VERSION ""

NS_ :

BS_:

BU_: ETH

BO_ 1332 VCFRONT_alertLog: 8 Vector__XXX
 SG_ VCFRONT_alertID M : 0|10@1+ (1,0) [0|0] "" Vector__XXX
 SG_ VCFRONT_a583_switch1State m583 : 24|3@1+ (1,0) [0|0] "" Vector__XXX
 SG_ VCFRONT_a584_switch1Voltage m584 : 24|9@1+ (10,0) [0|0] "" Vector__XXX
 SG_ VCFRONT_a587_batterySMState m587 : 24|4@1+ (1,0) [0|0] "" Vector__XXX
 SG_ VCFRONT_a588_vcleftATerm m588 : 24|16@1+ (50,0) [0|0] "" Vector__XXX
 SG_ VCFRONT_a590_vcrightATerm m590 : 24|16@1+ (50,0) [0|0] "" Vector__XXX
 SG_ VCFRONT_a592_vcleftCutoffATerm m592 : 24|16@1+ (50,0) [0|0] "" Vector__XXX
 SG_ VCFRONT_a594_minOffsetFusionSession m594 : 24|8@1- (0.001,0) [0|0] "" Vector__XXX
 SG_ VCFRONT_a595_batterySMState m595 : 24|4@1+ (1,0) [0|0] "" Vector__XXX
 SG_ VCFRONT_a596_vcrightCutoffATerm m596 : 24|16@1+ (50,0) [0|0] "" Vector__XXX
 SG_ VCFRONT_a599_initialLVBatteryType m599 : 24|3@1+ (1,0) [0|0] "" Vector__XXX
 SG_ VCFRONT_a600_batterySMState m600 : 24|4@1+ (1,0) [0|0] "" Vector__XXX
 SG_ VCFRONT_a611_tempCoolantRadOutletEst m611 : 24|6@1+ (1,20) [0|0] "" Vector__XXX
 SG_ VCFRONT_a614_ptPumpFault m614 : 24|1@1+ (1,0) [0|0] "" Vector__XXX
 SG_ VCFRONT_a618_evapInTemp m618 : 24|6@1+ (1,0) [0|0] "" Vector__XXX
 SG_ VCFRONT_a626_elevatedDcrThreshold m626 : 24|4@1+ (0.5,12) [0|0] "" Vector__XXX
 SG_ VCFRONT_a628_lastNominalTemp m628 : 24|8@1+ (0.5,-20) [0|0] "" Vector__XXX
 SG_ VCFRONT_a635_readyToSleepFailed m635 : 24|1@1+ (1,0) [0|0] "" Vector__XXX
 SG_ VCFRONT_a644_washpumpCycleSuccessEstimate m644 : 24|1@1+ (1,0) [0|0] "" Vector__XXX
 SG_ VCFRONT_a645_averageUnprimedFluidCurrent m645 : 24|8@1- (0.0984251968503937,5.807086614173229) [0|0] "" Vector__XXX
 SG_ VCFRONT_a646_timeDeltaBetweenComputations_min m646 : 24|14@1+ (1,0) [0|0] "" Vector__XXX
 SG_ VCFRONT_a663_hcmlGroupsHighWaterMarkPercent_IC400 m663 : 24|5@1+ (3.225806451612903,0) [0|0] "" Vector__XXX
 SG_ VCFRONT_a664_hcmrGroupsHighWaterMarkPercent_IC400 m664 : 24|5@1+ (3.225806451612903,0) [0|0] "" Vector__XXX
 SG_ VCFRONT_a665_isClearingFaults m665 : 24|1@1+ (1,0) [0|0] "" Vector__XXX
 SG_ VCFRONT_a666_isClearingFaults m666 : 24|1@1+ (1,0) [0|0] "" Vector__XXX
 SG_ VCFRONT_a667_country m667 : 24|16@1+ (1,0) [0|0] "" Vector__XXX
 SG_ VCFRONT_a668_country m668 : 24|16@1+ (1,0) [0|0] "" Vector__XXX
 SG_ VCFRONT_a009_abortedFaultTimeout m9 : 25|1@1+ (1,0) [0|0] "" Vector__XXX
 SG_ VCFRONT_a021_Task1000msLate m21 : 25|1@1+ (1,0) [0|0] "" Vector__XXX
 SG_ VCFRONT_a038_busMaster m38 : 25|4@1+ (1,0) [0|0] "" Vector__XXX
 SG_ VCFRONT_a047_Xres m47 : 25|1@1+ (1,0) [0|0] "" Vector__XXX
 SG_ VCFRONT_a089_VEH_party3 m89 : 25|1@1+ (1,0) [0|0] "" Vector__XXX
 SG_ VCFRONT_a098_PARTY_torque m98 : 25|1@1+ (1,0) [0|0] "" Vector__XXX
 SG_ VCFRONT_a104_PARTY_gpsAccuracies m104 : 25|1@1+ (1,0) [0|0] "" Vector__XXX
 SG_ VCFRONT_a107_PT_socStatus m107 : 25|1@1+ (1,0) [0|0] "" Vector__XXX
 SG_ VCFRONT_a108_PT_temperature m108 : 25|1@1+ (1,0) [0|0] "" Vector__XXX
 SG_ VCFRONT_a109_BDY_inertial2 m109 : 25|1@1+ (1,0) [0|0] "" Vector__XXX
 SG_ VCFRONT_a110_VEH_gearControl m110 : 25|1@1+ (1,0) [0|0] "" Vector__XXX
 SG_ VCFRONT_a111_VEH_seatStatus m111 : 25|1@1+ (1,0) [0|0] "" Vector__XXX
 SG_ VCFRONT_a112_PARTY_status m112 : 25|1@1+ (1,0) [0|0] "" Vector__XXX
 SG_ VCFRONT_a113_VEH_chassisControl m113 : 25|1@1+ (1,0) [0|0] "" Vector__XXX
 SG_ VCFRONT_a114_VEH_wheelRotation m114 : 25|1@1+ (1,0) [0|0] "" Vector__XXX
 SG_ VCFRONT_a116_VEH_seatHeatStatus m116 : 25|1@1+ (1,0) [0|0] "" Vector__XXX
 SG_ VCFRONT_a117_VEH_seatStatus m117 : 25|1@1+ (1,0) [0|0] "" Vector__XXX
 SG_ VCFRONT_a118_VEH_systemStatus m118 : 25|1@1+ (1,0) [0|0] "" Vector__XXX
 SG_ VCFRONT_a120_PARTY_status m120 : 25|1@1+ (1,0) [0|0] "" Vector__XXX
 SG_ VCFRONT_a142_isCoilOpenY m142 : 25|1@1+ (1,0) [0|0] "" Vector__XXX
 SG_ VCFRONT_a153_trunkOpen m153 : 25|1@1+ (1,0) [0|0] "" Vector__XXX
 SG_ VCFRONT_a160_faultValveEXV m160 : 25|1@1+ (1,0) [0|0] "" Vector__XXX
 SG_ VCFRONT_a161_tempSnsFaultIPM1 m161 : 25|1@1+ (1,0) [0|0] "" Vector__XXX
 SG_ VCFRONT_a171_PCSCPU2 m171 : 25|1@1+ (1,0) [0|0] "" Vector__XXX
 SG_ VCFRONT_a178_notRunInverterHot m178 : 25|1@1+ (1,0) [0|0] "" Vector__XXX
 SG_ VCFRONT_a182_factoryMode m182 : 25|1@1+ (1,0) [0|0] "" Vector__XXX
 SG_ VCFRONT_a183_factoryMode m183 : 25|1@1+ (1,0) [0|0] "" Vector__XXX
 SG_ VCFRONT_a187_partyBusRetryCount m187 : 25|9@1+ (1,0) [0|0] "" Vector__XXX
 SG_ VCFRONT_a191_IBSVoltage m191 : 25|8@1+ (0.08741903380905883,0) [0|0] "" Vector__XXX
 SG_ VCFRONT_a192_hvcEFuseStable m192 : 25|1@1+ (1,0) [0|0] "" Vector__XXX
 SG_ VCFRONT_a216_vcrightFastBlowDebounceImminent m216 : 25|1@1+ (1,0) [0|0] "" Vector__XXX
 SG_ VCFRONT_a284_isCoilOpenY m284 : 25|1@1+ (1,0) [0|0] "" Vector__XXX
 SG_ VCFRONT_a285_isCoilOpenY m285 : 25|1@1+ (1,0) [0|0] "" Vector__XXX
 SG_ VCFRONT_a286_isCoilOpenY m286 : 25|1@1+ (1,0) [0|0] "" Vector__XXX
 SG_ VCFRONT_a287_isCoilOpenY m287 : 25|1@1+ (1,0) [0|0] "" Vector__XXX
 SG_ VCFRONT_a288_isCoilOpenY m288 : 25|1@1+ (1,0) [0|0] "" Vector__XXX
 SG_ VCFRONT_a289_isCoilOpenY m289 : 25|1@1+ (1,0) [0|0] "" Vector__XXX
 SG_ VCFRONT_a365_heatPumpFlowRequest m365 : 25|1@1+ (1,0) [0|0] "" Vector__XXX
 SG_ VCFRONT_a366_sentryModeActive m366 : 25|1@1+ (1,0) [0|0] "" Vector__XXX
 SG_ VCFRONT_a427_endingSoc m427 : 25|9@1+ (0.2,0) [0|0] "" Vector__XXX
 SG_ VCFRONT_a446_compStandbySelfNotReady m446 : 25|1@1+ (1,0) [0|0] "" Vector__XXX
 SG_ VCFRONT_a447_lccSolenoidCompromised m447 : 25|1@1+ (1,0) [0|0] "" Vector__XXX
 SG_ VCFRONT_a462_HardwareOCLevel2 m462 : 25|1@1+ (1,0) [0|0] "" Vector__XXX
 SG_ VCFRONT_a476_FRM10_timedOut m476 : 25|1@1+ (1,0) [0|0] "" Vector__XXX
 SG_ VCFRONT_a477_cell2Voltage m477 : 25|9@1+ (0.01,0) [0|0] "" Vector__XXX
 SG_ VCFRONT_a480_unexpectedLock m480 : 25|1@1+ (1,0) [0|0] "" Vector__XXX
 SG_ VCFRONT_a481_outputOn m481 : 25|1@1+ (1,0) [0|0] "" Vector__XXX
 SG_ VCFRONT_a495_frunkOpen m495 : 25|1@1+ (1,0) [0|0] "" Vector__XXX
 SG_ VCFRONT_a499_DIFlowReq m499 : 25|1@1+ (1,0) [0|0] "" Vector__XXX
 SG_ VCFRONT_a529_disconnectedBatteryRunExpended m529 : 25|1@1+ (1,0) [0|0] "" Vector__XXX
 SG_ VCFRONT_a541_ChargeCurrentLimit m541 : 25|10@1+ (0.05,0) [0|0] "" Vector__XXX
 SG_ VCFRONT_a565_trunkOpen m565 : 25|1@1+ (1,0) [0|0] "" Vector__XXX
 SG_ VCFRONT_a614_ranFanRpm m614 : 25|1@1+ (1,0) [0|0] "" Vector__XXX
 SG_ VCFRONT_a627_cell2Voltage m627 : 25|9@1+ (0.01,0) [0|0] "" Vector__XXX
 SG_ VCFRONT_a635_requestSleepFailed m635 : 25|1@1+ (1,0) [0|0] "" Vector__XXX
 SG_ VCFRONT_a644_fluidLowEstimate m644 : 25|1@1+ (1,0) [0|0] "" Vector__XXX
 SG_ VCFRONT_a009_abortedRetryLimited m9 : 26|1@1+ (1,0) [0|0] "" Vector__XXX
 SG_ VCFRONT_a021_Task1000msStarved m21 : 26|1@1+ (1,0) [0|0] "" Vector__XXX
 SG_ VCFRONT_a047_Bodvddd m47 : 26|1@1+ (1,0) [0|0] "" Vector__XXX
 SG_ VCFRONT_a098_PT_thermalControl m98 : 26|1@1+ (1,0) [0|0] "" Vector__XXX
 SG_ VCFRONT_a104_CH_status m104 : 26|1@1+ (1,0) [0|0] "" Vector__XXX
 SG_ VCFRONT_a107_VEH_socStatus m107 : 26|1@1+ (1,0) [0|0] "" Vector__XXX
 SG_ VCFRONT_a108_PT_thermalControl m108 : 26|1@1+ (1,0) [0|0] "" Vector__XXX
 SG_ VCFRONT_a109_BDY_status m109 : 26|1@1+ (1,0) [0|0] "" Vector__XXX
 SG_ VCFRONT_a110_VEH_canLogAvailability m110 : 26|1@1+ (1,0) [0|0] "" Vector__XXX
 SG_ VCFRONT_a111_PARTY_status m111 : 26|1@1+ (1,0) [0|0] "" Vector__XXX
 SG_ VCFRONT_a112_CH_status m112 : 26|1@1+ (1,0) [0|0] "" Vector__XXX
 SG_ VCFRONT_a113_VEH_trackModeSettings m113 : 26|1@1+ (1,0) [0|0] "" Vector__XXX
 SG_ VCFRONT_a114_PARTY_brakeTorque m114 : 26|1@1+ (1,0) [0|0] "" Vector__XXX
 SG_ VCFRONT_a116_VEH_restraintStatus m116 : 26|1@1+ (1,0) [0|0] "" Vector__XXX
 SG_ VCFRONT_a117_BDY_falconSwitchStatus m117 : 26|1@1+ (1,0) [0|0] "" Vector__XXX
 SG_ VCFRONT_a118_PARTY_LVPowerState m118 : 26|1@1+ (1,0) [0|0] "" Vector__XXX
 SG_ VCFRONT_a120_PT_speed m120 : 26|1@1+ (1,0) [0|0] "" Vector__XXX
 SG_ VCFRONT_a142_isCoilShortXPGnd m142 : 26|1@1+ (1,0) [0|0] "" Vector__XXX
 SG_ VCFRONT_a146_RPMTarget m146 : 26|10@1+ (10,0) [0|0] "" Vector__XXX
 SG_ VCFRONT_a147_RPMTarget m147 : 26|10@1+ (10,0) [0|0] "" Vector__XXX
 SG_ VCFRONT_a148_RPMTarget m148 : 26|10@1+ (10,0) [0|0] "" Vector__XXX
 SG_ VCFRONT_a150_RPMTarget m150 : 26|10@1+ (10,0) [0|0] "" Vector__XXX
 SG_ VCFRONT_a151_RPMTarget m151 : 26|10@1+ (10,0) [0|0] "" Vector__XXX
 SG_ VCFRONT_a152_RPMTarget m152 : 26|10@1+ (10,0) [0|0] "" Vector__XXX
 SG_ VCFRONT_a153_inTransportMode m153 : 26|1@1+ (1,0) [0|0] "" Vector__XXX
 SG_ VCFRONT_a160_faultValveEvapSol m160 : 26|1@1+ (1,0) [0|0] "" Vector__XXX
 SG_ VCFRONT_a161_tempSnsFaultIPM2 m161 : 26|1@1+ (1,0) [0|0] "" Vector__XXX
 SG_ VCFRONT_a171_DI m171 : 26|1@1+ (1,0) [0|0] "" Vector__XXX
 SG_ VCFRONT_a178_notRunAmbientOutOfBounds m178 : 26|1@1+ (1,0) [0|0] "" Vector__XXX
 SG_ VCFRONT_a182_serviceMode m182 : 26|1@1+ (1,0) [0|0] "" Vector__XXX
 SG_ VCFRONT_a183_serviceMode m183 : 26|1@1+ (1,0) [0|0] "" Vector__XXX
 SG_ VCFRONT_a192_replaceLVBattery m192 : 26|1@1+ (1,0) [0|0] "" Vector__XXX
 SG_ VCFRONT_a216_vcrightStaticImminent m216 : 26|1@1+ (1,0) [0|0] "" Vector__XXX
 SG_ VCFRONT_a228_RPMTarget m228 : 26|10@1+ (10,0) [0|0] "" Vector__XXX
 SG_ VCFRONT_a229_RPMTarget m229 : 26|10@1+ (10,0) [0|0] "" Vector__XXX
 SG_ VCFRONT_a230_RPMTarget m230 : 26|10@1+ (10,0) [0|0] "" Vector__XXX
 SG_ VCFRONT_a249_tempCoolantPTInlet m249 : 26|11@1+ (0.125,-40) [0|0] "" Vector__XXX
 SG_ VCFRONT_a254_RPMTarget m254 : 26|10@1+ (10,0) [0|0] "" Vector__XXX
 SG_ VCFRONT_a255_RPMTarget m255 : 26|10@1+ (10,0) [0|0] "" Vector__XXX
 SG_ VCFRONT_a284_isCoilShortXPGnd m284 : 26|1@1+ (1,0) [0|0] "" Vector__XXX
 SG_ VCFRONT_a285_isCoilShortXPGnd m285 : 26|1@1+ (1,0) [0|0] "" Vector__XXX
 SG_ VCFRONT_a286_isCoilShortXPGnd m286 : 26|1@1+ (1,0) [0|0] "" Vector__XXX
 SG_ VCFRONT_a287_isCoilShortXPGnd m287 : 26|1@1+ (1,0) [0|0] "" Vector__XXX
 SG_ VCFRONT_a288_isCoilShortXPGnd m288 : 26|1@1+ (1,0) [0|0] "" Vector__XXX
 SG_ VCFRONT_a289_isCoilShortXPGnd m289 : 26|1@1+ (1,0) [0|0] "" Vector__XXX
 SG_ VCFRONT_a352_maxCurrent m352 : 26|8@1+ (0.1,0) [0|0] "" Vector__XXX
 SG_ VCFRONT_a365_sentryModeActive m365 : 26|1@1+ (1,0) [0|0] "" Vector__XXX
 SG_ VCFRONT_a366_hvacConditioning m366 : 26|1@1+ (1,0) [0|0] "" Vector__XXX
 SG_ VCFRONT_a373_tempSuperheatTarget m373 : 26|10@1+ (0.1,0) [0|0] "" Vector__XXX
 SG_ VCFRONT_a416_brickVoltageMax m416 : 26|10@1+ (0.005,0) [0|0] "" Vector__XXX
 SG_ VCFRONT_a417_brickVoltageMax m417 : 26|10@1+ (0.005,0) [0|0] "" Vector__XXX
 SG_ VCFRONT_a418_brickVoltageMax m418 : 26|10@1+ (0.005,0) [0|0] "" Vector__XXX
 SG_ VCFRONT_a419_brickVoltageMax m419 : 26|10@1+ (0.005,0) [0|0] "" Vector__XXX
 SG_ VCFRONT_a420_partyStopReason m420 : 26|3@1+ (1,0) [0|0] "" Vector__XXX
 SG_ VCFRONT_a423_brickVoltageMax m423 : 26|10@1+ (0.005,0) [0|0] "" Vector__XXX
 SG_ VCFRONT_a424_brickVoltageMax m424 : 26|10@1+ (0.005,0) [0|0] "" Vector__XXX
 SG_ VCFRONT_a446_compStandbyRefrigNotOk m446 : 26|1@1+ (1,0) [0|0] "" Vector__XXX
 SG_ VCFRONT_a447_refrigerantSystemCompromised m447 : 26|1@1+ (1,0) [0|0] "" Vector__XXX
 SG_ VCFRONT_a462_ChrgOCLevel1 m462 : 26|1@1+ (1,0) [0|0] "" Vector__XXX
 SG_ VCFRONT_a472_worstCaseRequiredRange m472 : 26|10@1+ (1,0) [0|0] "" Vector__XXX
 SG_ VCFRONT_a473_worstCaseRequiredRange m473 : 26|10@1+ (1,0) [0|0] "" Vector__XXX
 SG_ VCFRONT_a474_ssl100Bank6Status m474 : 26|2@1+ (1,0) [0|0] "" Vector__XXX
 SG_ VCFRONT_a475_ssl100Bank6Status m475 : 26|2@1+ (1,0) [0|0] "" Vector__XXX
 SG_ VCFRONT_a476_FRM11_timedOut m476 : 26|1@1+ (1,0) [0|0] "" Vector__XXX
 SG_ VCFRONT_a480_disableOutputFault m480 : 26|1@1+ (1,0) [0|0] "" Vector__XXX
 SG_ VCFRONT_a481_VDSDiff m481 : 26|8@1+ (1,0) [0|0] "" Vector__XXX
 SG_ VCFRONT_a487_previouslyReportedPosition m487 : 26|10@1+ (1,0) [0|0] "" Vector__XXX
 SG_ VCFRONT_a491_previouslyReportedPosition m491 : 26|10@1+ (1,0) [0|0] "" Vector__XXX
 SG_ VCFRONT_a495_externalPowerSupply m495 : 26|1@1+ (1,0) [0|0] "" Vector__XXX
 SG_ VCFRONT_a503_brickVoltageMax m503 : 26|10@1+ (0.005,0) [0|0] "" Vector__XXX
 SG_ VCFRONT_a527_cell2Voltage m527 : 26|10@1+ (0.01,0) [0|0] "" Vector__XXX
 SG_ VCFRONT_a555_cell2Voltage m555 : 26|10@1+ (0.01,0) [0|0] "" Vector__XXX
 SG_ VCFRONT_a558_aimedHorizontalPosition m558 : 26|10@1+ (1,0) [0|0] "" Vector__XXX
 SG_ VCFRONT_a561_ambientTemperature m561 : 26|6@1+ (4,0) [0|0] "" Vector__XXX
 SG_ VCFRONT_a562_ambientTemperature m562 : 26|6@1+ (4,0) [0|0] "" Vector__XXX
 SG_ VCFRONT_a564_aimedHorizontalPosition m564 : 26|10@1+ (1,0) [0|0] "" Vector__XXX
 SG_ VCFRONT_a565_inTransportMode m565 : 26|1@1+ (1,0) [0|0] "" Vector__XXX
 SG_ VCFRONT_a605_sleepBypassVoltage m605 : 26|10@1+ (0.1,0) [0|0] "" Vector__XXX
 SG_ VCFRONT_a614_radFanFault m614 : 26|1@1+ (1,0) [0|0] "" Vector__XXX
 SG_ VCFRONT_a634_ajar2OpeningDeltaV m634 : 26|10@1- (0.01,0) [0|0] "" Vector__XXX
 SG_ VCFRONT_a644_pumpPrimeDuration m644 : 26|10@1+ (9.775171065493646,0) [0|0] "" Vector__XXX
 SG_ VCFRONT_a661_headlampUndercurrentFault m661 : 26|1@1+ (1,0) [0|0] "" Vector__XXX
 SG_ VCFRONT_a662_headlampUndercurrentFault m662 : 26|1@1+ (1,0) [0|0] "" Vector__XXX
 SG_ VCFRONT_a669_hpMode m669 : 26|5@1+ (1,0) [0|0] "" Vector__XXX
 SG_ VCFRONT_a009_PdMax m9 : 27|5@1+ (1,0) [0|0] "" Vector__XXX
 SG_ VCFRONT_a021_Task1000msMissed m21 : 27|1@1+ (1,0) [0|0] "" Vector__XXX
 SG_ VCFRONT_a047_Bodvdda m47 : 27|1@1+ (1,0) [0|0] "" Vector__XXX
 SG_ VCFRONT_a098_PT_temperature m98 : 27|1@1+ (1,0) [0|0] "" Vector__XXX
 SG_ VCFRONT_a104_PARTY_status m104 : 27|1@1+ (1,0) [0|0] "" Vector__XXX
 SG_ VCFRONT_a107_VEH_packConfig m107 : 27|1@1+ (1,0) [0|0] "" Vector__XXX
 SG_ VCFRONT_a108_PARTY_motorStatus m108 : 27|1@1+ (1,0) [0|0] "" Vector__XXX
 SG_ VCFRONT_a109_VEH_inertial1 m109 : 27|1@1+ (1,0) [0|0] "" Vector__XXX
 SG_ VCFRONT_a110_CH_airbagCutoffStatus m110 : 27|1@1+ (1,0) [0|0] "" Vector__XXX
 SG_ VCFRONT_a111_CH_status m111 : 27|1@1+ (1,0) [0|0] "" Vector__XXX
 SG_ VCFRONT_a113_VEH_powertrainControl m113 : 27|1@1+ (1,0) [0|0] "" Vector__XXX
 SG_ VCFRONT_a114_PARTY_offsets m114 : 27|1@1+ (1,0) [0|0] "" Vector__XXX
 SG_ VCFRONT_a116_VEH_switchStatus m116 : 27|1@1+ (1,0) [0|0] "" Vector__XXX
 SG_ VCFRONT_a117_VEH_doorStatus m117 : 27|1@1+ (1,0) [0|0] "" Vector__XXX
 SG_ VCFRONT_a118_PARTY_outputPowerStatus m118 : 27|1@1+ (1,0) [0|0] "" Vector__XXX
 SG_ VCFRONT_a120_PT_systemStatus m120 : 27|1@1+ (1,0) [0|0] "" Vector__XXX
 SG_ VCFRONT_a142_isCoilShortXPVbb m142 : 27|1@1+ (1,0) [0|0] "" Vector__XXX
 SG_ VCFRONT_a153_anyClosureIsOpen m153 : 27|1@1+ (1,0) [0|0] "" Vector__XXX
 SG_ VCFRONT_a154_lastSilentWakeIBSCurrent m154 : 27|10@1+ (0.001953125,-1.59375) [0|0] "" Vector__XXX
 SG_ VCFRONT_a159_angleTarget m159 : 27|10@1+ (0.25,-10) [0|0] "" Vector__XXX
 SG_ VCFRONT_a160_highDischargePressureCutouts m160 : 27|1@1+ (1,0) [0|0] "" Vector__XXX
 SG_ VCFRONT_a161_tempSnsFaultCPU m161 : 27|1@1+ (1,0) [0|0] "" Vector__XXX
 SG_ VCFRONT_a171_DIS m171 : 27|1@1+ (1,0) [0|0] "" Vector__XXX
 SG_ VCFRONT_a178_isSummerPumpOut m178 : 27|1@1+ (1,0) [0|0] "" Vector__XXX
 SG_ VCFRONT_a182_transportMode m182 : 27|1@1+ (1,0) [0|0] "" Vector__XXX
 SG_ VCFRONT_a183_transportMode m183 : 27|1@1+ (1,0) [0|0] "" Vector__XXX
 SG_ VCFRONT_a192_BMS_MIA m192 : 27|1@1+ (1,0) [0|0] "" Vector__XXX
 SG_ VCFRONT_a216_vcrightDynamicImminent m216 : 27|1@1+ (1,0) [0|0] "" Vector__XXX
 SG_ VCFRONT_a284_isCoilShortXPVbb m284 : 27|1@1+ (1,0) [0|0] "" Vector__XXX
 SG_ VCFRONT_a285_isCoilShortXPVbb m285 : 27|1@1+ (1,0) [0|0] "" Vector__XXX
 SG_ VCFRONT_a286_isCoilShortXPVbb m286 : 27|1@1+ (1,0) [0|0] "" Vector__XXX
 SG_ VCFRONT_a287_isCoilShortXPVbb m287 : 27|1@1+ (1,0) [0|0] "" Vector__XXX
 SG_ VCFRONT_a288_isCoilShortXPVbb m288 : 27|1@1+ (1,0) [0|0] "" Vector__XXX
 SG_ VCFRONT_a289_isCoilShortXPVbb m289 : 27|1@1+ (1,0) [0|0] "" Vector__XXX
 SG_ VCFRONT_a310_maxTemp m310 : 27|11@1+ (0.125,-40) [0|0] "" Vector__XXX
 SG_ VCFRONT_a311_maxTemp m311 : 27|11@1+ (0.125,-40) [0|0] "" Vector__XXX
 SG_ VCFRONT_a312_maxTemp m312 : 27|11@1+ (0.125,-40) [0|0] "" Vector__XXX
 SG_ VCFRONT_a313_maxTemp m313 : 27|11@1+ (0.125,-40) [0|0] "" Vector__XXX
 SG_ VCFRONT_a314_maxTemp m314 : 27|11@1+ (0.125,-40) [0|0] "" Vector__XXX
 SG_ VCFRONT_a315_maxTemp m315 : 27|11@1+ (0.125,-40) [0|0] "" Vector__XXX
 SG_ VCFRONT_a316_maxTemp m316 : 27|11@1+ (0.125,-40) [0|0] "" Vector__XXX
 SG_ VCFRONT_a317_maxTemp m317 : 27|11@1+ (0.125,-40) [0|0] "" Vector__XXX
 SG_ VCFRONT_a318_maxTemp m318 : 27|11@1+ (0.125,-40) [0|0] "" Vector__XXX
 SG_ VCFRONT_a319_maxTemp m319 : 27|11@1+ (0.125,-40) [0|0] "" Vector__XXX
 SG_ VCFRONT_a320_maxTemp m320 : 27|11@1+ (0.125,-40) [0|0] "" Vector__XXX
 SG_ VCFRONT_a321_maxTemp m321 : 27|11@1+ (0.125,-40) [0|0] "" Vector__XXX
 SG_ VCFRONT_a322_maxTemp m322 : 27|11@1+ (0.125,-40) [0|0] "" Vector__XXX
 SG_ VCFRONT_a323_maxTemp m323 : 27|11@1+ (0.125,-40) [0|0] "" Vector__XXX
 SG_ VCFRONT_a324_maxTemp m324 : 27|11@1+ (0.125,-40) [0|0] "" Vector__XXX
 SG_ VCFRONT_a325_maxTemp m325 : 27|11@1+ (0.125,-40) [0|0] "" Vector__XXX
 SG_ VCFRONT_a365_hvacConditioning m365 : 27|1@1+ (1,0) [0|0] "" Vector__XXX
 SG_ VCFRONT_a366_coolantConditioning m366 : 27|1@1+ (1,0) [0|0] "" Vector__XXX
 SG_ VCFRONT_a390_blendType m390 : 27|2@1+ (1,0) [0|0] "" Vector__XXX
 SG_ VCFRONT_a446_compStandbyCoastDownMode m446 : 27|1@1+ (1,0) [0|0] "" Vector__XXX
 SG_ VCFRONT_a447_powertrainThermalFansCompromised m447 : 27|1@1+ (1,0) [0|0] "" Vector__XXX
 SG_ VCFRONT_a461_socByAhSaturated m461 : 27|10@1+ (0.1,0) [0|0] "" Vector__XXX
 SG_ VCFRONT_a462_ChrgOCLevel2 m462 : 27|1@1+ (1,0) [0|0] "" Vector__XXX
 SG_ VCFRONT_a476_FRM12_timedOut m476 : 27|1@1+ (1,0) [0|0] "" Vector__XXX
 SG_ VCFRONT_a480_vsUndervoltage m480 : 27|1@1+ (1,0) [0|0] "" Vector__XXX
 SG_ VCFRONT_a507_headlampFailedToFinishCalibration m507 : 27|1@1+ (1,0) [0|0] "" Vector__XXX
 SG_ VCFRONT_a524_headlampFailedToFinishCalibration m524 : 27|1@1+ (1,0) [0|0] "" Vector__XXX
 SG_ VCFRONT_a525_serviceMode m525 : 27|1@1+ (1,0) [0|0] "" Vector__XXX
 SG_ VCFRONT_a565_anyClosureIsOpen m565 : 27|1@1+ (1,0) [0|0] "" Vector__XXX
 SG_ VCFRONT_a583_switch2State m583 : 27|3@1+ (1,0) [0|0] "" Vector__XXX
 SG_ VCFRONT_a599_serviceMode m599 : 27|1@1+ (1,0) [0|0] "" Vector__XXX
 SG_ VCFRONT_a614_battPumpDryRun m614 : 27|1@1+ (1,0) [0|0] "" Vector__XXX
 SG_ VCFRONT_a661_headlampOvercurrentFault m661 : 27|1@1+ (1,0) [0|0] "" Vector__XXX
 SG_ VCFRONT_a662_headlampOvercurrentFault m662 : 27|1@1+ (1,0) [0|0] "" Vector__XXX
 SG_ VCFRONT_a047_Bodvccd m47 : 28|1@1+ (1,0) [0|0] "" Vector__XXX
 SG_ VCFRONT_a058_current m58 : 28|11@1+ (0.1,0) [0|0] "" Vector__XXX
 SG_ VCFRONT_a059_resistanceEstimate m59 : 28|12@1+ (0.00244,0) [0|0] "" Vector__XXX
 SG_ VCFRONT_a098_PARTY_motorStatus m98 : 28|1@1+ (1,0) [0|0] "" Vector__XXX
 SG_ VCFRONT_a104_PARTY_steeringControl m104 : 28|1@1+ (1,0) [0|0] "" Vector__XXX
 SG_ VCFRONT_a107_VEH_energyStatus m107 : 28|1@1+ (1,0) [0|0] "" Vector__XXX
 SG_ VCFRONT_a108_VEH_motorStatus m108 : 28|1@1+ (1,0) [0|0] "" Vector__XXX
 SG_ VCFRONT_a109_VEH_inertial2 m109 : 28|1@1+ (1,0) [0|0] "" Vector__XXX
 SG_ VCFRONT_a110_CH_carConfig m110 : 28|1@1+ (1,0) [0|0] "" Vector__XXX
 SG_ VCFRONT_a113_VEH_vehicleModes m113 : 28|1@1+ (1,0) [0|0] "" Vector__XXX
 SG_ VCFRONT_a114_BDY_offsets m114 : 28|1@1+ (1,0) [0|0] "" Vector__XXX
 SG_ VCFRONT_a116_VEH_logging1Hz m116 : 28|1@1+ (1,0) [0|0] "" Vector__XXX
 SG_ VCFRONT_a117_VEH_doorStatus2 m117 : 28|1@1+ (1,0) [0|0] "" Vector__XXX
 SG_ VCFRONT_a118_PARTY_vehicleTime m118 : 28|1@1+ (1,0) [0|0] "" Vector__XXX
 SG_ VCFRONT_a120_PARTY_vehicleEstimates m120 : 28|1@1+ (1,0) [0|0] "" Vector__XXX
 SG_ VCFRONT_a142_isCoilShortXNGnd m142 : 28|1@1+ (1,0) [0|0] "" Vector__XXX
 SG_ VCFRONT_a153_driverPresent m153 : 28|1@1+ (1,0) [0|0] "" Vector__XXX
 SG_ VCFRONT_a160_highDischargeTempCutouts m160 : 28|1@1+ (1,0) [0|0] "" Vector__XXX
 SG_ VCFRONT_a161_currentSnsError m161 : 28|1@1+ (1,0) [0|0] "" Vector__XXX
 SG_ VCFRONT_a171_PM m171 : 28|1@1+ (1,0) [0|0] "" Vector__XXX
 SG_ VCFRONT_a178_isWinterPumpOut m178 : 28|1@1+ (1,0) [0|0] "" Vector__XXX
 SG_ VCFRONT_a180_notEnoughPowerForSupport m180 : 28|1@1+ (1,0) [0|0] "" Vector__XXX
 SG_ VCFRONT_a182_frunkOpen m182 : 28|1@1+ (1,0) [0|0] "" Vector__XXX
 SG_ VCFRONT_a183_frunkOpen m183 : 28|1@1+ (1,0) [0|0] "" Vector__XXX
 SG_ VCFRONT_a190_timeouts m190 : 28|16@1+ (1,0) [0|0] "" Vector__XXX
 SG_ VCFRONT_a192_PCS_MIA m192 : 28|1@1+ (1,0) [0|0] "" Vector__XXX
 SG_ VCFRONT_a195_serviceMode m195 : 28|1@1+ (1,0) [0|0] "" Vector__XXX
 SG_ VCFRONT_a196_disconnectedBatteryTestCurrent m196 : 28|12@1+ (0.004884004884004884,-10) [0|0] "" Vector__XXX
 SG_ VCFRONT_a248_IBSVoltage m248 : 28|12@1+ (0.005443676098,0) [0|0] "" Vector__XXX
 SG_ VCFRONT_a258_IBSTemp m258 : 28|16@1- (0.01,0) [0|0] "" Vector__XXX
 SG_ VCFRONT_a260_IBSAh m260 : 28|12@1- (0.1,0) [0|0] "" Vector__XXX
 SG_ VCFRONT_a284_isCoilShortXNGnd m284 : 28|1@1+ (1,0) [0|0] "" Vector__XXX
 SG_ VCFRONT_a285_isCoilShortXNGnd m285 : 28|1@1+ (1,0) [0|0] "" Vector__XXX
 SG_ VCFRONT_a286_isCoilShortXNGnd m286 : 28|1@1+ (1,0) [0|0] "" Vector__XXX
 SG_ VCFRONT_a287_isCoilShortXNGnd m287 : 28|1@1+ (1,0) [0|0] "" Vector__XXX
 SG_ VCFRONT_a288_isCoilShortXNGnd m288 : 28|1@1+ (1,0) [0|0] "" Vector__XXX
 SG_ VCFRONT_a289_isCoilShortXNGnd m289 : 28|1@1+ (1,0) [0|0] "" Vector__XXX
 SG_ VCFRONT_a334_avgCurrent m334 : 28|12@1+ (0.1,0) [0|0] "" Vector__XXX
 SG_ VCFRONT_a335_avgCurrent m335 : 28|12@1+ (0.1,0) [0|0] "" Vector__XXX
 SG_ VCFRONT_a336_avgCurrent m336 : 28|12@1+ (0.1,0) [0|0] "" Vector__XXX
 SG_ VCFRONT_a337_avgCurrent m337 : 28|12@1+ (0.1,0) [0|0] "" Vector__XXX
 SG_ VCFRONT_a338_avgCurrent m338 : 28|12@1+ (0.1,0) [0|0] "" Vector__XXX
 SG_ VCFRONT_a339_avgCurrent m339 : 28|12@1+ (0.1,0) [0|0] "" Vector__XXX
 SG_ VCFRONT_a340_avgCurrent m340 : 28|12@1+ (0.1,0) [0|0] "" Vector__XXX
 SG_ VCFRONT_a341_avgCurrent m341 : 28|12@1+ (0.1,0) [0|0] "" Vector__XXX
 SG_ VCFRONT_a342_avgCurrent m342 : 28|12@1+ (0.1,0) [0|0] "" Vector__XXX
 SG_ VCFRONT_a343_avgCurrent m343 : 28|12@1+ (0.1,0) [0|0] "" Vector__XXX
 SG_ VCFRONT_a344_avgCurrent m344 : 28|12@1+ (0.1,0) [0|0] "" Vector__XXX
 SG_ VCFRONT_a345_avgCurrent m345 : 28|12@1+ (0.1,0) [0|0] "" Vector__XXX
 SG_ VCFRONT_a346_avgCurrent m346 : 28|12@1+ (0.1,0) [0|0] "" Vector__XXX
 SG_ VCFRONT_a347_avgCurrent m347 : 28|12@1+ (0.1,0) [0|0] "" Vector__XXX
 SG_ VCFRONT_a348_avgCurrent m348 : 28|12@1+ (0.1,0) [0|0] "" Vector__XXX
 SG_ VCFRONT_a349_avgCurrent m349 : 28|12@1+ (0.1,0) [0|0] "" Vector__XXX
 SG_ VCFRONT_a359_IBSAh m359 : 28|12@1- (0.1,0) [0|0] "" Vector__XXX
 SG_ VCFRONT_a365_coolantConditioning m365 : 28|1@1+ (1,0) [0|0] "" Vector__XXX
 SG_ VCFRONT_a366_chargeCableUnplugged m366 : 28|1@1+ (1,0) [0|0] "" Vector__XXX
 SG_ VCFRONT_a370_IBSAh m370 : 28|12@1- (0.1,0) [0|0] "" Vector__XXX
 SG_ VCFRONT_a379_IBSTemp m379 : 28|10@1+ (0.1,-10) [0|0] "" Vector__XXX
 SG_ VCFRONT_a402_failureToPrechargeRisk m402 : 28|1@1+ (1,0) [0|0] "" Vector__XXX
 SG_ VCFRONT_a407_avgIntervalCurrent m407 : 28|5@1+ (1,-31) [0|0] "" Vector__XXX
 SG_ VCFRONT_a446_compStandbyMultiplePdCutouts m446 : 28|1@1+ (1,0) [0|0] "" Vector__XXX
 SG_ VCFRONT_a447_refrigDischargePressCompromised m447 : 28|1@1+ (1,0) [0|0] "" Vector__XXX
 SG_ VCFRONT_a462_MOSFETOTLevel1 m462 : 28|1@1+ (1,0) [0|0] "" Vector__XXX
 SG_ VCFRONT_a474_ssl100Bank7Status m474 : 28|2@1+ (1,0) [0|0] "" Vector__XXX
 SG_ VCFRONT_a475_ssl100Bank7Status m475 : 28|2@1+ (1,0) [0|0] "" Vector__XXX
 SG_ VCFRONT_a476_factoryMode m476 : 28|1@1+ (1,0) [0|0] "" Vector__XXX
 SG_ VCFRONT_a478_bmsState m478 : 28|4@1+ (1,0) [0|0] "" Vector__XXX
 SG_ VCFRONT_a479_vehiclePowerState m479 : 28|2@1+ (1,0) [0|0] "" Vector__XXX
 SG_ VCFRONT_a480_hardShort m480 : 28|1@1+ (1,0) [0|0] "" Vector__XXX
 SG_ VCFRONT_a482_calibrationCycles m482 : 28|2@1+ (1,0) [0|0] "" Vector__XXX
 SG_ VCFRONT_a485_calibrationCycles m485 : 28|2@1+ (1,0) [0|0] "" Vector__XXX
 SG_ VCFRONT_a525_factoryGated m525 : 28|1@1+ (1,0) [0|0] "" Vector__XXX
 SG_ VCFRONT_a565_driverPresent m565 : 28|1@1+ (1,0) [0|0] "" Vector__XXX
 SG_ VCFRONT_a587_LVBMS_packCurrent m587 : 28|12@1+ (0.2,-600) [0|0] "" Vector__XXX
 SG_ VCFRONT_a595_LVBMS_packVoltage m595 : 28|10@1+ (0.1,-1) [0|0] "" Vector__XXX
 SG_ VCFRONT_a599_factoryGated m599 : 28|1@1+ (1,0) [0|0] "" Vector__XXX
 SG_ VCFRONT_a600_LVBMS_packCurrent m600 : 28|12@1+ (0.2,-600) [0|0] "" Vector__XXX
 SG_ VCFRONT_a614_ptPumpDryRun m614 : 28|1@1+ (1,0) [0|0] "" Vector__XXX
 SG_ VCFRONT_a626_avgIntervalCurrent m626 : 28|5@1+ (1,-31) [0|0] "" Vector__XXX
 SG_ VCFRONT_a697_calibratedHorizontalPositionHCML m697 : 28|10@1+ (1,0) [0|0] "" Vector__XXX
 SG_ VCFRONT_a698_calibratedHorizontalPositionHCMR m698 : 28|10@1+ (1,0) [0|0] "" Vector__XXX
 SG_ VCFRONT_a047_Ovdvddd m47 : 29|1@1+ (1,0) [0|0] "" Vector__XXX
 SG_ VCFRONT_a098_VEH_motorStatus m98 : 29|1@1+ (1,0) [0|0] "" Vector__XXX
 SG_ VCFRONT_a104_CH_steeringControl m104 : 29|1@1+ (1,0) [0|0] "" Vector__XXX
 SG_ VCFRONT_a107_VEH_chargeInfo m107 : 29|1@1+ (1,0) [0|0] "" Vector__XXX
 SG_ VCFRONT_a108_CH_torque m108 : 29|1@1+ (1,0) [0|0] "" Vector__XXX
 SG_ VCFRONT_a109_CH_inertial1 m109 : 29|1@1+ (1,0) [0|0] "" Vector__XXX
 SG_ VCFRONT_a110_CH_carState m110 : 29|1@1+ (1,0) [0|0] "" Vector__XXX
 SG_ VCFRONT_a113_VEH_driverProfileRecall m113 : 29|1@1+ (1,0) [0|0] "" Vector__XXX
 SG_ VCFRONT_a114_BDY_party3 m114 : 29|1@1+ (1,0) [0|0] "" Vector__XXX
 SG_ VCFRONT_a116_VEH_seatStatus2 m116 : 29|1@1+ (1,0) [0|0] "" Vector__XXX
 SG_ VCFRONT_a117_VEH_windowStatus m117 : 29|1@1+ (1,0) [0|0] "" Vector__XXX
 SG_ VCFRONT_a118_VEH_thermalCommand m118 : 29|1@1+ (1,0) [0|0] "" Vector__XXX
 SG_ VCFRONT_a120_VEH_aggregatedAxleSpeed m120 : 29|1@1+ (1,0) [0|0] "" Vector__XXX
 SG_ VCFRONT_a142_isCoilShortXNVbb m142 : 29|1@1+ (1,0) [0|0] "" Vector__XXX
 SG_ VCFRONT_a153_brakePressed m153 : 29|1@1+ (1,0) [0|0] "" Vector__XXX
 SG_ VCFRONT_a161_selfTestFailCPU m161 : 29|1@1+ (1,0) [0|0] "" Vector__XXX
 SG_ VCFRONT_a162_lccExvFlow m162 : 29|7@1+ (1,0) [0|0] "" Vector__XXX
 SG_ VCFRONT_a171_PMS m171 : 29|1@1+ (1,0) [0|0] "" Vector__XXX
 SG_ VCFRONT_a178_notRunPsPdRange m178 : 29|1@1+ (1,0) [0|0] "" Vector__XXX
 SG_ VCFRONT_a180_pcsEFuseStable m180 : 29|1@1+ (1,0) [0|0] "" Vector__XXX
 SG_ VCFRONT_a182_packOverDischarged m182 : 29|1@1+ (1,0) [0|0] "" Vector__XXX
 SG_ VCFRONT_a183_packOverDischarged m183 : 29|1@1+ (1,0) [0|0] "" Vector__XXX
 SG_ VCFRONT_a192_HVBlockingMismatch m192 : 29|1@1+ (1,0) [0|0] "" Vector__XXX
 SG_ VCFRONT_a195_frunkOpen m195 : 29|1@1+ (1,0) [0|0] "" Vector__XXX
 SG_ VCFRONT_a275_bmbCommStatusTypeB m275 : 29|2@1+ (1,0) [0|0] "" Vector__XXX
 SG_ VCFRONT_a276_bmbCommStatusTypeB m276 : 29|2@1+ (1,0) [0|0] "" Vector__XXX
 SG_ VCFRONT_a284_isCoilShortXNVbb m284 : 29|1@1+ (1,0) [0|0] "" Vector__XXX
 SG_ VCFRONT_a285_isCoilShortXNVbb m285 : 29|1@1+ (1,0) [0|0] "" Vector__XXX
 SG_ VCFRONT_a286_isCoilShortXNVbb m286 : 29|1@1+ (1,0) [0|0] "" Vector__XXX
 SG_ VCFRONT_a287_isCoilShortXNVbb m287 : 29|1@1+ (1,0) [0|0] "" Vector__XXX
 SG_ VCFRONT_a288_isCoilShortXNVbb m288 : 29|1@1+ (1,0) [0|0] "" Vector__XXX
 SG_ VCFRONT_a289_isCoilShortXNVbb m289 : 29|1@1+ (1,0) [0|0] "" Vector__XXX
 SG_ VCFRONT_a365_chargeCableUnplugged m365 : 29|1@1+ (1,0) [0|0] "" Vector__XXX
 SG_ VCFRONT_a366_DIReportsCompleted m366 : 29|1@1+ (1,0) [0|0] "" Vector__XXX
 SG_ VCFRONT_a390_coolantMode m390 : 29|2@1+ (1,0) [0|0] "" Vector__XXX
 SG_ VCFRONT_a394_runTimeOffSetDetected m394 : 29|1@1+ (1,0) [0|0] "" Vector__XXX
 SG_ VCFRONT_a397_runTimeOffSetDetected m397 : 29|1@1+ (1,0) [0|0] "" Vector__XXX
 SG_ VCFRONT_a402_electricalDisconnectLVBattery m402 : 29|1@1+ (1,0) [0|0] "" Vector__XXX
 SG_ VCFRONT_a415_IBSCurrent m415 : 29|9@1- (0.5,0) [0|0] "" Vector__XXX
 SG_ VCFRONT_a420_partyStaticSongSelection m420 : 29|3@1+ (1,0) [0|0] "" Vector__XXX
 SG_ VCFRONT_a446_compStandbyShowroomMode m446 : 29|1@1+ (1,0) [0|0] "" Vector__XXX
 SG_ VCFRONT_a447_refrigeDischargeTempCompromised m447 : 29|1@1+ (1,0) [0|0] "" Vector__XXX
 SG_ VCFRONT_a462_CPA_State m462 : 29|1@1+ (1,0) [0|0] "" Vector__XXX
 SG_ VCFRONT_a476_serviceMode m476 : 29|1@1+ (1,0) [0|0] "" Vector__XXX
 SG_ VCFRONT_a480_vdsMax m480 : 29|1@1+ (1,0) [0|0] "" Vector__XXX
 SG_ VCFRONT_a525_frunkOpen m525 : 29|1@1+ (1,0) [0|0] "" Vector__XXX
 SG_ VCFRONT_a548_hvState m548 : 29|3@1+ (1,0) [0|0] "" Vector__XXX
 SG_ VCFRONT_a565_brakePressed m565 : 29|1@1+ (1,0) [0|0] "" Vector__XXX
 SG_ VCFRONT_a599_frunkOpen m599 : 29|1@1+ (1,0) [0|0] "" Vector__XXX
 SG_ VCFRONT_a614_battInletCoolantTooHot m614 : 29|1@1+ (1,0) [0|0] "" Vector__XXX
 SG_ VCFRONT_a663_hcmlValidatedGroupsHighWaterMarkPercent_IC400 m663 : 29|5@1+ (3.225806451612903,0) [0|0] "" Vector__XXX
 SG_ VCFRONT_a664_hcmrValidatedGroupsHighWaterMarkPercent_IC400 m664 : 29|5@1+ (3.225806451612903,0) [0|0] "" Vector__XXX
 SG_ VCFRONT_a047_Ovdvdda m47 : 30|1@1+ (1,0) [0|0] "" Vector__XXX
 SG_ VCFRONT_a104_VEH_steeringControl m104 : 30|1@1+ (1,0) [0|0] "" Vector__XXX
 SG_ VCFRONT_a109_CH_inertial2 m109 : 30|1@1+ (1,0) [0|0] "" Vector__XXX
 SG_ VCFRONT_a110_CH_vin m110 : 30|1@1+ (1,0) [0|0] "" Vector__XXX
 SG_ VCFRONT_a113_VEH_driverProfileRecall2 m113 : 30|1@1+ (1,0) [0|0] "" Vector__XXX
 SG_ VCFRONT_a114_BDY_status m114 : 30|1@1+ (1,0) [0|0] "" Vector__XXX
 SG_ VCFRONT_a116_VEH_status m116 : 30|1@1+ (1,0) [0|0] "" Vector__XXX
 SG_ VCFRONT_a117_VEH_switchStatus m117 : 30|1@1+ (1,0) [0|0] "" Vector__XXX
 SG_ VCFRONT_a118_CH_LVPowerState m118 : 30|1@1+ (1,0) [0|0] "" Vector__XXX
 SG_ VCFRONT_a120_PARTY_aggregatedAxleSpeed m120 : 30|1@1+ (1,0) [0|0] "" Vector__XXX
 SG_ VCFRONT_a142_isCoilShortYPGnd m142 : 30|1@1+ (1,0) [0|0] "" Vector__XXX
 SG_ VCFRONT_a153_chargePortDoorOpen m153 : 30|1@1+ (1,0) [0|0] "" Vector__XXX
 SG_ VCFRONT_a161_internalPowerSupplyFault m161 : 30|1@1+ (1,0) [0|0] "" Vector__XXX
 SG_ VCFRONT_a171_EPBR m171 : 30|1@1+ (1,0) [0|0] "" Vector__XXX
 SG_ VCFRONT_a178_pressureDischarge m178 : 30|5@1+ (1,0) [0|0] "" Vector__XXX
 SG_ VCFRONT_a180_vcrightEFuseStable m180 : 30|1@1+ (1,0) [0|0] "" Vector__XXX
 SG_ VCFRONT_a182_cellImbalance m182 : 30|1@1+ (1,0) [0|0] "" Vector__XXX
 SG_ VCFRONT_a183_cellImbalance m183 : 30|1@1+ (1,0) [0|0] "" Vector__XXX
 SG_ VCFRONT_a192_disconnected12V m192 : 30|1@1+ (1,0) [0|0] "" Vector__XXX
 SG_ VCFRONT_a197_pctValidIBSSamples m197 : 30|8@1+ (0.5,0) [0|0] "" Vector__XXX
 SG_ VCFRONT_a250_calibratedVerticalPositionHCMR m250 : 30|10@1+ (1,0) [0|0] "" Vector__XXX
 SG_ VCFRONT_a284_isCoilShortYPGnd m284 : 30|1@1+ (1,0) [0|0] "" Vector__XXX
 SG_ VCFRONT_a285_isCoilShortYPGnd m285 : 30|1@1+ (1,0) [0|0] "" Vector__XXX
 SG_ VCFRONT_a286_isCoilShortYPGnd m286 : 30|1@1+ (1,0) [0|0] "" Vector__XXX
 SG_ VCFRONT_a287_isCoilShortYPGnd m287 : 30|1@1+ (1,0) [0|0] "" Vector__XXX
 SG_ VCFRONT_a288_isCoilShortYPGnd m288 : 30|1@1+ (1,0) [0|0] "" Vector__XXX
 SG_ VCFRONT_a289_isCoilShortYPGnd m289 : 30|1@1+ (1,0) [0|0] "" Vector__XXX
 SG_ VCFRONT_a365_DIReportsCompleted m365 : 30|1@1+ (1,0) [0|0] "" Vector__XXX
 SG_ VCFRONT_a366_DIReportsUnavailable m366 : 30|1@1+ (1,0) [0|0] "" Vector__XXX
 SG_ VCFRONT_a394_droopDetected m394 : 30|1@1+ (1,0) [0|0] "" Vector__XXX
 SG_ VCFRONT_a402_communicationDisconnectLVBattery m402 : 30|1@1+ (1,0) [0|0] "" Vector__XXX
 SG_ VCFRONT_a429_usableCapacity m429 : 30|10@1+ (0.025,-0.025) [0|0] "" Vector__XXX
 SG_ VCFRONT_a446_compStandbyMultipleTdCutouts m446 : 30|1@1+ (1,0) [0|0] "" Vector__XXX
 SG_ VCFRONT_a447_refrigSuctionPressCompromised m447 : 30|1@1+ (1,0) [0|0] "" Vector__XXX
 SG_ VCFRONT_a462_NTCTempDiffWarnLevel1 m462 : 30|1@1+ (1,0) [0|0] "" Vector__XXX
 SG_ VCFRONT_a474_ssl100Bank8Status m474 : 30|2@1+ (1,0) [0|0] "" Vector__XXX
 SG_ VCFRONT_a475_ssl100Bank8Status m475 : 30|2@1+ (1,0) [0|0] "" Vector__XXX
 SG_ VCFRONT_a476_transportMode m476 : 30|1@1+ (1,0) [0|0] "" Vector__XXX
 SG_ VCFRONT_a480_bypassSaturation m480 : 30|1@1+ (1,0) [0|0] "" Vector__XXX
 SG_ VCFRONT_a482_previousAimedPosition m482 : 30|10@1+ (1,0) [0|0] "" Vector__XXX
 SG_ VCFRONT_a485_previousAimedPosition m485 : 30|10@1+ (1,0) [0|0] "" Vector__XXX
 SG_ VCFRONT_a508_brickImpedanceNormalized m508 : 30|10@1+ (0.002,0.5) [0|0] "" Vector__XXX
 SG_ VCFRONT_a514_cell3Voltage m514 : 30|7@1+ (0.08,0) [0|0] "" Vector__XXX
 SG_ VCFRONT_a515_cell3Voltage m515 : 30|7@1+ (0.08,0) [0|0] "" Vector__XXX
 SG_ VCFRONT_a565_chargePortDoorOpen m565 : 30|1@1+ (1,0) [0|0] "" Vector__XXX
 SG_ VCFRONT_a583_switch1StuckReason m583 : 30|2@1+ (1,0) [0|0] "" Vector__XXX
 SG_ VCFRONT_a606_chillerLoadAtExit m606 : 30|7@1+ (50.38582677165354,0) [0|0] "" Vector__XXX
 SG_ VCFRONT_a611_tempAmbientRaw m611 : 30|6@1+ (1,20) [0|0] "" Vector__XXX
 SG_ VCFRONT_a614_battInletSensor m614 : 30|1@1+ (1,0) [0|0] "" Vector__XXX
 SG_ VCFRONT_a047_Ovdvccd m47 : 31|1@1+ (1,0) [0|0] "" Vector__XXX
 SG_ VCFRONT_a104_PARTY_integratedSafetyFront m104 : 31|1@1+ (1,0) [0|0] "" Vector__XXX
 SG_ VCFRONT_a109_CH_status m109 : 31|1@1+ (1,0) [0|0] "" Vector__XXX
 SG_ VCFRONT_a110_CH_chNm m110 : 31|1@1+ (1,0) [0|0] "" Vector__XXX
 SG_ VCFRONT_a113_VEH_ventCntlReg m113 : 31|1@1+ (1,0) [0|0] "" Vector__XXX
 SG_ VCFRONT_a114_BDY_wheelRotation m114 : 31|1@1+ (1,0) [0|0] "" Vector__XXX
 SG_ VCFRONT_a116_VEH_thermalCommand m116 : 31|1@1+ (1,0) [0|0] "" Vector__XXX
 SG_ VCFRONT_a117_VEH_intrusionSensorStatus m117 : 31|1@1+ (1,0) [0|0] "" Vector__XXX
 SG_ VCFRONT_a118_PARTY_sensors m118 : 31|1@1+ (1,0) [0|0] "" Vector__XXX
 SG_ VCFRONT_a120_VEH_systemPower m120 : 31|1@1+ (1,0) [0|0] "" Vector__XXX
 SG_ VCFRONT_a142_isCoilShortYPVbb m142 : 31|1@1+ (1,0) [0|0] "" Vector__XXX
 SG_ VCFRONT_a153_UIChargePortDoorRequest m153 : 31|1@1+ (1,0) [0|0] "" Vector__XXX
 SG_ VCFRONT_a161_inverterOpenCircuit m161 : 31|1@1+ (1,0) [0|0] "" Vector__XXX
 SG_ VCFRONT_a171_EPBL m171 : 31|1@1+ (1,0) [0|0] "" Vector__XXX
 SG_ VCFRONT_a180_contactorEFuseStable m180 : 31|1@1+ (1,0) [0|0] "" Vector__XXX
 SG_ VCFRONT_a182_instantPrechargeDCRTooHigh m182 : 31|1@1+ (1,0) [0|0] "" Vector__XXX
 SG_ VCFRONT_a183_instantPrechargeDCRTooHigh m183 : 31|1@1+ (1,0) [0|0] "" Vector__XXX
 SG_ VCFRONT_a192_LVBatteryCannotSupportVehicle m192 : 31|1@1+ (1,0) [0|0] "" Vector__XXX
 SG_ VCFRONT_a284_isCoilShortYPVbb m284 : 31|1@1+ (1,0) [0|0] "" Vector__XXX
 SG_ VCFRONT_a285_isCoilShortYPVbb m285 : 31|1@1+ (1,0) [0|0] "" Vector__XXX
 SG_ VCFRONT_a286_isCoilShortYPVbb m286 : 31|1@1+ (1,0) [0|0] "" Vector__XXX
 SG_ VCFRONT_a287_isCoilShortYPVbb m287 : 31|1@1+ (1,0) [0|0] "" Vector__XXX
 SG_ VCFRONT_a288_isCoilShortYPVbb m288 : 31|1@1+ (1,0) [0|0] "" Vector__XXX
 SG_ VCFRONT_a289_isCoilShortYPVbb m289 : 31|1@1+ (1,0) [0|0] "" Vector__XXX
 SG_ VCFRONT_a365_DIReportsUnavailable m365 : 31|1@1+ (1,0) [0|0] "" Vector__XXX
 SG_ VCFRONT_a366_BMSSOCInvalid m366 : 31|1@1+ (1,0) [0|0] "" Vector__XXX
 SG_ VCFRONT_a387_opportunisticTest m387 : 31|1@1+ (1,0) [0|0] "" Vector__XXX
 SG_ VCFRONT_a388_opportunisticTest m388 : 31|1@1+ (1,0) [0|0] "" Vector__XXX
 SG_ VCFRONT_a390_quietModeEnabled m390 : 31|1@1+ (1,0) [0|0] "" Vector__XXX
 SG_ VCFRONT_a394_droopDetectedStandstill m394 : 31|1@1+ (1,0) [0|0] "" Vector__XXX
 SG_ VCFRONT_a402_reverseBatteryFault m402 : 31|1@1+ (1,0) [0|0] "" Vector__XXX
 SG_ VCFRONT_a403_IBSAmpHours m403 : 31|14@1- (0.01,0) [0|0] "" Vector__XXX
 SG_ VCFRONT_a414_IBSCurrent m414 : 31|12@1- (0.1,0) [0|0] "" Vector__XXX
 SG_ VCFRONT_a446_hpCabinLoadType m446 : 31|2@1+ (1,0) [0|0] "" Vector__XXX
 SG_ VCFRONT_a447_refrigSuctionTempCompromised m447 : 31|1@1+ (1,0) [0|0] "" Vector__XXX
 SG_ VCFRONT_a462_KBValueLostFault m462 : 31|1@1+ (1,0) [0|0] "" Vector__XXX
 SG_ VCFRONT_a476_frunkOpen m476 : 31|1@1+ (1,0) [0|0] "" Vector__XXX
 SG_ VCFRONT_a480_fuseLatch m480 : 31|1@1+ (1,0) [0|0] "" Vector__XXX
 SG_ VCFRONT_a498_measuredCurrent m498 : 31|10@1- (0.25,0) [0|0] "" Vector__XXX
 SG_ VCFRONT_a565_UIChargePortDoorRequest m565 : 31|1@1+ (1,0) [0|0] "" Vector__XXX
 SG_ VCFRONT_a614_ptInletSensor m614 : 31|1@1+ (1,0) [0|0] "" Vector__XXX
 SG_ VCFRONT_a669_totalHvPowerBudget m669 : 31|6@1+ (0.5,0) [0|0] "" Vector__XXX
 SG_ VCFRONT_a000_alertDataW1 m0 : 32|16@1+ (1,0) [0|0] "" Vector__XXX
 SG_ VCFRONT_a003_LineNumber m3 : 32|16@1+ (1,0) [0|0] "" Vector__XXX
 SG_ VCFRONT_a005_busID1 m5 : 32|4@1+ (1,0) [0|0] "" Vector__XXX
 SG_ VCFRONT_a006_messageID m6 : 32|29@1+ (1,0) [0|0] "" Vector__XXX
 SG_ VCFRONT_a009_PsMin m9 : 32|6@1+ (0.1,0) [0|0] "" Vector__XXX
 SG_ VCFRONT_a016_NVMMRecordNotFound m16 : 32|1@1+ (1,0) [0|0] "" Vector__XXX
 SG_ VCFRONT_a022_TaskInitError1 m22 : 32|8@1+ (1,0) [0|0] "" Vector__XXX
 SG_ VCFRONT_a031_uds_bytes_2 m31 : 32|8@1+ (1,0) [0|0] "" Vector__XXX
 SG_ VCFRONT_a033_address m33 : 32|32@1+ (1,0) [0|0] "" Vector__XXX
 SG_ VCFRONT_a038_protectionContext m38 : 32|4@1+ (1,0) [0|0] "" Vector__XXX
 SG_ VCFRONT_a041_CPULoad10msTask m41 : 32|8@1+ (1,0) [0|0] "" Vector__XXX
 SG_ VCFRONT_a042_Usage100msTask m42 : 32|8@1+ (1,0) [0|0] "" Vector__XXX
 SG_ VCFRONT_a047_OcdActLinreg m47 : 32|1@1+ (1,0) [0|0] "" Vector__XXX
 SG_ VCFRONT_a063_ADCVoltage m63 : 32|8@1+ (0.025,0) [0|0] "" Vector__XXX
 SG_ VCFRONT_a104_PARTY_matrixBendAngleRequest m104 : 32|1@1+ (1,0) [0|0] "" Vector__XXX
 SG_ VCFRONT_a110_CH_epochTimeGtw m110 : 32|1@1+ (1,0) [0|0] "" Vector__XXX
 SG_ VCFRONT_a113_VEH_debugECU m113 : 32|1@1+ (1,0) [0|0] "" Vector__XXX
 SG_ VCFRONT_a114_BDY_wheelSpeeds m114 : 32|1@1+ (1,0) [0|0] "" Vector__XXX
 SG_ VCFRONT_a116_VEH_windowStatus m116 : 32|1@1+ (1,0) [0|0] "" Vector__XXX
 SG_ VCFRONT_a117_VEH_liftgateStatus m117 : 32|1@1+ (1,0) [0|0] "" Vector__XXX
 SG_ VCFRONT_a118_CH_sensors m118 : 32|1@1+ (1,0) [0|0] "" Vector__XXX
 SG_ VCFRONT_a120_PT_systemPower m120 : 32|1@1+ (1,0) [0|0] "" Vector__XXX
 SG_ VCFRONT_a127_vcleftEFuseVoltage m127 : 32|16@1+ (0.1,0) [0|0] "" Vector__XXX
 SG_ VCFRONT_a128_vcrightEFuseVoltage m128 : 32|16@1+ (0.1,0) [0|0] "" Vector__XXX
 SG_ VCFRONT_a129_pcsEFuseVoltage m129 : 32|16@1+ (0.1,0) [0|0] "" Vector__XXX
 SG_ VCFRONT_a130_epas3pEFuseVoltage m130 : 32|16@1+ (0.1,0) [0|0] "" Vector__XXX
 SG_ VCFRONT_a131_epas3sEFuseVoltage m131 : 32|16@1+ (0.1,0) [0|0] "" Vector__XXX
 SG_ VCFRONT_a132_iBoosterVoltage m132 : 32|16@1+ (0.1,0) [0|0] "" Vector__XXX
 SG_ VCFRONT_a133_espEFuseVoltage m133 : 32|16@1+ (0.1,0) [0|0] "" Vector__XXX
 SG_ VCFRONT_a134_fusedHighVoltage m134 : 32|16@1+ (0.1,0) [0|0] "" Vector__XXX
 SG_ VCFRONT_a142_isCoilShortYNGnd m142 : 32|1@1+ (1,0) [0|0] "" Vector__XXX
 SG_ VCFRONT_a153_UIUserActivity m153 : 32|1@1+ (1,0) [0|0] "" Vector__XXX
 SG_ VCFRONT_a160_compressorRpm m160 : 32|7@1+ (90,0) [0|0] "" Vector__XXX
 SG_ VCFRONT_a161_warnOverTemperature m161 : 32|1@1+ (1,0) [0|0] "" Vector__XXX
 SG_ VCFRONT_a163_powerIndexFiltered m163 : 32|7@1+ (1,0) [0|0] "" Vector__XXX
 SG_ VCFRONT_a171_IBST m171 : 32|1@1+ (1,0) [0|0] "" Vector__XXX
 SG_ VCFRONT_a180_hvcEFuseStable m180 : 32|1@1+ (1,0) [0|0] "" Vector__XXX
 SG_ VCFRONT_a182_ambientTemp m182 : 32|7@1+ (1,-40) [0|0] "" Vector__XXX
 SG_ VCFRONT_a183_ambientTemp m183 : 32|7@1+ (1,-40) [0|0] "" Vector__XXX
 SG_ VCFRONT_a184_evapInTemp m184 : 32|5@1+ (2,0) [0|0] "" Vector__XXX
 SG_ VCFRONT_a192_DI_gear m192 : 32|3@1+ (1,0) [0|0] "" Vector__XXX
 SG_ VCFRONT_a213_IBSAh m213 : 32|14@1- (0.01,0) [0|0] "" Vector__XXX
 SG_ VCFRONT_a219_IBSAh m219 : 32|14@1- (0.01,0) [0|0] "" Vector__XXX
 SG_ VCFRONT_a220_PCSCurrent m220 : 32|8@1+ (0.5,-127) [0|0] "" Vector__XXX
 SG_ VCFRONT_a243_IBSCurrent m243 : 32|16@1- (0.005,0) [0|0] "" Vector__XXX
 SG_ VCFRONT_a244_voltage m244 : 32|16@1+ (0.1,0) [0|0] "" Vector__XXX
 SG_ VCFRONT_a245_voltage m245 : 32|16@1+ (0.1,0) [0|0] "" Vector__XXX
 SG_ VCFRONT_a246_voltage m246 : 32|16@1+ (0.1,0) [0|0] "" Vector__XXX
 SG_ VCFRONT_a252_IBSAmpHours m252 : 32|14@1- (0.01,0) [0|0] "" Vector__XXX
 SG_ VCFRONT_a257_vcrightLockoutStatus m257 : 32|2@1+ (1,0) [0|0] "" Vector__XXX
 SG_ VCFRONT_a259_IBSTemp m259 : 32|16@1- (0.01,0) [0|0] "" Vector__XXX
 SG_ VCFRONT_a261_vbatProtVoltage m261 : 32|16@1+ (0.1,0) [0|0] "" Vector__XXX
 SG_ VCFRONT_a262_vbatProtVoltage m262 : 32|16@1+ (0.1,0) [0|0] "" Vector__XXX
 SG_ VCFRONT_a263_vbatProtVoltage m263 : 32|16@1+ (0.1,0) [0|0] "" Vector__XXX
 SG_ VCFRONT_a264_vbatProtVoltage m264 : 32|16@1+ (0.1,0) [0|0] "" Vector__XXX
 SG_ VCFRONT_a265_vbatProtVoltage m265 : 32|16@1+ (0.1,0) [0|0] "" Vector__XXX
 SG_ VCFRONT_a266_vbatProtVoltage m266 : 32|16@1+ (0.1,0) [0|0] "" Vector__XXX
 SG_ VCFRONT_a267_vbatProtVoltage m267 : 32|16@1+ (0.1,0) [0|0] "" Vector__XXX
 SG_ VCFRONT_a268_vbatProtVoltage m268 : 32|16@1+ (0.1,0) [0|0] "" Vector__XXX
 SG_ VCFRONT_a275_bmbChainBreakType m275 : 32|3@1+ (1,0) [0|0] "" Vector__XXX
 SG_ VCFRONT_a277_regErrorType m277 : 32|8@1+ (1,0) [0|0] "" Vector__XXX
 SG_ VCFRONT_a283_thmlFanDemandLimit m283 : 32|7@1+ (1,0) [0|0] "" Vector__XXX
 SG_ VCFRONT_a284_isCoilShortYNGnd m284 : 32|1@1+ (1,0) [0|0] "" Vector__XXX
 SG_ VCFRONT_a285_isCoilShortYNGnd m285 : 32|1@1+ (1,0) [0|0] "" Vector__XXX
 SG_ VCFRONT_a286_isCoilShortYNGnd m286 : 32|1@1+ (1,0) [0|0] "" Vector__XXX
 SG_ VCFRONT_a287_isCoilShortYNGnd m287 : 32|1@1+ (1,0) [0|0] "" Vector__XXX
 SG_ VCFRONT_a288_isCoilShortYNGnd m288 : 32|1@1+ (1,0) [0|0] "" Vector__XXX
 SG_ VCFRONT_a289_isCoilShortYNGnd m289 : 32|1@1+ (1,0) [0|0] "" Vector__XXX
 SG_ VCFRONT_a303_postVoltage m303 : 32|16@1+ (0.1,0) [0|0] "" Vector__XXX
 SG_ VCFRONT_a305_actuatorCurrent m305 : 32|8@1+ (0.1,0) [0|0] "" Vector__XXX
 SG_ VCFRONT_a306_actuatorCurrent m306 : 32|8@1+ (0.1,0) [0|0] "" Vector__XXX
 SG_ VCFRONT_a307_actuatorCurrent m307 : 32|8@1+ (0.1,0) [0|0] "" Vector__XXX
 SG_ VCFRONT_a308_actuatorCurrent m308 : 32|8@1+ (0.1,0) [0|0] "" Vector__XXX
 SG_ VCFRONT_a309_switchVoltage m309 : 32|16@1+ (0.1,0) [0|0] "" Vector__XXX
 SG_ VCFRONT_a326_maxCurrent m326 : 32|16@1+ (0.1,0) [0|0] "" Vector__XXX
 SG_ VCFRONT_a327_maxCurrent m327 : 32|16@1+ (0.1,0) [0|0] "" Vector__XXX
 SG_ VCFRONT_a328_maxCurrent m328 : 32|16@1+ (0.1,0) [0|0] "" Vector__XXX
 SG_ VCFRONT_a329_maxCurrent m329 : 32|16@1+ (0.1,0) [0|0] "" Vector__XXX
 SG_ VCFRONT_a330_maxCurrent m330 : 32|16@1+ (0.1,0) [0|0] "" Vector__XXX
 SG_ VCFRONT_a331_maxCurrent m331 : 32|16@1+ (0.1,0) [0|0] "" Vector__XXX
 SG_ VCFRONT_a332_maxCurrent m332 : 32|16@1+ (0.1,0) [0|0] "" Vector__XXX
 SG_ VCFRONT_a333_maxCurrent m333 : 32|16@1+ (0.1,0) [0|0] "" Vector__XXX
 SG_ VCFRONT_a353_ambientTemperature m353 : 32|8@1+ (0.5,-40) [0|0] "" Vector__XXX
 SG_ VCFRONT_a354_ambientTemperature m354 : 32|8@1+ (0.5,-40) [0|0] "" Vector__XXX
 SG_ VCFRONT_a363_avgBleedCharge m363 : 32|15@1+ (0.001,0) [0|0] "" Vector__XXX
 SG_ VCFRONT_a365_BMSSOCInvalid m365 : 32|1@1+ (1,0) [0|0] "" Vector__XXX
 SG_ VCFRONT_a366_BMSSOCTooLow m366 : 32|1@1+ (1,0) [0|0] "" Vector__XXX
 SG_ VCFRONT_a368_systemFaulted m368 : 32|1@1+ (1,0) [0|0] "" Vector__XXX
 SG_ VCFRONT_a369_wasteHeatPower m369 : 32|7@1+ (100,0) [0|0] "" Vector__XXX
 SG_ VCFRONT_a375_sampledADCValue m375 : 32|13@1+ (0.0002,0) [0|0] "" Vector__XXX
 SG_ VCFRONT_a376_IBSCurrentSampleAboveThresholdCount m376 : 32|16@1+ (1,0) [0|0] "" Vector__XXX
 SG_ VCFRONT_a387_IBSTemp m387 : 32|16@1- (0.01,0) [0|0] "" Vector__XXX
 SG_ VCFRONT_a388_IBSTemp m388 : 32|16@1- (0.01,0) [0|0] "" Vector__XXX
 SG_ VCFRONT_a389_temperature m389 : 32|8@1+ (0.5,-40) [0|0] "" Vector__XXX
 SG_ VCFRONT_a390_evaluateToFindDominantLoad m390 : 32|1@1+ (1,0) [0|0] "" Vector__XXX
 SG_ VCFRONT_a391_switch2Voltage m391 : 32|10@1+ (5,0) [0|0] "" Vector__XXX
 SG_ VCFRONT_a400_bmbDeviceId m400 : 32|4@1+ (1,1) [0|0] "" Vector__XXX
 SG_ VCFRONT_a402_MOSOpen m402 : 32|1@1+ (1,0) [0|0] "" Vector__XXX
 SG_ VCFRONT_a404_IBSTemp m404 : 32|16@1- (0.01,0) [0|0] "" Vector__XXX
 SG_ VCFRONT_a405_intervalVoltage2 m405 : 32|8@1+ (0.02,9) [0|0] "" Vector__XXX
 SG_ VCFRONT_a406_pulseCompareV m406 : 32|8@1+ (0.02,9) [0|0] "" Vector__XXX
 SG_ VCFRONT_a408_IBSAmpHours m408 : 32|14@1- (0.01,0) [0|0] "" Vector__XXX
 SG_ VCFRONT_a412_pulseVoltage2Shifted m412 : 32|8@1+ (0.02,9) [0|0] "" Vector__XXX
 SG_ VCFRONT_a413_bmbDeviceId m413 : 32|4@1+ (1,1) [0|0] "" Vector__XXX
 SG_ VCFRONT_a421_uartConditionBitfield m421 : 32|16@1+ (1,0) [0|0] "" Vector__XXX
 SG_ VCFRONT_a425_maxBusVoltageLimit m425 : 32|16@1+ (0.002,0) [0|0] "" Vector__XXX
 SG_ VCFRONT_a426_minBusVoltageLimit m426 : 32|16@1+ (0.002,0) [0|0] "" Vector__XXX
 SG_ VCFRONT_a430_maxChargeCurrentLimit m430 : 32|16@1- (0.1,0) [0|0] "" Vector__XXX
 SG_ VCFRONT_a431_maxChargeCurrentLimit m431 : 32|16@1- (0.1,0) [0|0] "" Vector__XXX
 SG_ VCFRONT_a432_packCurrent m432 : 32|16@1- (0.1,0) [0|0] "" Vector__XXX
 SG_ VCFRONT_a433_packTypeData m433 : 32|8@1+ (1,0) [0|0] "" Vector__XXX
 SG_ VCFRONT_a434_packTypeData m434 : 32|8@1+ (1,0) [0|0] "" Vector__XXX
 SG_ VCFRONT_a435_maxDischargeCurrentLimit m435 : 32|16@1- (0.1,0) [0|0] "" Vector__XXX
 SG_ VCFRONT_a436_maxDischargeCurrentLimit m436 : 32|16@1- (0.1,0) [0|0] "" Vector__XXX
 SG_ VCFRONT_a438_sensorId m438 : 32|6@1+ (1,1) [0|0] "" Vector__XXX
 SG_ VCFRONT_a439_sensorId m439 : 32|6@1+ (1,1) [0|0] "" Vector__XXX
 SG_ VCFRONT_a441_bmbModuleIdPrev m441 : 32|16@1+ (1,0) [0|0] "" Vector__XXX
 SG_ VCFRONT_a442_maxSocChangeBrickId m442 : 32|7@1+ (1,1) [0|0] "" Vector__XXX
 SG_ VCFRONT_a444_watchdog m444 : 32|1@1+ (1,0) [0|0] "" Vector__XXX
 SG_ VCFRONT_a445_expectedLSB m445 : 32|8@1+ (1,0) [0|0] "" Vector__XXX
 SG_ VCFRONT_a447_refrigLiquidPressCompromised m447 : 32|1@1+ (1,0) [0|0] "" Vector__XXX
 SG_ VCFRONT_a462_BalanceCircuitFault m462 : 32|1@1+ (1,0) [0|0] "" Vector__XXX
 SG_ VCFRONT_a463_switch2Voltage m463 : 32|10@1+ (5,0) [0|0] "" Vector__XXX
 SG_ VCFRONT_a464_subcool m464 : 32|7@1+ (0.4,-10) [0|0] "" Vector__XXX
 SG_ VCFRONT_a465_subcool m465 : 32|7@1+ (0.4,-10) [0|0] "" Vector__XXX
 SG_ VCFRONT_a466_subcool m466 : 32|7@1+ (0.4,-10) [0|0] "" Vector__XXX
 SG_ VCFRONT_a474_ssl100Bank9Status m474 : 32|2@1+ (1,0) [0|0] "" Vector__XXX
 SG_ VCFRONT_a475_ssl100Bank9Status m475 : 32|2@1+ (1,0) [0|0] "" Vector__XXX
 SG_ VCFRONT_a476_vehiclePowerState m476 : 32|2@1+ (1,0) [0|0] "" Vector__XXX
 SG_ VCFRONT_a478_dcdcLVSupportStatus m478 : 32|2@1+ (1,0) [0|0] "" Vector__XXX
 SG_ VCFRONT_a479_batterySMState m479 : 32|4@1+ (1,0) [0|0] "" Vector__XXX
 SG_ VCFRONT_a480_deviceOvertemperature m480 : 32|1@1+ (1,0) [0|0] "" Vector__XXX
 SG_ VCFRONT_a484_vehiclePitchWhenLastAimed m484 : 32|10@1- (0.0001,0) [0|0] "" Vector__XXX
 SG_ VCFRONT_a492_maxBrickSocId m492 : 32|7@1+ (1,1) [0|0] "" Vector__XXX
 SG_ VCFRONT_a493_maxBrickSocId m493 : 32|7@1+ (1,1) [0|0] "" Vector__XXX
 SG_ VCFRONT_a497_PackCurrent m497 : 32|12@1+ (0.2,-600) [0|0] "" Vector__XXX
 SG_ VCFRONT_a509_vcrightEFuseTemp m509 : 32|8@1+ (0.75,0) [0|0] "" Vector__XXX
 SG_ VCFRONT_a510_targetPCSVoltage m510 : 32|8@1+ (0.1,0) [0|0] "" Vector__XXX
 SG_ VCFRONT_a511_DCDCMaxOutputCurrentAllowed m511 : 32|16@1- (0.1,0) [0|0] "" Vector__XXX
 SG_ VCFRONT_a512_packTemperature m512 : 32|8@1+ (1,-40) [0|0] "" Vector__XXX
 SG_ VCFRONT_a513_packTemperature m513 : 32|8@1+ (1,-40) [0|0] "" Vector__XXX
 SG_ VCFRONT_a521_vcleftEFuseTemp m521 : 32|8@1+ (0.75,0) [0|0] "" Vector__XXX
 SG_ VCFRONT_a523_control2Byte2 m523 : 32|8@1+ (1,0) [0|0] "" Vector__XXX
 SG_ VCFRONT_a529_LVBatteryTemp m529 : 32|16@1- (0.01,0) [0|0] "" Vector__XXX
 SG_ VCFRONT_a530_IBSCurrent m530 : 32|16@1- (0.1,0) [0|0] "" Vector__XXX
 SG_ VCFRONT_a534_measuredOpenRange m534 : 32|8@1+ (7,0) [0|0] "" Vector__XXX
 SG_ VCFRONT_a535_measuredOpenRange m535 : 32|8@1+ (7,0) [0|0] "" Vector__XXX
 SG_ VCFRONT_a536_measuredOpenRange m536 : 32|8@1+ (7,0) [0|0] "" Vector__XXX
 SG_ VCFRONT_a537_measuredOpenRange m537 : 32|8@1+ (7,0) [0|0] "" Vector__XXX
 SG_ VCFRONT_a538_measuredOpenRange m538 : 32|8@1+ (7,0) [0|0] "" Vector__XXX
 SG_ VCFRONT_a539_measuredOpenRange m539 : 32|8@1+ (7,0) [0|0] "" Vector__XXX
 SG_ VCFRONT_a542_suctionPressure m542 : 32|6@1+ (0.5,0) [0|0] "" Vector__XXX
 SG_ VCFRONT_a548_BMS_MIA m548 : 32|1@1+ (1,0) [0|0] "" Vector__XXX
 SG_ VCFRONT_a561_cell1Voltage m561 : 32|7@1+ (0.04,0) [0|0] "" Vector__XXX
 SG_ VCFRONT_a562_cell1Voltage m562 : 32|7@1+ (0.04,0) [0|0] "" Vector__XXX
 SG_ VCFRONT_a565_UIUserActivity m565 : 32|1@1+ (1,0) [0|0] "" Vector__XXX
 SG_ VCFRONT_a572_hvacCompressorVoltage m572 : 32|16@1+ (0.1,0) [0|0] "" Vector__XXX
 SG_ VCFRONT_a573_radarVoltage m573 : 32|16@1+ (0.1,0) [0|0] "" Vector__XXX
 SG_ VCFRONT_a574_frontDriveInverterVoltage m574 : 32|16@1+ (0.1,0) [0|0] "" Vector__XXX
 SG_ VCFRONT_a575_frontOilPumpVoltage m575 : 32|16@1+ (0.1,0) [0|0] "" Vector__XXX
 SG_ VCFRONT_a576_mcuLogicVoltage m576 : 32|16@1+ (0.1,0) [0|0] "" Vector__XXX
 SG_ VCFRONT_a577_tasVoltage m577 : 32|16@1+ (0.1,0) [0|0] "" Vector__XXX
 SG_ VCFRONT_a578_vbatFusedLowCurrentFeedVoltage m578 : 32|16@1+ (0.1,0) [0|0] "" Vector__XXX
 SG_ VCFRONT_a579_leftHeadlightVoltage m579 : 32|16@1+ (0.1,0) [0|0] "" Vector__XXX
 SG_ VCFRONT_a580_rightHeadlightVoltage m580 : 32|16@1+ (0.1,0) [0|0] "" Vector__XXX
 SG_ VCFRONT_a581_windshieldWiperVoltage m581 : 32|16@1+ (0.1,0) [0|0] "" Vector__XXX
 SG_ VCFRONT_a582_LVBusVoltage m582 : 32|8@1+ (0.1,0) [0|0] "" Vector__XXX
 SG_ VCFRONT_a583_switch2StuckReason m583 : 32|2@1+ (1,0) [0|0] "" Vector__XXX
 SG_ VCFRONT_a589_vcleftTimingThresholdMs m589 : 32|16@1+ (1,0) [0|0] "" Vector__XXX
 SG_ VCFRONT_a591_vcrightTimingThresholdMs m591 : 32|16@1+ (1,0) [0|0] "" Vector__XXX
 SG_ VCFRONT_a593_vcleftCutoffTimingThresholdMs m593 : 32|16@1+ (1,0) [0|0] "" Vector__XXX
 SG_ VCFRONT_a594_virtualPitchLearnedCalibration m594 : 32|9@1- (0.0005,0) [0|0] "" Vector__XXX
 SG_ VCFRONT_a597_vcrightCutoffTimingThresholdMs m597 : 32|16@1+ (1,0) [0|0] "" Vector__XXX
 SG_ VCFRONT_a608_bleedFetFailureBrickId m608 : 32|5@1+ (1,1) [0|0] "" Vector__XXX
 SG_ VCFRONT_a610_temperature m610 : 32|8@1+ (0.5,-40) [0|0] "" Vector__XXX
 SG_ VCFRONT_a612_lvHealthStatus m612 : 32|3@1+ (1,0) [0|0] "" Vector__XXX
 SG_ VCFRONT_a614_coolantLevelSensorFault m614 : 32|1@1+ (1,0) [0|0] "" Vector__XXX
 SG_ VCFRONT_a618_evapOutTemp m618 : 32|6@1+ (1,0) [0|0] "" Vector__XXX
 SG_ VCFRONT_a619_temperature m619 : 32|8@1+ (0.5,-40) [0|0] "" Vector__XXX
 SG_ VCFRONT_a623_lvHealthStatus m623 : 32|3@1+ (1,0) [0|0] "" Vector__XXX
 SG_ VCFRONT_a628_lastMeasuredTemp m628 : 32|8@1+ (0.5,-20) [0|0] "" Vector__XXX
 SG_ VCFRONT_a635_requestSleepFailedBitmask m635 : 32|16@1+ (1,0) [0|0] "" Vector__XXX
 SG_ VCFRONT_a643_uartConditionBitfield m643 : 32|16@1+ (1,0) [0|0] "" Vector__XXX
 SG_ VCFRONT_a645_averagePrimedFluidCurrent m645 : 32|8@1- (0.0984251968503937,5.807086614173229) [0|0] "" Vector__XXX
 SG_ VCFRONT_a016_NVMMCRCMismatch m16 : 33|1@1+ (1,0) [0|0] "" Vector__XXX
 SG_ VCFRONT_a047_OcdDpslpLinreg m47 : 33|1@1+ (1,0) [0|0] "" Vector__XXX
 SG_ VCFRONT_a104_VEH_matrixHighBeamRequest m104 : 33|1@1+ (1,0) [0|0] "" Vector__XXX
 SG_ VCFRONT_a113_VEH_status m113 : 33|1@1+ (1,0) [0|0] "" Vector__XXX
 SG_ VCFRONT_a114_CH_party1 m114 : 33|1@1+ (1,0) [0|0] "" Vector__XXX
 SG_ VCFRONT_a116_PARTY_restraintStatus m116 : 33|1@1+ (1,0) [0|0] "" Vector__XXX
 SG_ VCFRONT_a117_VEH_seatStatus2 m117 : 33|1@1+ (1,0) [0|0] "" Vector__XXX
 SG_ VCFRONT_a118_VEH_interNodeResistance m118 : 33|1@1+ (1,0) [0|0] "" Vector__XXX
 SG_ VCFRONT_a120_PARTY_stalklessInterfaces m120 : 33|1@1+ (1,0) [0|0] "" Vector__XXX
 SG_ VCFRONT_a142_isCoilShortYNVbb m142 : 33|1@1+ (1,0) [0|0] "" Vector__XXX
 SG_ VCFRONT_a153_passengerPresent m153 : 33|1@1+ (1,0) [0|0] "" Vector__XXX
 SG_ VCFRONT_a161_failedStartRepeated m161 : 33|1@1+ (1,0) [0|0] "" Vector__XXX
 SG_ VCFRONT_a171_IBSTCAL m171 : 33|1@1+ (1,0) [0|0] "" Vector__XXX
 SG_ VCFRONT_a180_replaceLVBattery m180 : 33|1@1+ (1,0) [0|0] "" Vector__XXX
 SG_ VCFRONT_a191_a180_DCDCNotSupportingLVBus m191 : 33|1@1+ (1,0) [0|0] "" Vector__XXX
 SG_ VCFRONT_a284_isCoilShortYNVbb m284 : 33|1@1+ (1,0) [0|0] "" Vector__XXX
 SG_ VCFRONT_a285_isCoilShortYNVbb m285 : 33|1@1+ (1,0) [0|0] "" Vector__XXX
 SG_ VCFRONT_a286_isCoilShortYNVbb m286 : 33|1@1+ (1,0) [0|0] "" Vector__XXX
 SG_ VCFRONT_a287_isCoilShortYNVbb m287 : 33|1@1+ (1,0) [0|0] "" Vector__XXX
 SG_ VCFRONT_a288_isCoilShortYNVbb m288 : 33|1@1+ (1,0) [0|0] "" Vector__XXX
 SG_ VCFRONT_a289_isCoilShortYNVbb m289 : 33|1@1+ (1,0) [0|0] "" Vector__XXX
 SG_ VCFRONT_a365_BMSSOCTooLow m365 : 33|1@1+ (1,0) [0|0] "" Vector__XXX
 SG_ VCFRONT_a366_DIMIA m366 : 33|1@1+ (1,0) [0|0] "" Vector__XXX
 SG_ VCFRONT_a368_coolantTempSensorsFaulted m368 : 33|1@1+ (1,0) [0|0] "" Vector__XXX
 SG_ VCFRONT_a402_serviceMode m402 : 33|1@1+ (1,0) [0|0] "" Vector__XXX
 SG_ VCFRONT_a407_intervalCurrentVariance m407 : 33|6@1+ (0.1,0) [0|0] "" Vector__XXX
 SG_ VCFRONT_a444_gateDriver m444 : 33|1@1+ (1,0) [0|0] "" Vector__XXX
 SG_ VCFRONT_a446_hpBatteryLoadType m446 : 33|2@1+ (1,0) [0|0] "" Vector__XXX
 SG_ VCFRONT_a447_refrigLiquidTempCompromised m447 : 33|1@1+ (1,0) [0|0] "" Vector__XXX
 SG_ VCFRONT_a462_MOSOpenFault m462 : 33|1@1+ (1,0) [0|0] "" Vector__XXX
 SG_ VCFRONT_a480_ntcOvertemperature m480 : 33|1@1+ (1,0) [0|0] "" Vector__XXX
 SG_ VCFRONT_a518_targetPCSVoltage m518 : 33|8@1+ (0.1,0) [0|0] "" Vector__XXX
 SG_ VCFRONT_a548_PCS_MIA m548 : 33|1@1+ (1,0) [0|0] "" Vector__XXX
 SG_ VCFRONT_a565_passengerPresent m565 : 33|1@1+ (1,0) [0|0] "" Vector__XXX
 SG_ VCFRONT_a584_switch2Voltage m584 : 33|9@1+ (10,0) [0|0] "" Vector__XXX
 SG_ VCFRONT_a614_coolantLevelSensorLow m614 : 33|1@1+ (1,0) [0|0] "" Vector__XXX
 SG_ VCFRONT_a626_intervalCurrentVariance m626 : 33|6@1+ (0.1,0) [0|0] "" Vector__XXX
 SG_ VCFRONT_a016_NVMMVersionMismatch m16 : 34|1@1+ (1,0) [0|0] "" Vector__XXX
 SG_ VCFRONT_a047_OcdReghc m47 : 34|1@1+ (1,0) [0|0] "" Vector__XXX
 SG_ VCFRONT_a104_VEH_summonCommand m104 : 34|1@1+ (1,0) [0|0] "" Vector__XXX
 SG_ VCFRONT_a113_VEH_elevationStatus m113 : 34|1@1+ (1,0) [0|0] "" Vector__XXX
 SG_ VCFRONT_a114_CH_party3 m114 : 34|1@1+ (1,0) [0|0] "" Vector__XXX
 SG_ VCFRONT_a116_PARTY_doorStatus m116 : 34|1@1+ (1,0) [0|0] "" Vector__XXX
 SG_ VCFRONT_a117_PARTY_restraintStatus m117 : 34|1@1+ (1,0) [0|0] "" Vector__XXX
 SG_ VCFRONT_a118_CH_lighting m118 : 34|1@1+ (1,0) [0|0] "" Vector__XXX
 SG_ VCFRONT_a120_CH_speed m120 : 34|1@1+ (1,0) [0|0] "" Vector__XXX
 SG_ VCFRONT_a142_driverHasCommError m142 : 34|1@1+ (1,0) [0|0] "" Vector__XXX
 SG_ VCFRONT_a153_chargeStateTransitioned m153 : 34|1@1+ (1,0) [0|0] "" Vector__XXX
 SG_ VCFRONT_a161_overload m161 : 34|1@1+ (1,0) [0|0] "" Vector__XXX
 SG_ VCFRONT_a171_ESP m171 : 34|1@1+ (1,0) [0|0] "" Vector__XXX
 SG_ VCFRONT_a180_BMS_MIA m180 : 34|1@1+ (1,0) [0|0] "" Vector__XXX
 SG_ VCFRONT_a187_hvsBusRetryCount m187 : 34|9@1+ (1,0) [0|0] "" Vector__XXX
 SG_ VCFRONT_a191_MOSState m191 : 34|2@1+ (1,0) [0|0] "" Vector__XXX
 SG_ VCFRONT_a253_IBSAmpHours m253 : 34|14@1- (0.01,0) [0|0] "" Vector__XXX
 SG_ VCFRONT_a257_vcleftFault m257 : 34|1@1+ (1,0) [0|0] "" Vector__XXX
 SG_ VCFRONT_a284_driverHasCommError m284 : 34|1@1+ (1,0) [0|0] "" Vector__XXX
 SG_ VCFRONT_a285_driverHasCommError m285 : 34|1@1+ (1,0) [0|0] "" Vector__XXX
 SG_ VCFRONT_a286_driverHasCommError m286 : 34|1@1+ (1,0) [0|0] "" Vector__XXX
 SG_ VCFRONT_a287_driverHasCommError m287 : 34|1@1+ (1,0) [0|0] "" Vector__XXX
 SG_ VCFRONT_a288_driverHasCommError m288 : 34|1@1+ (1,0) [0|0] "" Vector__XXX
 SG_ VCFRONT_a289_driverHasCommError m289 : 34|1@1+ (1,0) [0|0] "" Vector__XXX
 SG_ VCFRONT_a352_prevFilteredCurrent m352 : 34|8@1+ (0.1,0) [0|0] "" Vector__XXX
 SG_ VCFRONT_a365_DIMIA m365 : 34|1@1+ (1,0) [0|0] "" Vector__XXX
 SG_ VCFRONT_a366_PCSMIA m366 : 34|1@1+ (1,0) [0|0] "" Vector__XXX
 SG_ VCFRONT_a368_coolantValveFaulted m368 : 34|1@1+ (1,0) [0|0] "" Vector__XXX
 SG_ VCFRONT_a402_frunkOpen m402 : 34|1@1+ (1,0) [0|0] "" Vector__XXX
 SG_ VCFRONT_a427_deltaAh m427 : 34|9@1+ (0.5,0) [0|0] "" Vector__XXX
 SG_ VCFRONT_a444_overcurrent m444 : 34|1@1+ (1,0) [0|0] "" Vector__XXX
 SG_ VCFRONT_a462_DeepDischarge m462 : 34|1@1+ (1,0) [0|0] "" Vector__XXX
 SG_ VCFRONT_a474_lowBeamPrefieldStatus m474 : 34|3@1+ (1,0) [0|0] "" Vector__XXX
 SG_ VCFRONT_a475_lowBeamPrefieldStatus m475 : 34|3@1+ (1,0) [0|0] "" Vector__XXX
 SG_ VCFRONT_a476_batterySMState m476 : 34|4@1+ (1,0) [0|0] "" Vector__XXX
 SG_ VCFRONT_a477_cell3Voltage m477 : 34|9@1+ (0.01,0) [0|0] "" Vector__XXX
 SG_ VCFRONT_a478_factoryMode m478 : 34|1@1+ (1,0) [0|0] "" Vector__XXX
 SG_ VCFRONT_a480_vgsLow m480 : 34|1@1+ (1,0) [0|0] "" Vector__XXX
 SG_ VCFRONT_a481_VDSFinished m481 : 34|1@1+ (1,0) [0|0] "" Vector__XXX
 SG_ VCFRONT_a516_contactorsPermanentlyClosed m516 : 34|1@1+ (1,0) [0|0] "" Vector__XXX
 SG_ VCFRONT_a522_contactorsPermanentlyClosed m522 : 34|1@1+ (1,0) [0|0] "" Vector__XXX
 SG_ VCFRONT_a548_ampHourBucketCount m548 : 34|6@1+ (0.01,0) [0|0] "" Vector__XXX
 SG_ VCFRONT_a565_chargeStateTransitioned m565 : 34|1@1+ (1,0) [0|0] "" Vector__XXX
 SG_ VCFRONT_a583_disagreementDurationMS m583 : 34|19@1+ (100,0) [0|0] "" Vector__XXX
 SG_ VCFRONT_a614_louverFault m614 : 34|1@1+ (1,0) [0|0] "" Vector__XXX
 SG_ VCFRONT_a627_cell3Voltage m627 : 34|9@1+ (0.01,0) [0|0] "" Vector__XXX
 SG_ VCFRONT_a663_hcmlGroupsHighWaterMarkPercent_IC500 m663 : 34|5@1+ (3.225806451612903,0) [0|0] "" Vector__XXX
 SG_ VCFRONT_a664_hcmrGroupsHighWaterMarkPercent_IC500 m664 : 34|5@1+ (3.225806451612903,0) [0|0] "" Vector__XXX
 SG_ VCFRONT_a016_NVMMRecordUpgraded m16 : 35|1@1+ (1,0) [0|0] "" Vector__XXX
 SG_ VCFRONT_a047_Pmic m47 : 35|1@1+ (1,0) [0|0] "" Vector__XXX
 SG_ VCFRONT_a104_VEH_status m104 : 35|1@1+ (1,0) [0|0] "" Vector__XXX
 SG_ VCFRONT_a113_VEH_LVControl m113 : 35|1@1+ (1,0) [0|0] "" Vector__XXX
 SG_ VCFRONT_a114_CH_status m114 : 35|1@1+ (1,0) [0|0] "" Vector__XXX
 SG_ VCFRONT_a116_BDY_epbmStatus m116 : 35|1@1+ (1,0) [0|0] "" Vector__XXX
 SG_ VCFRONT_a117_VEH_thermalStatus m117 : 35|1@1+ (1,0) [0|0] "" Vector__XXX
 SG_ VCFRONT_a118_VEH_lightStatus m118 : 35|1@1+ (1,0) [0|0] "" Vector__XXX
 SG_ VCFRONT_a120_VEH_estimatedBrakeTemp m120 : 35|1@1+ (1,0) [0|0] "" Vector__XXX
 SG_ VCFRONT_a153_mismatchDuration m153 : 35|26@1+ (1,0) [0|0] "" Vector__XXX
 SG_ VCFRONT_a155_minHVComingUpIBSCurrent m155 : 35|10@1+ (0.1,-102.3) [0|0] "" Vector__XXX
 SG_ VCFRONT_a171_ESPCAL m171 : 35|1@1+ (1,0) [0|0] "" Vector__XXX
 SG_ VCFRONT_a178_pressureSuction m178 : 35|4@1+ (1,0) [0|0] "" Vector__XXX
 SG_ VCFRONT_a180_PCS_MIA m180 : 35|1@1+ (1,0) [0|0] "" Vector__XXX
 SG_ VCFRONT_a192_GTW_factoryGated m192 : 35|1@1+ (1,0) [0|0] "" Vector__XXX
 SG_ VCFRONT_a257_vcrightFault m257 : 35|1@1+ (1,0) [0|0] "" Vector__XXX
 SG_ VCFRONT_a365_PCSMIA m365 : 35|1@1+ (1,0) [0|0] "" Vector__XXX
 SG_ VCFRONT_a366_pcsFlowRequest m366 : 35|1@1+ (1,0) [0|0] "" Vector__XXX
 SG_ VCFRONT_a368_louverFaulted m368 : 35|1@1+ (1,0) [0|0] "" Vector__XXX
 SG_ VCFRONT_a444_supplyUndervoltage m444 : 35|1@1+ (1,0) [0|0] "" Vector__XXX
 SG_ VCFRONT_a446_usingModeledPs m446 : 35|1@1+ (1,0) [0|0] "" Vector__XXX
 SG_ VCFRONT_a462_SamplingError m462 : 35|1@1+ (1,0) [0|0] "" Vector__XXX
 SG_ VCFRONT_a478_serviceMode m478 : 35|1@1+ (1,0) [0|0] "" Vector__XXX
 SG_ VCFRONT_a480_chargePumpLow m480 : 35|1@1+ (1,0) [0|0] "" Vector__XXX
 SG_ VCFRONT_a481_VDSFailure m481 : 35|1@1+ (1,0) [0|0] "" Vector__XXX
 SG_ VCFRONT_a516_LVBatteryDisconnected m516 : 35|1@1+ (1,0) [0|0] "" Vector__XXX
 SG_ VCFRONT_a522_LVBatteryDisconnected m522 : 35|1@1+ (1,0) [0|0] "" Vector__XXX
 SG_ VCFRONT_a541_PeakCurrent m541 : 35|10@1+ (0.05,0) [0|0] "" Vector__XXX
 SG_ VCFRONT_a565_lastUserPresenceUpdateEpochTime m565 : 35|26@1+ (64,0) [0|0] "" Vector__XXX
 SG_ VCFRONT_a623_unhealthyReason m623 : 35|5@1+ (1,0) [0|0] "" Vector__XXX
 SG_ VCFRONT_a005_faults1 m5 : 36|12@1+ (1,0) [0|0] "" Vector__XXX
 SG_ VCFRONT_a016_NVMMMemOverflow m16 : 36|1@1+ (1,0) [0|0] "" Vector__XXX
 SG_ VCFRONT_a038_violationType m38 : 36|3@1+ (1,0) [0|0] "" Vector__XXX
 SG_ VCFRONT_a047_Porvddd m47 : 36|1@1+ (1,0) [0|0] "" Vector__XXX
 SG_ VCFRONT_a104_CH_pscControl m104 : 36|1@1+ (1,0) [0|0] "" Vector__XXX
 SG_ VCFRONT_a113_CH_chassisControl m113 : 36|1@1+ (1,0) [0|0] "" Vector__XXX
 SG_ VCFRONT_a116_BDY_restraintStatus m116 : 36|1@1+ (1,0) [0|0] "" Vector__XXX
 SG_ VCFRONT_a117_PARTY_doorStatus m117 : 36|1@1+ (1,0) [0|0] "" Vector__XXX
 SG_ VCFRONT_a118_PARTY_vehNm m118 : 36|1@1+ (1,0) [0|0] "" Vector__XXX
 SG_ VCFRONT_a120_PARTY_prndControl m120 : 36|1@1+ (1,0) [0|0] "" Vector__XXX
 SG_ VCFRONT_a162_ccLeftExvFlow m162 : 36|7@1+ (1,0) [0|0] "" Vector__XXX
 SG_ VCFRONT_a171_OPC m171 : 36|1@1+ (1,0) [0|0] "" Vector__XXX
 SG_ VCFRONT_a180_HVBlockingMismatch m180 : 36|1@1+ (1,0) [0|0] "" Vector__XXX
 SG_ VCFRONT_a188_vehicleState m188 : 36|5@1+ (1,0) [0|0] "" Vector__XXX
 SG_ VCFRONT_a191_LVBMSVoltage m191 : 36|8@1+ (0.08741903380905883,0) [0|0] "" Vector__XXX
 SG_ VCFRONT_a192_GTW_updateStarted m192 : 36|1@1+ (1,0) [0|0] "" Vector__XXX
 SG_ VCFRONT_a242_IBSVoltage m242 : 36|11@1+ (0.01088735219,0) [0|0] "" Vector__XXX
 SG_ VCFRONT_a257_pcsFault m257 : 36|1@1+ (1,0) [0|0] "" Vector__XXX
 SG_ VCFRONT_a269_IBSVoltage m269 : 36|11@1+ (0.01088735219,0) [0|0] "" Vector__XXX
 SG_ VCFRONT_a365_pcsFlowRequest m365 : 36|1@1+ (1,0) [0|0] "" Vector__XXX
 SG_ VCFRONT_a366_showroomMode m366 : 36|1@1+ (1,0) [0|0] "" Vector__XXX
 SG_ VCFRONT_a368_fansFaulted m368 : 36|1@1+ (1,0) [0|0] "" Vector__XXX
 SG_ VCFRONT_a400_VrefStatus m400 : 36|2@1+ (1,0) [0|0] "" Vector__XXX
 SG_ VCFRONT_a401_IBSVoltage m401 : 36|11@1+ (0.01088735219,0) [0|0] "" Vector__XXX
 SG_ VCFRONT_a410_IBSVoltage m410 : 36|11@1+ (0.01088735219,0) [0|0] "" Vector__XXX
 SG_ VCFRONT_a411_IBSVoltage m411 : 36|11@1+ (0.01088735219,0) [0|0] "" Vector__XXX
 SG_ VCFRONT_a413_VrefStatus m413 : 36|2@1+ (1,0) [0|0] "" Vector__XXX
 SG_ VCFRONT_a416_packCurrent m416 : 36|10@1- (5,0) [0|0] "" Vector__XXX
 SG_ VCFRONT_a417_packCurrent m417 : 36|10@1- (5,0) [0|0] "" Vector__XXX
 SG_ VCFRONT_a418_packCurrent m418 : 36|10@1- (5,0) [0|0] "" Vector__XXX
 SG_ VCFRONT_a419_packCurrent m419 : 36|10@1- (5,0) [0|0] "" Vector__XXX
 SG_ VCFRONT_a423_packCurrent m423 : 36|10@1- (5,0) [0|0] "" Vector__XXX
 SG_ VCFRONT_a424_packCurrent m424 : 36|10@1- (5,0) [0|0] "" Vector__XXX
 SG_ VCFRONT_a444_cpUndervoltage m444 : 36|1@1+ (1,0) [0|0] "" Vector__XXX
 SG_ VCFRONT_a446_usingModeledPd m446 : 36|1@1+ (1,0) [0|0] "" Vector__XXX
 SG_ VCFRONT_a462_MOSFETStuckClose m462 : 36|1@1+ (1,0) [0|0] "" Vector__XXX
 SG_ VCFRONT_a472_rangeIndex m472 : 36|2@1+ (1,0) [0|0] "" Vector__XXX
 SG_ VCFRONT_a473_rangeIndex m473 : 36|2@1+ (1,0) [0|0] "" Vector__XXX
 SG_ VCFRONT_a478_transportMode m478 : 36|1@1+ (1,0) [0|0] "" Vector__XXX
 SG_ VCFRONT_a480_watchdog m480 : 36|1@1+ (1,0) [0|0] "" Vector__XXX
 SG_ VCFRONT_a481_stuckOnVDS m481 : 36|10@1+ (1,0) [0|0] "" Vector__XXX
 SG_ VCFRONT_a503_packCurrent m503 : 36|10@1- (5,0) [0|0] "" Vector__XXX
 SG_ VCFRONT_a516_reverseBatteryFault m516 : 36|1@1+ (1,0) [0|0] "" Vector__XXX
 SG_ VCFRONT_a522_reverseBatteryFault m522 : 36|1@1+ (1,0) [0|0] "" Vector__XXX
 SG_ VCFRONT_a527_cell3Voltage m527 : 36|10@1+ (0.01,0) [0|0] "" Vector__XXX
 SG_ VCFRONT_a555_cell3Voltage m555 : 36|10@1+ (0.01,0) [0|0] "" Vector__XXX
 SG_ VCFRONT_a558_worseCaseRequiredRange m558 : 36|10@1+ (1,0) [0|0] "" Vector__XXX
 SG_ VCFRONT_a559_vehiclePowerState m559 : 36|2@1+ (1,0) [0|0] "" Vector__XXX
 SG_ VCFRONT_a564_worseCaseRequiredRange m564 : 36|10@1+ (1,0) [0|0] "" Vector__XXX
 SG_ VCFRONT_a585_rightHeadlampInternalErrorMask m585 : 36|20@1+ (1,0) [0|0] "" Vector__XXX
 SG_ VCFRONT_a605_sleepBypassCurrent m605 : 36|10@1+ (0.1,0) [0|0] "" Vector__XXX
 SG_ VCFRONT_a611_radFanSpeed m611 : 36|5@1+ (150,0) [0|0] "" Vector__XXX
 SG_ VCFRONT_a634_ajar1ClosingDeltaV m634 : 36|10@1- (0.01,0) [0|0] "" Vector__XXX
 SG_ VCFRONT_a644_pumpPrimedEstimate m644 : 36|1@1+ (1,0) [0|0] "" Vector__XXX
 SG_ VCFRONT_a016_NVMMWriteFailed m16 : 37|1@1+ (1,0) [0|0] "" Vector__XXX
 SG_ VCFRONT_a104_BDY_gpsAccuracies m104 : 37|1@1+ (1,0) [0|0] "" Vector__XXX
 SG_ VCFRONT_a113_CH_powertrainControl m113 : 37|1@1+ (1,0) [0|0] "" Vector__XXX
 SG_ VCFRONT_a117_VEH_status m117 : 37|1@1+ (1,0) [0|0] "" Vector__XXX
 SG_ VCFRONT_a118_CH_12VBatteryStatus m118 : 37|1@1+ (1,0) [0|0] "" Vector__XXX
 SG_ VCFRONT_a120_PARTY_locStatus2 m120 : 37|1@1+ (1,0) [0|0] "" Vector__XXX
 SG_ VCFRONT_a171_OPCS m171 : 37|1@1+ (1,0) [0|0] "" Vector__XXX
 SG_ VCFRONT_a180_serviceMode m180 : 37|1@1+ (1,0) [0|0] "" Vector__XXX
 SG_ VCFRONT_a192_serviceMode m192 : 37|1@1+ (1,0) [0|0] "" Vector__XXX
 SG_ VCFRONT_a257_vbatFusedFault m257 : 37|1@1+ (1,0) [0|0] "" Vector__XXX
 SG_ VCFRONT_a365_showroomMode m365 : 37|1@1+ (1,0) [0|0] "" Vector__XXX
 SG_ VCFRONT_a366_TransportMode m366 : 37|1@1+ (1,0) [0|0] "" Vector__XXX
 SG_ VCFRONT_a368_coolantNotFilled m368 : 37|1@1+ (1,0) [0|0] "" Vector__XXX
 SG_ VCFRONT_a444_overTempShutdown m444 : 37|1@1+ (1,0) [0|0] "" Vector__XXX
 SG_ VCFRONT_a446_usingModeledPl m446 : 37|1@1+ (1,0) [0|0] "" Vector__XXX
 SG_ VCFRONT_a462_MOSFETStuckOpen m462 : 37|1@1+ (1,0) [0|0] "" Vector__XXX
 SG_ VCFRONT_a474_drl1Status m474 : 37|3@1+ (1,0) [0|0] "" Vector__XXX
 SG_ VCFRONT_a475_drl1Status m475 : 37|3@1+ (1,0) [0|0] "" Vector__XXX
 SG_ VCFRONT_a478_notEnoughPowerForSupport m478 : 37|1@1+ (1,0) [0|0] "" Vector__XXX
 SG_ VCFRONT_a480_spiNotDone m480 : 37|1@1+ (1,0) [0|0] "" Vector__XXX
 SG_ VCFRONT_a514_cell4Voltage m514 : 37|7@1+ (0.08,0) [0|0] "" Vector__XXX
 SG_ VCFRONT_a515_cell4Voltage m515 : 37|7@1+ (0.08,0) [0|0] "" Vector__XXX
 SG_ VCFRONT_a516_LVBatteryCannotSupportVehicle m516 : 37|1@1+ (1,0) [0|0] "" Vector__XXX
 SG_ VCFRONT_a522_LVBatteryCannotSupportVehicle m522 : 37|1@1+ (1,0) [0|0] "" Vector__XXX
 SG_ VCFRONT_a606_ccQdotTotalBeforeEntry m606 : 37|6@1+ (111.11111111111111,0) [0|0] "" Vector__XXX
 SG_ VCFRONT_a669_vehicleSpeed m669 : 37|7@1+ (2,0) [0|0] "" Vector__XXX
 SG_ VCFRONT_a104_BDY_control m104 : 38|1@1+ (1,0) [0|0] "" Vector__XXX
 SG_ VCFRONT_a113_VEH_tripPlanning m113 : 38|1@1+ (1,0) [0|0] "" Vector__XXX
 SG_ VCFRONT_a117_PARTY_prndStatus m117 : 38|1@1+ (1,0) [0|0] "" Vector__XXX
 SG_ VCFRONT_a118_CH_LVBMS_statusHigh m118 : 38|1@1+ (1,0) [0|0] "" Vector__XXX
 SG_ VCFRONT_a120_VEH_chassisCntl m120 : 38|1@1+ (1,0) [0|0] "" Vector__XXX
 SG_ VCFRONT_a171_SCCM m171 : 38|1@1+ (1,0) [0|0] "" Vector__XXX
 SG_ VCFRONT_a180_transportMode m180 : 38|1@1+ (1,0) [0|0] "" Vector__XXX
 SG_ VCFRONT_a192_frunkOpen m192 : 38|1@1+ (1,0) [0|0] "" Vector__XXX
 SG_ VCFRONT_a197_prechargeSuccessful m197 : 38|1@1+ (1,0) [0|0] "" Vector__XXX
 SG_ VCFRONT_a257_iBoosterFault m257 : 38|1@1+ (1,0) [0|0] "" Vector__XXX
 SG_ VCFRONT_a365_TransportMode m365 : 38|1@1+ (1,0) [0|0] "" Vector__XXX
 SG_ VCFRONT_a366_ScheduledDeparture m366 : 38|1@1+ (1,0) [0|0] "" Vector__XXX
 SG_ VCFRONT_a368_coolantPumpsFaulted m368 : 38|1@1+ (1,0) [0|0] "" Vector__XXX
 SG_ VCFRONT_a379_minUnfilteredVoltageReached m379 : 38|12@1+ (0.005443676098,0) [0|0] "" Vector__XXX
 SG_ VCFRONT_a400_VrefType m400 : 38|2@1+ (1,0) [0|0] "" Vector__XXX
 SG_ VCFRONT_a413_VrefType m413 : 38|2@1+ (1,0) [0|0] "" Vector__XXX
 SG_ VCFRONT_a415_IBSVoltage m415 : 38|9@1+ (0.04,0) [0|0] "" Vector__XXX
 SG_ VCFRONT_a444_overTempWarning m444 : 38|1@1+ (1,0) [0|0] "" Vector__XXX
 SG_ VCFRONT_a446_usingModeledTs m446 : 38|1@1+ (1,0) [0|0] "" Vector__XXX
 SG_ VCFRONT_a462_Imbalance m462 : 38|1@1+ (1,0) [0|0] "" Vector__XXX
 SG_ VCFRONT_a476_ECPAState m476 : 38|2@1+ (1,0) [0|0] "" Vector__XXX
 SG_ VCFRONT_a478_crashDetected m478 : 38|1@1+ (1,0) [0|0] "" Vector__XXX
 SG_ VCFRONT_a480_configIncorrect m480 : 38|1@1+ (1,0) [0|0] "" Vector__XXX
 SG_ VCFRONT_a595_IBSVoltage m595 : 38|10@1+ (0.1,-1) [0|0] "" Vector__XXX
 SG_ VCFRONT_a058_prevREstimate m58 : 39|12@1+ (0.00061,0) [0|0] "" Vector__XXX
 SG_ VCFRONT_a104_BDY_status m104 : 39|1@1+ (1,0) [0|0] "" Vector__XXX
 SG_ VCFRONT_a113_VEH_vehicleControl3 m113 : 39|1@1+ (1,0) [0|0] "" Vector__XXX
 SG_ VCFRONT_a117_PARTY_lightingSecondary m117 : 39|1@1+ (1,0) [0|0] "" Vector__XXX
 SG_ VCFRONT_a118_CH_alertMatrix m118 : 39|1@1+ (1,0) [0|0] "" Vector__XXX
 SG_ VCFRONT_a120_VEH_locStatus m120 : 39|1@1+ (1,0) [0|0] "" Vector__XXX
 SG_ VCFRONT_a171_LVBMS m171 : 39|1@1+ (1,0) [0|0] "" Vector__XXX
 SG_ VCFRONT_a178_inverterTemp m178 : 39|6@1+ (3,-40) [0|0] "" Vector__XXX
 SG_ VCFRONT_a180_frunkOpen m180 : 39|1@1+ (1,0) [0|0] "" Vector__XXX
 SG_ VCFRONT_a182_dischargedAmpHours m182 : 39|8@1+ (60,0) [0|0] "" Vector__XXX
 SG_ VCFRONT_a183_dischargedAmpHours m183 : 39|8@1+ (60,0) [0|0] "" Vector__XXX
 SG_ VCFRONT_a197_dcrMilliOhms m197 : 39|8@1+ (1,0) [0|0] "" Vector__XXX
 SG_ VCFRONT_a257_espFault m257 : 39|1@1+ (1,0) [0|0] "" Vector__XXX
 SG_ VCFRONT_a365_ScheduledDeparture m365 : 39|1@1+ (1,0) [0|0] "" Vector__XXX
 SG_ VCFRONT_a366_LowCoolant m366 : 39|1@1+ (1,0) [0|0] "" Vector__XXX
 SG_ VCFRONT_a368_preconditionsNotMet m368 : 39|1@1+ (1,0) [0|0] "" Vector__XXX
 SG_ VCFRONT_a407_avgPulseCurrent m407 : 39|7@1+ (1,-127) [0|0] "" Vector__XXX
 SG_ VCFRONT_a444_highSide2GateDriver m444 : 39|1@1+ (1,0) [0|0] "" Vector__XXX
 SG_ VCFRONT_a446_usingModeledTd m446 : 39|1@1+ (1,0) [0|0] "" Vector__XXX
 SG_ VCFRONT_a462_serviceMode m462 : 39|1@1+ (1,0) [0|0] "" Vector__XXX
 SG_ VCFRONT_a478_BMS_MIA m478 : 39|1@1+ (1,0) [0|0] "" Vector__XXX
 SG_ VCFRONT_a480_bufferFull m480 : 39|1@1+ (1,0) [0|0] "" Vector__XXX
 SG_ VCFRONT_a561_cell2Voltage m561 : 39|7@1+ (0.04,0) [0|0] "" Vector__XXX
 SG_ VCFRONT_a562_cell2Voltage m562 : 39|7@1+ (0.04,0) [0|0] "" Vector__XXX
 SG_ VCFRONT_a626_avgPulseCurrent m626 : 39|7@1+ (1,-127) [0|0] "" Vector__XXX
 SG_ VCFRONT_a663_hcmlValidatedGroupsHighWaterMarkPercent_IC500 m663 : 39|5@1+ (3.225806451612903,0) [0|0] "" Vector__XXX
 SG_ VCFRONT_a664_hcmrValidatedGroupsHighWaterMarkPercent_IC500 m664 : 39|5@1+ (3.225806451612903,0) [0|0] "" Vector__XXX
 SG_ VCFRONT_a009_PlAtExit m9 : 40|5@1+ (1,0) [0|0] "" Vector__XXX
 SG_ VCFRONT_a022_TaskInitError2 m22 : 40|8@1+ (1,0) [0|0] "" Vector__XXX
 SG_ VCFRONT_a031_uds_bytes_3 m31 : 40|8@1+ (1,0) [0|0] "" Vector__XXX
 SG_ VCFRONT_a038_faultSource m38 : 40|7@1+ (1,0) [0|0] "" Vector__XXX
 SG_ VCFRONT_a041_CPULoad100msTask m41 : 40|8@1+ (1,0) [0|0] "" Vector__XXX
 SG_ VCFRONT_a042_Usage1000msTask m42 : 40|8@1+ (1,0) [0|0] "" Vector__XXX
 SG_ VCFRONT_a043_CallTrace1 m43 : 40|24@1+ (1,0) [0|0] "" Vector__XXX
 SG_ VCFRONT_a044_CallTrace1 m44 : 40|24@1+ (1,0) [0|0] "" Vector__XXX
 SG_ VCFRONT_a045_CallTrace1 m45 : 40|24@1+ (1,0) [0|0] "" Vector__XXX
 SG_ VCFRONT_a046_CallTrace1 m46 : 40|24@1+ (1,0) [0|0] "" Vector__XXX
 SG_ VCFRONT_a047_CsvHf m47 : 40|16@1+ (1,0) [0|0] "" Vector__XXX
 SG_ VCFRONT_a059_current m59 : 40|12@1+ (0.05,0) [0|0] "" Vector__XXX
 SG_ VCFRONT_a063_disconnected m63 : 40|1@1+ (1,0) [0|0] "" Vector__XXX
 SG_ VCFRONT_a104_VEH_wirelessChargingStatus m104 : 40|1@1+ (1,0) [0|0] "" Vector__XXX
 SG_ VCFRONT_a113_VEH_vehicleControlThermal m113 : 40|1@1+ (1,0) [0|0] "" Vector__XXX
 SG_ VCFRONT_a118_BDY_outputPowerStatus m118 : 40|1@1+ (1,0) [0|0] "" Vector__XXX
 SG_ VCFRONT_a120_VEH_locStatus2 m120 : 40|1@1+ (1,0) [0|0] "" Vector__XXX
 SG_ VCFRONT_a154_lastSilentWakeIBSAmpHours m154 : 40|6@1+ (0.05,-3) [0|0] "" Vector__XXX
 SG_ VCFRONT_a171_IDB m171 : 40|1@1+ (1,0) [0|0] "" Vector__XXX
 SG_ VCFRONT_a180_dcdcLVSupportStatus m180 : 40|2@1+ (1,0) [0|0] "" Vector__XXX
 SG_ VCFRONT_a184_humidityRatio m184 : 40|4@1+ (4,0) [0|0] "" Vector__XXX
 SG_ VCFRONT_a192_IBSCurrent m192 : 40|8@1+ (0.5,-63) [0|0] "" Vector__XXX
 SG_ VCFRONT_a196_disconnectedBatteryTestVoltage m196 : 40|8@1+ (0.0392156862745098,6) [0|0] "" Vector__XXX
 SG_ VCFRONT_a220_serviceMode m220 : 40|1@1+ (1,0) [0|0] "" Vector__XXX
 SG_ VCFRONT_a228_measurementInterval m228 : 40|8@1+ (1,0) [0|0] "" Vector__XXX
 SG_ VCFRONT_a229_measurementInterval m229 : 40|8@1+ (1,0) [0|0] "" Vector__XXX
 SG_ VCFRONT_a230_measurementInterval m230 : 40|8@1+ (1,0) [0|0] "" Vector__XXX
 SG_ VCFRONT_a248_vbatMonitor m248 : 40|12@1+ (0.005443676098,0) [0|0] "" Vector__XXX
 SG_ VCFRONT_a250_calibratedHorizontalPositionHCML m250 : 40|10@1+ (1,0) [0|0] "" Vector__XXX
 SG_ VCFRONT_a257_epas3pFault m257 : 40|1@1+ (1,0) [0|0] "" Vector__XXX
 SG_ VCFRONT_a260_vehiclePowerState m260 : 40|2@1+ (1,0) [0|0] "" Vector__XXX
 SG_ VCFRONT_a283_thmlFanPhaseI m283 : 40|7@1+ (0.25,0) [0|0] "" Vector__XXX
 SG_ VCFRONT_a310_avgTemp m310 : 40|11@1+ (0.125,-40) [0|0] "" Vector__XXX
 SG_ VCFRONT_a311_avgTemp m311 : 40|11@1+ (0.125,-40) [0|0] "" Vector__XXX
 SG_ VCFRONT_a312_avgTemp m312 : 40|11@1+ (0.125,-40) [0|0] "" Vector__XXX
 SG_ VCFRONT_a313_avgTemp m313 : 40|11@1+ (0.125,-40) [0|0] "" Vector__XXX
 SG_ VCFRONT_a314_avgTemp m314 : 40|11@1+ (0.125,-40) [0|0] "" Vector__XXX
 SG_ VCFRONT_a315_avgTemp m315 : 40|11@1+ (0.125,-40) [0|0] "" Vector__XXX
 SG_ VCFRONT_a316_avgTemp m316 : 40|11@1+ (0.125,-40) [0|0] "" Vector__XXX
 SG_ VCFRONT_a317_avgTemp m317 : 40|11@1+ (0.125,-40) [0|0] "" Vector__XXX
 SG_ VCFRONT_a318_avgTemp m318 : 40|11@1+ (0.125,-40) [0|0] "" Vector__XXX
 SG_ VCFRONT_a319_avgTemp m319 : 40|11@1+ (0.125,-40) [0|0] "" Vector__XXX
 SG_ VCFRONT_a320_avgTemp m320 : 40|11@1+ (0.125,-40) [0|0] "" Vector__XXX
 SG_ VCFRONT_a321_avgTemp m321 : 40|11@1+ (0.125,-40) [0|0] "" Vector__XXX
 SG_ VCFRONT_a322_avgTemp m322 : 40|11@1+ (0.125,-40) [0|0] "" Vector__XXX
 SG_ VCFRONT_a323_avgTemp m323 : 40|11@1+ (0.125,-40) [0|0] "" Vector__XXX
 SG_ VCFRONT_a324_avgTemp m324 : 40|11@1+ (0.125,-40) [0|0] "" Vector__XXX
 SG_ VCFRONT_a325_avgTemp m325 : 40|11@1+ (0.125,-40) [0|0] "" Vector__XXX
 SG_ VCFRONT_a334_maxCurrent m334 : 40|12@1+ (0.1,0) [0|0] "" Vector__XXX
 SG_ VCFRONT_a335_maxCurrent m335 : 40|12@1+ (0.1,0) [0|0] "" Vector__XXX
 SG_ VCFRONT_a336_maxCurrent m336 : 40|12@1+ (0.1,0) [0|0] "" Vector__XXX
 SG_ VCFRONT_a337_maxCurrent m337 : 40|12@1+ (0.1,0) [0|0] "" Vector__XXX
 SG_ VCFRONT_a338_maxCurrent m338 : 40|12@1+ (0.1,0) [0|0] "" Vector__XXX
 SG_ VCFRONT_a339_maxCurrent m339 : 40|12@1+ (0.1,0) [0|0] "" Vector__XXX
 SG_ VCFRONT_a340_maxCurrent m340 : 40|12@1+ (0.1,0) [0|0] "" Vector__XXX
 SG_ VCFRONT_a341_maxCurrent m341 : 40|12@1+ (0.1,0) [0|0] "" Vector__XXX
 SG_ VCFRONT_a342_maxCurrent m342 : 40|12@1+ (0.1,0) [0|0] "" Vector__XXX
 SG_ VCFRONT_a343_maxCurrent m343 : 40|12@1+ (0.1,0) [0|0] "" Vector__XXX
 SG_ VCFRONT_a344_maxCurrent m344 : 40|12@1+ (0.1,0) [0|0] "" Vector__XXX
 SG_ VCFRONT_a345_maxCurrent m345 : 40|12@1+ (0.1,0) [0|0] "" Vector__XXX
 SG_ VCFRONT_a346_maxCurrent m346 : 40|12@1+ (0.1,0) [0|0] "" Vector__XXX
 SG_ VCFRONT_a347_maxCurrent m347 : 40|12@1+ (0.1,0) [0|0] "" Vector__XXX
 SG_ VCFRONT_a348_maxCurrent m348 : 40|12@1+ (0.1,0) [0|0] "" Vector__XXX
 SG_ VCFRONT_a349_maxCurrent m349 : 40|12@1+ (0.1,0) [0|0] "" Vector__XXX
 SG_ VCFRONT_a359_vehiclePowerState m359 : 40|2@1+ (1,0) [0|0] "" Vector__XXX
 SG_ VCFRONT_a365_LowCoolant m365 : 40|1@1+ (1,0) [0|0] "" Vector__XXX
 SG_ VCFRONT_a366_userChargeStatus m366 : 40|3@1+ (1,0) [0|0] "" Vector__XXX
 SG_ VCFRONT_a368_belowSocMin m368 : 40|1@1+ (1,0) [0|0] "" Vector__XXX
 SG_ VCFRONT_a370_notEnoughPowerForSupport m370 : 40|1@1+ (1,0) [0|0] "" Vector__XXX
 SG_ VCFRONT_a373_compDemandChiller m373 : 40|7@1+ (1,0) [0|0] "" Vector__XXX
 SG_ VCFRONT_a389_latchStatus m389 : 40|4@1+ (1,0) [0|0] "" Vector__XXX
 SG_ VCFRONT_a405_intervalCompareV m405 : 40|8@1+ (0.02,9) [0|0] "" Vector__XXX
 SG_ VCFRONT_a406_avgPulseCurrent m406 : 40|7@1+ (1,-127) [0|0] "" Vector__XXX
 SG_ VCFRONT_a412_pulseCompareVShifted m412 : 40|8@1+ (0.02,9) [0|0] "" Vector__XXX
 SG_ VCFRONT_a428_avgBrickCac m428 : 40|13@1+ (0.1,0) [0|0] "" Vector__XXX
 SG_ VCFRONT_a429_usableEnergy m429 : 40|10@1+ (0.2,-0.2) [0|0] "" Vector__XXX
 SG_ VCFRONT_a433_cellTypeData m433 : 40|8@1+ (1,0) [0|0] "" Vector__XXX
 SG_ VCFRONT_a434_cellTypeData m434 : 40|8@1+ (1,0) [0|0] "" Vector__XXX
 SG_ VCFRONT_a442_numBricksChanged m442 : 40|8@1+ (1,0) [0|0] "" Vector__XXX
 SG_ VCFRONT_a444_lowSide2GateDriver m444 : 40|1@1+ (1,0) [0|0] "" Vector__XXX
 SG_ VCFRONT_a445_actualMSB m445 : 40|8@1+ (1,0) [0|0] "" Vector__XXX
 SG_ VCFRONT_a446_usingModeledTl m446 : 40|1@1+ (1,0) [0|0] "" Vector__XXX
 SG_ VCFRONT_a461_maxSocAhErrorBrickId m461 : 40|7@1+ (1,1) [0|0] "" Vector__XXX
 SG_ VCFRONT_a462_frunkOpen m462 : 40|1@1+ (1,0) [0|0] "" Vector__XXX
 SG_ VCFRONT_a464_subcoolFiltered m464 : 40|7@1+ (0.4,-10) [0|0] "" Vector__XXX
 SG_ VCFRONT_a465_subcoolFiltered m465 : 40|7@1+ (0.4,-10) [0|0] "" Vector__XXX
 SG_ VCFRONT_a466_subcoolFiltered m466 : 40|7@1+ (0.4,-10) [0|0] "" Vector__XXX
 SG_ VCFRONT_a472_headlampTemperature_C m472 : 40|8@1+ (0.5,-40) [0|0] "" Vector__XXX
 SG_ VCFRONT_a473_headlampTemperature_C m473 : 40|8@1+ (0.5,-40) [0|0] "" Vector__XXX
 SG_ VCFRONT_a474_drl2Status m474 : 40|3@1+ (1,0) [0|0] "" Vector__XXX
 SG_ VCFRONT_a475_drl2Status m475 : 40|3@1+ (1,0) [0|0] "" Vector__XXX
 SG_ VCFRONT_a478_PCS_MIA m478 : 40|1@1+ (1,0) [0|0] "" Vector__XXX
 SG_ VCFRONT_a480_hitAlertRateLimit m480 : 40|1@1+ (1,0) [0|0] "" Vector__XXX
 SG_ VCFRONT_a482_desiredPositionRelative m482 : 40|16@1- (1,0) [0|0] "" Vector__XXX
 SG_ VCFRONT_a485_desiredPositionRelative m485 : 40|16@1- (1,0) [0|0] "" Vector__XXX
 SG_ VCFRONT_a492_maxBrickSoc m492 : 40|8@1+ (0.5,0) [0|0] "" Vector__XXX
 SG_ VCFRONT_a493_maxBrickSocByOcvMin m493 : 40|8@1+ (0.5,0) [0|0] "" Vector__XXX
 SG_ VCFRONT_a502_worstBrickV m502 : 40|12@1+ (0.002,0) [0|0] "" Vector__XXX
 SG_ VCFRONT_a508_brickImpedanceId m508 : 40|5@1+ (1,1) [0|0] "" Vector__XXX
 SG_ VCFRONT_a509_ambientTemp m509 : 40|8@1+ (0.5,-40) [0|0] "" Vector__XXX
 SG_ VCFRONT_a510_serviceMode m510 : 40|1@1+ (1,0) [0|0] "" Vector__XXX
 SG_ VCFRONT_a512_sumCellVoltage m512 : 40|8@1+ (0.1,0) [0|0] "" Vector__XXX
 SG_ VCFRONT_a513_packVoltage m513 : 40|8@1+ (0.1,0) [0|0] "" Vector__XXX
 SG_ VCFRONT_a521_ambientTemp m521 : 40|8@1+ (0.5,-40) [0|0] "" Vector__XXX
 SG_ VCFRONT_a523_control2Byte3 m523 : 40|8@1+ (1,0) [0|0] "" Vector__XXX
 SG_ VCFRONT_a534_measuredCloseRange m534 : 40|8@1+ (7,0) [0|0] "" Vector__XXX
 SG_ VCFRONT_a535_measuredCloseRange m535 : 40|8@1+ (7,0) [0|0] "" Vector__XXX
 SG_ VCFRONT_a536_measuredCloseRange m536 : 40|8@1+ (7,0) [0|0] "" Vector__XXX
 SG_ VCFRONT_a537_measuredCloseRange m537 : 40|8@1+ (7,0) [0|0] "" Vector__XXX
 SG_ VCFRONT_a538_measuredCloseRange m538 : 40|8@1+ (7,0) [0|0] "" Vector__XXX
 SG_ VCFRONT_a539_measuredCloseRange m539 : 40|8@1+ (7,0) [0|0] "" Vector__XXX
 SG_ VCFRONT_a542_ambientTempRaw m542 : 40|8@1+ (0.5,-40) [0|0] "" Vector__XXX
 SG_ VCFRONT_a548_LVBMSSOC m548 : 40|5@1+ (3,0) [0|0] "" Vector__XXX
 SG_ VCFRONT_a556_disconnectedBatteryTestVoltage m556 : 40|8@1+ (0.0392156862745098,6) [0|0] "" Vector__XXX
 SG_ VCFRONT_a559_batterySMState m559 : 40|4@1+ (1,0) [0|0] "" Vector__XXX
 SG_ VCFRONT_a582_LVBusVoltageSource m582 : 40|2@1+ (1,0) [0|0] "" Vector__XXX
 SG_ VCFRONT_a587_IBSCurrent m587 : 40|12@1- (0.1,0) [0|0] "" Vector__XXX
 SG_ VCFRONT_a588_vcleftBTerm m588 : 40|8@1- (1,-78) [0|0] "" Vector__XXX
 SG_ VCFRONT_a590_vcrightBTerm m590 : 40|8@1- (1,-78) [0|0] "" Vector__XXX
 SG_ VCFRONT_a592_vcleftCutoffBTerm m592 : 40|8@1- (1,-78) [0|0] "" Vector__XXX
 SG_ VCFRONT_a596_vcrightCutoffBTerm m596 : 40|8@1- (1,-78) [0|0] "" Vector__XXX
 SG_ VCFRONT_a600_IBSCurrent m600 : 40|12@1- (0.1,0) [0|0] "" Vector__XXX
 SG_ VCFRONT_a608_retryCount m608 : 40|4@1+ (1,0) [0|0] "" Vector__XXX
 SG_ VCFRONT_a618_ptInletTemp m618 : 40|6@1+ (2,0) [0|0] "" Vector__XXX
 SG_ VCFRONT_a623_failureLvBatteryEnergyActiveDecel m623 : 40|1@1+ (1,0) [0|0] "" Vector__XXX
 SG_ VCFRONT_a644_minCycleCurrent m644 : 40|8@1- (0.0984251968503937,5.807086614173229) [0|0] "" Vector__XXX
 SG_ VCFRONT_a645_fluidLevelSensorRawLowAnyPointOfCycle m645 : 40|1@1+ (1,0) [0|0] "" Vector__XXX
 SG_ VCFRONT_a646_timeSinceLastValidWash m646 : 40|14@1+ (1,0) [0|0] "" Vector__XXX
 SG_ VCFRONT_a667_homologationRegionOverride m667 : 40|2@1+ (1,0) [0|0] "" Vector__XXX
 SG_ VCFRONT_a668_homologationRegionOverride m668 : 40|2@1+ (1,0) [0|0] "" Vector__XXX
 SG_ VCFRONT_a063_indeterminate m63 : 41|1@1+ (1,0) [0|0] "" Vector__XXX
 SG_ VCFRONT_a104_VEH_control m104 : 41|1@1+ (1,0) [0|0] "" Vector__XXX
 SG_ VCFRONT_a113_CH_odo m113 : 41|1@1+ (1,0) [0|0] "" Vector__XXX
 SG_ VCFRONT_a118_BDY_vehicleTime m118 : 41|1@1+ (1,0) [0|0] "" Vector__XXX
 SG_ VCFRONT_a120_VEH_prndControl m120 : 41|1@1+ (1,0) [0|0] "" Vector__XXX
 SG_ VCFRONT_a171_IDB1 m171 : 41|1@1+ (1,0) [0|0] "" Vector__XXX
 SG_ VCFRONT_a188_timeNotSleeping m188 : 41|6@1+ (1,0) [0|0] "" Vector__XXX
 SG_ VCFRONT_a220_frunkOpen m220 : 41|1@1+ (1,0) [0|0] "" Vector__XXX
 SG_ VCFRONT_a257_epas3sFault m257 : 41|1@1+ (1,0) [0|0] "" Vector__XXX
 SG_ VCFRONT_a365_userChargeStatus m365 : 41|3@1+ (1,0) [0|0] "" Vector__XXX
 SG_ VCFRONT_a370_serviceMode m370 : 41|1@1+ (1,0) [0|0] "" Vector__XXX
 SG_ VCFRONT_a444_highSide1GateDriver m444 : 41|1@1+ (1,0) [0|0] "" Vector__XXX
 SG_ VCFRONT_a446_sensorHasOffsetTd m446 : 41|1@1+ (1,0) [0|0] "" Vector__XXX
 SG_ VCFRONT_a478_HVBlockingMismatch m478 : 41|1@1+ (1,0) [0|0] "" Vector__XXX
 SG_ VCFRONT_a480_hwlo m480 : 41|1@1+ (1,0) [0|0] "" Vector__XXX
 SG_ VCFRONT_a498_testAbortReason m498 : 41|3@1+ (1,0) [0|0] "" Vector__XXX
 SG_ VCFRONT_a510_frunkOpen m510 : 41|1@1+ (1,0) [0|0] "" Vector__XXX
 SG_ VCFRONT_a518_outputVoltageAtPCS m518 : 41|8@1+ (0.1,0) [0|0] "" Vector__XXX
 SG_ VCFRONT_a594_fusionSessionCalibration m594 : 41|9@1- (0.0005,0) [0|0] "" Vector__XXX
 SG_ VCFRONT_a611_coolantFlow m611 : 41|5@1+ (1,0) [0|0] "" Vector__XXX
 SG_ VCFRONT_a623_failureLvBatteryEnergyCritical m623 : 41|1@1+ (1,0) [0|0] "" Vector__XXX
 SG_ VCFRONT_a645_fluidLevelSensorFilteredLowEndOfCycle m645 : 41|1@1+ (1,0) [0|0] "" Vector__XXX
 SG_ VCFRONT_a063_stuckActive m63 : 42|1@1+ (1,0) [0|0] "" Vector__XXX
 SG_ VCFRONT_a104_BDY_bodyControls m104 : 42|1@1+ (1,0) [0|0] "" Vector__XXX
 SG_ VCFRONT_a113_VEH_locationStatus m113 : 42|1@1+ (1,0) [0|0] "" Vector__XXX
 SG_ VCFRONT_a118_PARTY_AP_vehicleState1HzMuxed m118 : 42|1@1+ (1,0) [0|0] "" Vector__XXX
 SG_ VCFRONT_a120_VEH_vehicleEstimates m120 : 42|1@1+ (1,0) [0|0] "" Vector__XXX
 SG_ VCFRONT_a171_IDBCAL m171 : 42|1@1+ (1,0) [0|0] "" Vector__XXX
 SG_ VCFRONT_a257_revBattFault m257 : 42|1@1+ (1,0) [0|0] "" Vector__XXX
 SG_ VCFRONT_a260_batterySMState m260 : 42|4@1+ (1,0) [0|0] "" Vector__XXX
 SG_ VCFRONT_a352_startTime m352 : 42|10@1+ (10,0) [0|0] "" Vector__XXX
 SG_ VCFRONT_a359_batterySMState m359 : 42|4@1+ (1,0) [0|0] "" Vector__XXX
 SG_ VCFRONT_a370_sleepCurrent m370 : 42|10@1+ (0.1,0) [0|0] "" Vector__XXX
 SG_ VCFRONT_a444_lowSide1GateDriver m444 : 42|1@1+ (1,0) [0|0] "" Vector__XXX
 SG_ VCFRONT_a446_sensorHasOffsetPd m446 : 42|1@1+ (1,0) [0|0] "" Vector__XXX
 SG_ VCFRONT_a478_HV_UP m478 : 42|1@1+ (1,0) [0|0] "" Vector__XXX
 SG_ VCFRONT_a480_enable m480 : 42|1@1+ (1,0) [0|0] "" Vector__XXX
 SG_ VCFRONT_a484_currentVehiclePitch m484 : 42|10@1- (0.0001,0) [0|0] "" Vector__XXX
 SG_ VCFRONT_a582_batteryType m582 : 42|3@1+ (1,0) [0|0] "" Vector__XXX
 SG_ VCFRONT_a584_switch1StuckReason m584 : 42|2@1+ (1,0) [0|0] "" Vector__XXX
 SG_ VCFRONT_a623_failureReverseBatteryEfuseOff m623 : 42|1@1+ (1,0) [0|0] "" Vector__XXX
 SG_ VCFRONT_a645_totalWashDuration m645 : 42|10@1+ (9.775171065493646,0) [0|0] "" Vector__XXX
 SG_ VCFRONT_a667_isRightHandDrive m667 : 42|1@1+ (1,0) [0|0] "" Vector__XXX
 SG_ VCFRONT_a668_isRightHandDrive m668 : 42|1@1+ (1,0) [0|0] "" Vector__XXX
 SG_ VCFRONT_a063_faulted m63 : 43|1@1+ (1,0) [0|0] "" Vector__XXX
 SG_ VCFRONT_a113_VEH_gpsTime m113 : 43|1@1+ (1,0) [0|0] "" Vector__XXX
 SG_ VCFRONT_a118_BDY_AP_vehicleState1HzMuxed m118 : 43|1@1+ (1,0) [0|0] "" Vector__XXX
 SG_ VCFRONT_a120_PARTY_motorStatus m120 : 43|1@1+ (1,0) [0|0] "" Vector__XXX
 SG_ VCFRONT_a162_ccRightExvFlow m162 : 43|7@1+ (1,0) [0|0] "" Vector__XXX
 SG_ VCFRONT_a171_RCU m171 : 43|1@1+ (1,0) [0|0] "" Vector__XXX
 SG_ VCFRONT_a187_ethBusRetryCount m187 : 43|9@1+ (1,0) [0|0] "" Vector__XXX
 SG_ VCFRONT_a257_vehicleState m257 : 43|5@1+ (1,0) [0|0] "" Vector__XXX
 SG_ VCFRONT_a366_chgNoFlowTetherStatus m366 : 43|2@1+ (1,0) [0|0] "" Vector__XXX
 SG_ VCFRONT_a414_IBSVoltage m414 : 43|11@1+ (0.01088735219,0) [0|0] "" Vector__XXX
 SG_ VCFRONT_a444_highSide2OverCurent m444 : 43|1@1+ (1,0) [0|0] "" Vector__XXX
 SG_ VCFRONT_a446_sensorDroopPd m446 : 43|1@1+ (1,0) [0|0] "" Vector__XXX
 SG_ VCFRONT_a474_drl3Status m474 : 43|3@1+ (1,0) [0|0] "" Vector__XXX
 SG_ VCFRONT_a475_drl3Status m475 : 43|3@1+ (1,0) [0|0] "" Vector__XXX
 SG_ VCFRONT_a477_cell4Voltage m477 : 43|9@1+ (0.01,0) [0|0] "" Vector__XXX
 SG_ VCFRONT_a478_pcsEFuseStable m478 : 43|1@1+ (1,0) [0|0] "" Vector__XXX
 SG_ VCFRONT_a606_ccQdotTotalAtExit m606 : 43|6@1+ (111.11111111111111,0) [0|0] "" Vector__XXX
 SG_ VCFRONT_a623_failureLvbmbEfuseOpen m623 : 43|1@1+ (1,0) [0|0] "" Vector__XXX
 SG_ VCFRONT_a627_cell4Voltage m627 : 43|9@1+ (0.01,0) [0|0] "" Vector__XXX
 SG_ VCFRONT_a113_VEH_gpsVehicleSpeed m113 : 44|1@1+ (1,0) [0|0] "" Vector__XXX
 SG_ VCFRONT_a118_PARTY_VCFRONT_cameraCleaningStatus m118 : 44|1@1+ (1,0) [0|0] "" Vector__XXX
 SG_ VCFRONT_a120_VEH_motorStatus m120 : 44|1@1+ (1,0) [0|0] "" Vector__XXX
 SG_ VCFRONT_a171_RCUCAL m171 : 44|1@1+ (1,0) [0|0] "" Vector__XXX
 SG_ VCFRONT_a184_evapOutTemp m184 : 44|5@1+ (1,0) [0|0] "" Vector__XXX
 SG_ VCFRONT_a190_maxResponseTime m190 : 44|8@1+ (0.1,0) [0|0] "" Vector__XXX
 SG_ VCFRONT_a191_ECPAState m191 : 44|2@1+ (1,0) [0|0] "" Vector__XXX
 SG_ VCFRONT_a258_maxCurrentReached m258 : 44|16@1- (0.005,0) [0|0] "" Vector__XXX
 SG_ VCFRONT_a365_chgNoFlowTetherStatus m365 : 44|2@1+ (1,0) [0|0] "" Vector__XXX
 SG_ VCFRONT_a444_lowSide2OverCurent m444 : 44|1@1+ (1,0) [0|0] "" Vector__XXX
 SG_ VCFRONT_a446_sensorHasOffsetTl m446 : 44|1@1+ (1,0) [0|0] "" Vector__XXX
 SG_ VCFRONT_a478_vcrightEFuseStable m478 : 44|1@1+ (1,0) [0|0] "" Vector__XXX
 SG_ VCFRONT_a498_targetVoltage m498 : 44|10@1+ (0.05,0) [0|0] "" Vector__XXX
 SG_ VCFRONT_a514_packVoltage m514 : 44|8@1+ (0.1,0) [0|0] "" Vector__XXX
 SG_ VCFRONT_a515_packVoltage m515 : 44|8@1+ (0.1,0) [0|0] "" Vector__XXX
 SG_ VCFRONT_a559_bmsState m559 : 44|4@1+ (1,0) [0|0] "" Vector__XXX
 SG_ VCFRONT_a584_switch2StuckReason m584 : 44|2@1+ (1,0) [0|0] "" Vector__XXX
 SG_ VCFRONT_a608_setFromNvm m608 : 44|1@1+ (1,0) [0|0] "" Vector__XXX
 SG_ VCFRONT_a623_failureLvBatteryComms m623 : 44|1@1+ (1,0) [0|0] "" Vector__XXX
 SG_ VCFRONT_a663_hcmlGroupsHighWaterMarkPercent_IC600 m663 : 44|5@1+ (3.225806451612903,0) [0|0] "" Vector__XXX
 SG_ VCFRONT_a664_hcmrGroupsHighWaterMarkPercent_IC600 m664 : 44|5@1+ (3.225806451612903,0) [0|0] "" Vector__XXX
 SG_ VCFRONT_a669_minPackSOC m669 : 44|9@1+ (0.2,0) [0|0] "" Vector__XXX
 SG_ VCFRONT_a113_VEH_status2 m113 : 45|1@1+ (1,0) [0|0] "" Vector__XXX
 SG_ VCFRONT_a120_BDY_speed m120 : 45|1@1+ (1,0) [0|0] "" Vector__XXX
 SG_ VCFRONT_a171_DPB m171 : 45|1@1+ (1,0) [0|0] "" Vector__XXX
 SG_ VCFRONT_a178_ambientTempFiltered m178 : 45|8@1+ (0.5,-40) [0|0] "" Vector__XXX
 SG_ VCFRONT_a366_updateInProgress m366 : 45|1@1+ (1,0) [0|0] "" Vector__XXX
 SG_ VCFRONT_a403_IBSTemp m403 : 45|7@1+ (1,-40) [0|0] "" Vector__XXX
 SG_ VCFRONT_a444_highSide1OverCurent m444 : 45|1@1+ (1,0) [0|0] "" Vector__XXX
 SG_ VCFRONT_a446_sensorIntermittentPs m446 : 45|1@1+ (1,0) [0|0] "" Vector__XXX
 SG_ VCFRONT_a478_contactorEFuseStable m478 : 45|1@1+ (1,0) [0|0] "" Vector__XXX
 SG_ VCFRONT_a541_AverageCurrent m541 : 45|10@1+ (0.05,0) [0|0] "" Vector__XXX
 SG_ VCFRONT_a548_serviceMode m548 : 45|1@1+ (1,0) [0|0] "" Vector__XXX
 SG_ VCFRONT_a582_inFactoryMode m582 : 45|1@1+ (1,0) [0|0] "" Vector__XXX
 SG_ VCFRONT_a623_failureLvBatterySensorIbsMia m623 : 45|1@1+ (1,0) [0|0] "" Vector__XXX
 SG_ VCFRONT_a113_VEH_autopilotControl m113 : 46|1@1+ (1,0) [0|0] "" Vector__XXX
 SG_ VCFRONT_a171_DPBCAL m171 : 46|1@1+ (1,0) [0|0] "" Vector__XXX
 SG_ VCFRONT_a191_LVBMSCurrentTargetValid m191 : 46|1@1+ (1,0) [0|0] "" Vector__XXX
 SG_ VCFRONT_a260_HV_UP m260 : 46|1@1+ (1,0) [0|0] "" Vector__XXX
 SG_ VCFRONT_a365_updateInProgress m365 : 46|1@1+ (1,0) [0|0] "" Vector__XXX
 SG_ VCFRONT_a366_dcCharging m366 : 46|1@1+ (1,0) [0|0] "" Vector__XXX
 SG_ VCFRONT_a407_pulseCurrentVarianceShifted m407 : 46|6@1+ (0.25,0) [0|0] "" Vector__XXX
 SG_ VCFRONT_a408_IBSTemp m408 : 46|7@1+ (1,-40) [0|0] "" Vector__XXX
 SG_ VCFRONT_a416_socMin m416 : 46|8@1+ (0.5,0) [0|0] "" Vector__XXX
 SG_ VCFRONT_a417_socMax m417 : 46|8@1+ (0.5,0) [0|0] "" Vector__XXX
 SG_ VCFRONT_a418_socMax m418 : 46|8@1+ (0.5,0) [0|0] "" Vector__XXX
 SG_ VCFRONT_a419_socMin m419 : 46|8@1+ (0.5,0) [0|0] "" Vector__XXX
 SG_ VCFRONT_a423_socMin m423 : 46|8@1+ (0.5,0) [0|0] "" Vector__XXX
 SG_ VCFRONT_a424_socMin m424 : 46|8@1+ (0.5,0) [0|0] "" Vector__XXX
 SG_ VCFRONT_a444_lowSide1OverCurent m444 : 46|1@1+ (1,0) [0|0] "" Vector__XXX
 SG_ VCFRONT_a446_sensorIntermittentPd m446 : 46|1@1+ (1,0) [0|0] "" Vector__XXX
 SG_ VCFRONT_a478_hvcEFuseStable m478 : 46|1@1+ (1,0) [0|0] "" Vector__XXX
 SG_ VCFRONT_a481_stuckOnFinished m481 : 46|1@1+ (1,0) [0|0] "" Vector__XXX
 SG_ VCFRONT_a503_socMax m503 : 46|8@1+ (0.5,0) [0|0] "" Vector__XXX
 SG_ VCFRONT_a527_cell4Voltage m527 : 46|10@1+ (0.01,0) [0|0] "" Vector__XXX
 SG_ VCFRONT_a548_frunkOpen m548 : 46|1@1+ (1,0) [0|0] "" Vector__XXX
 SG_ VCFRONT_a555_cell4Voltage m555 : 46|10@1+ (0.01,0) [0|0] "" Vector__XXX
 SG_ VCFRONT_a561_cell3Voltage m561 : 46|7@1+ (0.04,0) [0|0] "" Vector__XXX
 SG_ VCFRONT_a562_cell3Voltage m562 : 46|7@1+ (0.04,0) [0|0] "" Vector__XXX
 SG_ VCFRONT_a582_frunkOpen m582 : 46|1@1+ (1,0) [0|0] "" Vector__XXX
 SG_ VCFRONT_a584_firstFaultedSwitch m584 : 46|3@1+ (1,0) [0|0] "" Vector__XXX
 SG_ VCFRONT_a611_compressorPower m611 : 46|6@1+ (200,0) [0|0] "" Vector__XXX
 SG_ VCFRONT_a623_failureLvBatteryConnection m623 : 46|1@1+ (1,0) [0|0] "" Vector__XXX
 SG_ VCFRONT_a626_pulseCurrentVarianceShifted m626 : 46|6@1+ (0.25,0) [0|0] "" Vector__XXX
 SG_ VCFRONT_a634_ajar2ClosingDeltaV m634 : 46|10@1- (0.01,0) [0|0] "" Vector__XXX
 SG_ VCFRONT_a113_VEH_ambientLightingCtrls m113 : 47|1@1+ (1,0) [0|0] "" Vector__XXX
 SG_ VCFRONT_a171_serviceMode m171 : 47|1@1+ (1,0) [0|0] "" Vector__XXX
 SG_ VCFRONT_a182_chargedAmpHours m182 : 47|8@1+ (60,0) [0|0] "" Vector__XXX
 SG_ VCFRONT_a183_chargedAmpHours m183 : 47|8@1+ (60,0) [0|0] "" Vector__XXX
 SG_ VCFRONT_a188_chargeRequest m188 : 47|1@1+ (1,0) [0|0] "" Vector__XXX
 SG_ VCFRONT_a191_LVBMSVoltageTargetValid m191 : 47|1@1+ (1,0) [0|0] "" Vector__XXX
 SG_ VCFRONT_a197_validityStatus m197 : 47|7@1+ (1,0) [0|0] "" Vector__XXX
 SG_ VCFRONT_a260_notEnoughPowerForSupport m260 : 47|1@1+ (1,0) [0|0] "" Vector__XXX
 SG_ VCFRONT_a365_dcCharging m365 : 47|1@1+ (1,0) [0|0] "" Vector__XXX
 SG_ VCFRONT_a366_finishedSuccessfully m366 : 47|1@1+ (1,0) [0|0] "" Vector__XXX
 SG_ VCFRONT_a406_pulseCurrentVariance m406 : 47|6@1+ (0.25,0) [0|0] "" Vector__XXX
 SG_ VCFRONT_a415_IBSAmpHours m415 : 47|7@1+ (0.02,-2.55) [0|0] "" Vector__XXX
 SG_ VCFRONT_a444_spiInit m444 : 47|1@1+ (1,0) [0|0] "" Vector__XXX
 SG_ VCFRONT_a446_sensorIntermittentPl m446 : 47|1@1+ (1,0) [0|0] "" Vector__XXX
 SG_ VCFRONT_a465_flaggedAtSteadyState m465 : 47|1@1+ (1,0) [0|0] "" Vector__XXX
 SG_ VCFRONT_a478_frunkOpen m478 : 47|1@1+ (1,0) [0|0] "" Vector__XXX
 SG_ VCFRONT_a481_stuckOnFailure m481 : 47|1@1+ (1,0) [0|0] "" Vector__XXX
 SG_ VCFRONT_a623_failureLvBatteryConnectionUnknown m623 : 47|1@1+ (1,0) [0|0] "" Vector__XXX
 SG_ VCFRONT_a000_alertDataW2 m0 : 48|16@1+ (1,0) [0|0] "" Vector__XXX
 SG_ VCFRONT_a003_Data m3 : 48|16@1+ (1,0) [0|0] "" Vector__XXX
 SG_ VCFRONT_a009_subcoolAtExit m9 : 48|5@1- (1,6) [0|0] "" Vector__XXX
 SG_ VCFRONT_a022_TaskInitError3 m22 : 48|8@1+ (1,0) [0|0] "" Vector__XXX
 SG_ VCFRONT_a031_uds_bytes_4 m31 : 48|8@1+ (1,0) [0|0] "" Vector__XXX
 SG_ VCFRONT_a041_CPULoad1000msTask m41 : 48|8@1+ (1,0) [0|0] "" Vector__XXX
 SG_ VCFRONT_a042_UsageUDSTask m42 : 48|8@1+ (1,0) [0|0] "" Vector__XXX
 SG_ VCFRONT_a113_VEH_driverAssistMapData m113 : 48|1@1+ (1,0) [0|0] "" Vector__XXX
 SG_ VCFRONT_a127_vcleftEFuseTemp m127 : 48|11@1+ (0.125,-40) [0|0] "" Vector__XXX
 SG_ VCFRONT_a128_vcrightEFuseTemp m128 : 48|11@1+ (0.125,-40) [0|0] "" Vector__XXX
 SG_ VCFRONT_a129_pcsEFuseTemp m129 : 48|11@1+ (0.125,-40) [0|0] "" Vector__XXX
 SG_ VCFRONT_a130_epas3pEFuseTemp m130 : 48|11@1+ (0.125,-40) [0|0] "" Vector__XXX
 SG_ VCFRONT_a131_epas3sEFuseTemp m131 : 48|11@1+ (0.125,-40) [0|0] "" Vector__XXX
 SG_ VCFRONT_a132_iBoosterEFuseTemp m132 : 48|11@1+ (0.125,-40) [0|0] "" Vector__XXX
 SG_ VCFRONT_a133_espEFuseTemp m133 : 48|11@1+ (0.125,-40) [0|0] "" Vector__XXX
 SG_ VCFRONT_a134_fusedHighTemp m134 : 48|11@1+ (0.125,-40) [0|0] "" Vector__XXX
 SG_ VCFRONT_a154_lastSilentWakeTimeSlept m154 : 48|8@1+ (0.2,0) [0|0] "" Vector__XXX
 SG_ VCFRONT_a155_minHVComingUpIBSTemperature m155 : 48|7@1+ (1,-24) [0|0] "" Vector__XXX
 SG_ VCFRONT_a180_IBSVoltage m180 : 48|8@1+ (0.08741903380905883,0) [0|0] "" Vector__XXX
 SG_ VCFRONT_a188_12VSupport m188 : 48|1@1+ (1,0) [0|0] "" Vector__XXX
 SG_ VCFRONT_a191_serviceMode m191 : 48|1@1+ (1,0) [0|0] "" Vector__XXX
 SG_ VCFRONT_a192_PCSCurrent m192 : 48|8@1+ (0.5,-127) [0|0] "" Vector__XXX
 SG_ VCFRONT_a196_disconnectedBatteryTestPrevVoltage m196 : 48|8@1+ (0.0392156862745098,6) [0|0] "" Vector__XXX
 SG_ VCFRONT_a213_LVBatteryTemp m213 : 48|16@1- (0.01,0) [0|0] "" Vector__XXX
 SG_ VCFRONT_a219_IBSCurrent m219 : 48|16@1- (0.005,0) [0|0] "" Vector__XXX
 SG_ VCFRONT_a242_IBSAmpHours m242 : 48|8@1+ (0.01,-2.55) [0|0] "" Vector__XXX
 SG_ VCFRONT_a243_LVBatteryTemp m243 : 48|16@1- (0.01,0) [0|0] "" Vector__XXX
 SG_ VCFRONT_a244_vbatProtVoltage m244 : 48|16@1+ (0.1,0) [0|0] "" Vector__XXX
 SG_ VCFRONT_a245_eFuseRemainingRetries m245 : 48|4@1+ (1,0) [0|0] "" Vector__XXX
 SG_ VCFRONT_a246_eFuseRemainingRetries m246 : 48|4@1+ (1,0) [0|0] "" Vector__XXX
 SG_ VCFRONT_a252_IBSCurrent m252 : 48|16@1- (0.005,0) [0|0] "" Vector__XXX
 SG_ VCFRONT_a253_LVBatteryTemp m253 : 48|7@1+ (1,-40) [0|0] "" Vector__XXX
 SG_ VCFRONT_a259_maxCurrentReached m259 : 48|16@1- (0.005,0) [0|0] "" Vector__XXX
 SG_ VCFRONT_a260_coolantHasBeenFilled m260 : 48|1@1+ (1,0) [0|0] "" Vector__XXX
 SG_ VCFRONT_a269_IBSAmpHours m269 : 48|8@1+ (0.01,-2.55) [0|0] "" Vector__XXX
 SG_ VCFRONT_a283_thmlFanPhaseILimit m283 : 48|7@1+ (0.25,0) [0|0] "" Vector__XXX
 SG_ VCFRONT_a303_lockStatus m303 : 48|2@1+ (1,0) [0|0] "" Vector__XXX
 SG_ VCFRONT_a309_lockStatus m309 : 48|2@1+ (1,0) [0|0] "" Vector__XXX
 SG_ VCFRONT_a326_vehicleState m326 : 48|2@1+ (1,0) [0|0] "" Vector__XXX
 SG_ VCFRONT_a327_vehicleState m327 : 48|2@1+ (1,0) [0|0] "" Vector__XXX
 SG_ VCFRONT_a328_vehicleState m328 : 48|2@1+ (1,0) [0|0] "" Vector__XXX
 SG_ VCFRONT_a329_vehicleState m329 : 48|2@1+ (1,0) [0|0] "" Vector__XXX
 SG_ VCFRONT_a330_vehicleState m330 : 48|2@1+ (1,0) [0|0] "" Vector__XXX
 SG_ VCFRONT_a331_vehicleState m331 : 48|2@1+ (1,0) [0|0] "" Vector__XXX
 SG_ VCFRONT_a332_vehicleState m332 : 48|2@1+ (1,0) [0|0] "" Vector__XXX
 SG_ VCFRONT_a333_vehicleState m333 : 48|2@1+ (1,0) [0|0] "" Vector__XXX
 SG_ VCFRONT_a359_hvState m359 : 48|3@1+ (1,0) [0|0] "" Vector__XXX
 SG_ VCFRONT_a363_checkIntervalDays m363 : 48|5@1+ (1,0) [0|0] "" Vector__XXX
 SG_ VCFRONT_a365_pcsTooHot m365 : 48|1@1+ (1,0) [0|0] "" Vector__XXX
 SG_ VCFRONT_a366_pcsReportsUnavailable m366 : 48|1@1+ (1,0) [0|0] "" Vector__XXX
 SG_ VCFRONT_a387_maxCurrentReached m387 : 48|16@1- (0.005,0) [0|0] "" Vector__XXX
 SG_ VCFRONT_a388_maxCurrentReached m388 : 48|16@1- (0.005,0) [0|0] "" Vector__XXX
 SG_ VCFRONT_a401_IBSAmpHours m401 : 48|8@1+ (0.01,-2.55) [0|0] "" Vector__XXX
 SG_ VCFRONT_a404_maxCurrentReached m404 : 48|16@1- (0.005,0) [0|0] "" Vector__XXX
 SG_ VCFRONT_a405_avgIntervalCurrent m405 : 48|5@1+ (1,-31) [0|0] "" Vector__XXX
 SG_ VCFRONT_a410_IBSAmpHours m410 : 48|8@1+ (0.01,-2.55) [0|0] "" Vector__XXX
 SG_ VCFRONT_a411_IBSAmpHours m411 : 48|8@1+ (0.01,-2.55) [0|0] "" Vector__XXX
 SG_ VCFRONT_a412_avgPulseCurrentShifted m412 : 48|7@1+ (1,-127) [0|0] "" Vector__XXX
 SG_ VCFRONT_a421_hcmlTxBufferHighWaterMarkPercent m421 : 48|5@1+ (3.225806451612903,0) [0|0] "" Vector__XXX
 SG_ VCFRONT_a427_cacChangeBrickId m427 : 48|7@1+ (1,1) [0|0] "" Vector__XXX
 SG_ VCFRONT_a430_hvjbCurrentLimit m430 : 48|16@1- (0.1,0) [0|0] "" Vector__XXX
 SG_ VCFRONT_a431_hvjbCurrentLimit m431 : 48|16@1- (0.1,0) [0|0] "" Vector__XXX
 SG_ VCFRONT_a433_bmbModuleIdValid m433 : 48|1@1+ (1,0) [0|0] "" Vector__XXX
 SG_ VCFRONT_a434_bmbModuleIdValid m434 : 48|1@1+ (1,0) [0|0] "" Vector__XXX
 SG_ VCFRONT_a435_hvjbCurrentLimit m435 : 48|16@1- (0.1,0) [0|0] "" Vector__XXX
 SG_ VCFRONT_a436_hvjbCurrentLimit m436 : 48|16@1- (0.1,0) [0|0] "" Vector__XXX
 SG_ VCFRONT_a442_brickChangeHystRatio m442 : 48|10@1+ (0.001,0) [0|0] "" Vector__XXX
 SG_ VCFRONT_a444_spiPeriodicCheck m444 : 48|1@1+ (1,0) [0|0] "" Vector__XXX
 SG_ VCFRONT_a445_actualLSB m445 : 48|8@1+ (1,0) [0|0] "" Vector__XXX
 SG_ VCFRONT_a446_sensorIntermittentTs m446 : 48|1@1+ (1,0) [0|0] "" Vector__XXX
 SG_ VCFRONT_a461_numBricksHighSocAhError m461 : 48|8@1+ (1,0) [0|0] "" Vector__XXX
 SG_ VCFRONT_a465_flaggedAtUnsteadyState m465 : 48|1@1+ (1,0) [0|0] "" Vector__XXX
 SG_ VCFRONT_a474_turnStatus m474 : 48|3@1+ (1,0) [0|0] "" Vector__XXX
 SG_ VCFRONT_a475_turnStatus m475 : 48|3@1+ (1,0) [0|0] "" Vector__XXX
 SG_ VCFRONT_a481_hardShortThresholdReached m481 : 48|1@1+ (1,0) [0|0] "" Vector__XXX
 SG_ VCFRONT_a492_avgBrickSoc m492 : 48|8@1+ (0.5,0) [0|0] "" Vector__XXX
 SG_ VCFRONT_a493_maxBrickSoc m493 : 48|7@1+ (1,0) [0|0] "" Vector__XXX
 SG_ VCFRONT_a497_SumCellVoltage m497 : 48|8@1+ (0.1,0) [0|0] "" Vector__XXX
 SG_ VCFRONT_a509_serviceMode m509 : 48|1@1+ (1,0) [0|0] "" Vector__XXX
 SG_ VCFRONT_a511_hvState m511 : 48|3@1+ (1,0) [0|0] "" Vector__XXX
 SG_ VCFRONT_a512_overcurrentDirection m512 : 48|2@1+ (1,0) [0|0] "" Vector__XXX
 SG_ VCFRONT_a513_packSOC m513 : 48|10@1+ (0.1,0) [0|0] "" Vector__XXX
 SG_ VCFRONT_a521_serviceMode m521 : 48|1@1+ (1,0) [0|0] "" Vector__XXX
 SG_ VCFRONT_a523_control3Byte2 m523 : 48|8@1+ (1,0) [0|0] "" Vector__XXX
 SG_ VCFRONT_a529_externalPowerSupply m529 : 48|1@1+ (1,0) [0|0] "" Vector__XXX
 SG_ VCFRONT_a530_vehicleState m530 : 48|2@1+ (1,0) [0|0] "" Vector__XXX
 SG_ VCFRONT_a542_ambientTempFiltered m542 : 48|8@1+ (0.5,-40) [0|0] "" Vector__XXX
 SG_ VCFRONT_a548_PCSTargetVoltage m548 : 48|8@1+ (0.1,0) [0|0] "" Vector__XXX
 SG_ VCFRONT_a556_disconnectedBatteryTestPrevVoltage m556 : 48|8@1+ (0.0392156862745098,6) [0|0] "" Vector__XXX
 SG_ VCFRONT_a558_levelingOffsetPriorToAiming m558 : 48|8@1- (1,0) [0|0] "" Vector__XXX
 SG_ VCFRONT_a559_dcdcLVSupportStatus m559 : 48|2@1+ (1,0) [0|0] "" Vector__XXX
 SG_ VCFRONT_a564_levelingOffsetPriorToAiming m564 : 48|8@1- (1,0) [0|0] "" Vector__XXX
 SG_ VCFRONT_a579_leftHeadlightRemainingRetries m579 : 48|4@1+ (1,0) [0|0] "" Vector__XXX
 SG_ VCFRONT_a580_rightHeadlightRemainingRetries m580 : 48|4@1+ (1,0) [0|0] "" Vector__XXX
 SG_ VCFRONT_a588_vcleftCTerm m588 : 48|16@1- (50,0) [0|0] "" Vector__XXX
 SG_ VCFRONT_a589_vcleftMaxCount m589 : 48|5@1+ (1,0) [0|0] "" Vector__XXX
 SG_ VCFRONT_a590_vcrightCTerm m590 : 48|16@1- (50,0) [0|0] "" Vector__XXX
 SG_ VCFRONT_a591_vcrightMaxCount m591 : 48|5@1+ (1,0) [0|0] "" Vector__XXX
 SG_ VCFRONT_a592_vcleftCutoffCTerm m592 : 48|16@1- (50,0) [0|0] "" Vector__XXX
 SG_ VCFRONT_a593_vcleftCutoffMaxCount m593 : 48|5@1+ (1,0) [0|0] "" Vector__XXX
 SG_ VCFRONT_a596_vcrightCutoffCTerm m596 : 48|16@1- (50,0) [0|0] "" Vector__XXX
 SG_ VCFRONT_a597_vcrightCutoffMaxCount m597 : 48|5@1+ (1,0) [0|0] "" Vector__XXX
 SG_ VCFRONT_a618_relativeHumidity m618 : 48|6@1+ (0.02,0) [0|0] "" Vector__XXX
 SG_ VCFRONT_a623_failurePcsEfuseOff m623 : 48|1@1+ (1,0) [0|0] "" Vector__XXX
 SG_ VCFRONT_a635_sleepShutdownCompleteCore1 m635 : 48|1@1+ (1,0) [0|0] "" Vector__XXX
 SG_ VCFRONT_a643_hcmrTxBufferHighWaterMarkPercent m643 : 48|5@1+ (3.225806451612903,0) [0|0] "" Vector__XXX
 SG_ VCFRONT_a644_maxCycleCurrent m644 : 48|8@1- (0.0984251968503937,5.807086614173229) [0|0] "" Vector__XXX
 SG_ VCFRONT_a113_CH_vehicleControl2 m113 : 49|1@1+ (1,0) [0|0] "" Vector__XXX
 SG_ VCFRONT_a184_evapOutTempNominal m184 : 49|5@1+ (1,0) [0|0] "" Vector__XXX
 SG_ VCFRONT_a188_ThermalSupport m188 : 49|1@1+ (1,0) [0|0] "" Vector__XXX
 SG_ VCFRONT_a191_frunkOpen m191 : 49|1@1+ (1,0) [0|0] "" Vector__XXX
 SG_ VCFRONT_a260_ampHourTrigger m260 : 49|1@1+ (1,0) [0|0] "" Vector__XXX
 SG_ VCFRONT_a365_pcsReportsUnavailable m365 : 49|1@1+ (1,0) [0|0] "" Vector__XXX
 SG_ VCFRONT_a366_bmsTooHot m366 : 49|1@1+ (1,0) [0|0] "" Vector__XXX
 SG_ VCFRONT_a433_useBmbModuleId m433 : 49|1@1+ (1,0) [0|0] "" Vector__XXX
 SG_ VCFRONT_a434_useBmbModuleId m434 : 49|1@1+ (1,0) [0|0] "" Vector__XXX
 SG_ VCFRONT_a444_spiFault m444 : 49|1@1+ (1,0) [0|0] "" Vector__XXX
 SG_ VCFRONT_a446_sensorIntermittentTd m446 : 49|1@1+ (1,0) [0|0] "" Vector__XXX
 SG_ VCFRONT_a481_softShortThresholdReached m481 : 49|1@1+ (1,0) [0|0] "" Vector__XXX
 SG_ VCFRONT_a509_frunkOpen m509 : 49|1@1+ (1,0) [0|0] "" Vector__XXX
 SG_ VCFRONT_a518_packSOC m518 : 49|10@1+ (0.1,0) [0|0] "" Vector__XXX
 SG_ VCFRONT_a521_frunkOpen m521 : 49|1@1+ (1,0) [0|0] "" Vector__XXX
 SG_ VCFRONT_a529_LVBusVoltageNotControllable m529 : 49|1@1+ (1,0) [0|0] "" Vector__XXX
 SG_ VCFRONT_a584_elapsedTime m584 : 49|15@1+ (100,0) [0|0] "" Vector__XXX
 SG_ VCFRONT_a606_battLPMBeforeEntry m606 : 49|5@1+ (1,0) [0|0] "" Vector__XXX
 SG_ VCFRONT_a623_failurePcsNotActive m623 : 49|1@1+ (1,0) [0|0] "" Vector__XXX
 SG_ VCFRONT_a635_sleepShutdownCompleteCore2 m635 : 49|1@1+ (1,0) [0|0] "" Vector__XXX
 SG_ VCFRONT_a663_hcmlValidatedGroupsHighWaterMarkPercent_IC600 m663 : 49|5@1+ (3.225806451612903,0) [0|0] "" Vector__XXX
 SG_ VCFRONT_a664_hcmrValidatedGroupsHighWaterMarkPercent_IC600 m664 : 49|5@1+ (3.225806451612903,0) [0|0] "" Vector__XXX
 SG_ VCFRONT_a113_VEH_odo m113 : 50|1@1+ (1,0) [0|0] "" Vector__XXX
 SG_ VCFRONT_a162_evapExvFlow m162 : 50|7@1+ (1,0) [0|0] "" Vector__XXX
 SG_ VCFRONT_a188_accessoryRequest m188 : 50|1@1+ (1,0) [0|0] "" Vector__XXX
 SG_ VCFRONT_a191_vehicleLoadShedStage m191 : 50|2@1+ (1,0) [0|0] "" Vector__XXX
 SG_ VCFRONT_a250_calibratedHorizontalPositionHCMR m250 : 50|10@1+ (1,0) [0|0] "" Vector__XXX
 SG_ VCFRONT_a260_voltageTrigger m260 : 50|1@1+ (1,0) [0|0] "" Vector__XXX
 SG_ VCFRONT_a365_bmsTooHot m365 : 50|1@1+ (1,0) [0|0] "" Vector__XXX
 SG_ VCFRONT_a379_timeBelowVoltageThreshold m379 : 50|6@1+ (32,0) [0|0] "" Vector__XXX
 SG_ VCFRONT_a429_duration m429 : 50|6@1+ (1,-1) [0|0] "" Vector__XXX
 SG_ VCFRONT_a444_voltageMonitor m444 : 50|1@1+ (1,0) [0|0] "" Vector__XXX
 SG_ VCFRONT_a446_sensorIntermittentTl m446 : 50|1@1+ (1,0) [0|0] "" Vector__XXX
 SG_ VCFRONT_a481_currentSenseVoltageDiff m481 : 50|8@1+ (1,0) [0|0] "" Vector__XXX
 SG_ VCFRONT_a512_serviceMode m512 : 50|1@1+ (1,0) [0|0] "" Vector__XXX
 SG_ VCFRONT_a559_factoryMode m559 : 50|1@1+ (1,0) [0|0] "" Vector__XXX
 SG_ VCFRONT_a594_lifetimeSampleCount m594 : 50|10@1+ (100,0) [0|0] "" Vector__XXX
 SG_ VCFRONT_a623_failurePcsMia m623 : 50|1@1+ (1,0) [0|0] "" Vector__XXX
 SG_ VCFRONT_a635_didCore1EverSleep m635 : 50|1@1+ (1,0) [0|0] "" Vector__XXX
 SG_ VCFRONT_a058_newREstimate m58 : 51|12@1+ (0.00061,0) [0|0] "" Vector__XXX
 SG_ VCFRONT_a188_CANAfterQuiet m188 : 51|1@1+ (1,0) [0|0] "" Vector__XXX
 SG_ VCFRONT_a260_crashDetected m260 : 51|1@1+ (1,0) [0|0] "" Vector__XXX
 SG_ VCFRONT_a310_vehicleState m310 : 51|2@1+ (1,0) [0|0] "" Vector__XXX
 SG_ VCFRONT_a311_vehicleState m311 : 51|2@1+ (1,0) [0|0] "" Vector__XXX
 SG_ VCFRONT_a312_vehicleState m312 : 51|2@1+ (1,0) [0|0] "" Vector__XXX
 SG_ VCFRONT_a313_vehicleState m313 : 51|2@1+ (1,0) [0|0] "" Vector__XXX
 SG_ VCFRONT_a314_vehicleState m314 : 51|2@1+ (1,0) [0|0] "" Vector__XXX
 SG_ VCFRONT_a315_vehicleState m315 : 51|2@1+ (1,0) [0|0] "" Vector__XXX
 SG_ VCFRONT_a316_vehicleState m316 : 51|2@1+ (1,0) [0|0] "" Vector__XXX
 SG_ VCFRONT_a317_vehicleState m317 : 51|2@1+ (1,0) [0|0] "" Vector__XXX
 SG_ VCFRONT_a318_vehicleState m318 : 51|2@1+ (1,0) [0|0] "" Vector__XXX
 SG_ VCFRONT_a319_vehicleState m319 : 51|2@1+ (1,0) [0|0] "" Vector__XXX
 SG_ VCFRONT_a320_vehicleState m320 : 51|2@1+ (1,0) [0|0] "" Vector__XXX
 SG_ VCFRONT_a321_vehicleState m321 : 51|2@1+ (1,0) [0|0] "" Vector__XXX
 SG_ VCFRONT_a322_vehicleState m322 : 51|2@1+ (1,0) [0|0] "" Vector__XXX
 SG_ VCFRONT_a323_vehicleState m323 : 51|2@1+ (1,0) [0|0] "" Vector__XXX
 SG_ VCFRONT_a324_vehicleState m324 : 51|2@1+ (1,0) [0|0] "" Vector__XXX
 SG_ VCFRONT_a325_vehicleState m325 : 51|2@1+ (1,0) [0|0] "" Vector__XXX
 SG_ VCFRONT_a359_coolantHasBeenFilled m359 : 51|1@1+ (1,0) [0|0] "" Vector__XXX
 SG_ VCFRONT_a444_enableLow m444 : 51|1@1+ (1,0) [0|0] "" Vector__XXX
 SG_ VCFRONT_a446_highSuctionSuperheat m446 : 51|1@1+ (1,0) [0|0] "" Vector__XXX
 SG_ VCFRONT_a474_fanStatus m474 : 51|1@1+ (1,0) [0|0] "" Vector__XXX
 SG_ VCFRONT_a475_fanStatus m475 : 51|1@1+ (1,0) [0|0] "" Vector__XXX
 SG_ VCFRONT_a511_DCDCOutputIsLimited m511 : 51|1@1+ (1,0) [0|0] "" Vector__XXX
 SG_ VCFRONT_a512_frunkOpen m512 : 51|1@1+ (1,0) [0|0] "" Vector__XXX
 SG_ VCFRONT_a559_serviceMode m559 : 51|1@1+ (1,0) [0|0] "" Vector__XXX
 SG_ VCFRONT_a623_failurePcsOpenCircuit m623 : 51|1@1+ (1,0) [0|0] "" Vector__XXX
 SG_ VCFRONT_a635_didCore2EverSleep m635 : 51|1@1+ (1,0) [0|0] "" Vector__XXX
 SG_ VCFRONT_a187_chBusRetryCount m187 : 52|9@1+ (1,0) [0|0] "" Vector__XXX
 SG_ VCFRONT_a188_SleepRequestTimeout m188 : 52|1@1+ (1,0) [0|0] "" Vector__XXX
 SG_ VCFRONT_a190_maxMessagePeriod m190 : 52|12@1+ (1,0) [0|0] "" Vector__XXX
 SG_ VCFRONT_a191_exitDriveWarningTimerExpired m191 : 52|1@1+ (1,0) [0|0] "" Vector__XXX
 SG_ VCFRONT_a248_voltageCalScaling m248 : 52|12@1+ (0.025,0) [0|0] "" Vector__XXX
 SG_ VCFRONT_a260_BMS_MIA m260 : 52|1@1+ (1,0) [0|0] "" Vector__XXX
 SG_ VCFRONT_a334_vehicleState m334 : 52|2@1+ (1,0) [0|0] "" Vector__XXX
 SG_ VCFRONT_a335_vehicleState m335 : 52|2@1+ (1,0) [0|0] "" Vector__XXX
 SG_ VCFRONT_a336_vehicleState m336 : 52|2@1+ (1,0) [0|0] "" Vector__XXX
 SG_ VCFRONT_a337_vehicleState m337 : 52|2@1+ (1,0) [0|0] "" Vector__XXX
 SG_ VCFRONT_a338_vehicleState m338 : 52|2@1+ (1,0) [0|0] "" Vector__XXX
 SG_ VCFRONT_a339_vehicleState m339 : 52|2@1+ (1,0) [0|0] "" Vector__XXX
 SG_ VCFRONT_a340_vehicleState m340 : 52|2@1+ (1,0) [0|0] "" Vector__XXX
 SG_ VCFRONT_a341_vehicleState m341 : 52|2@1+ (1,0) [0|0] "" Vector__XXX
 SG_ VCFRONT_a342_vehicleState m342 : 52|2@1+ (1,0) [0|0] "" Vector__XXX
 SG_ VCFRONT_a343_vehicleState m343 : 52|2@1+ (1,0) [0|0] "" Vector__XXX
 SG_ VCFRONT_a344_vehicleState m344 : 52|2@1+ (1,0) [0|0] "" Vector__XXX
 SG_ VCFRONT_a345_vehicleState m345 : 52|2@1+ (1,0) [0|0] "" Vector__XXX
 SG_ VCFRONT_a346_vehicleState m346 : 52|2@1+ (1,0) [0|0] "" Vector__XXX
 SG_ VCFRONT_a347_vehicleState m347 : 52|2@1+ (1,0) [0|0] "" Vector__XXX
 SG_ VCFRONT_a348_vehicleState m348 : 52|2@1+ (1,0) [0|0] "" Vector__XXX
 SG_ VCFRONT_a349_vehicleState m349 : 52|2@1+ (1,0) [0|0] "" Vector__XXX
 SG_ VCFRONT_a352_duration m352 : 52|10@1+ (1,0) [0|0] "" Vector__XXX
 SG_ VCFRONT_a359_crashDetected m359 : 52|1@1+ (1,0) [0|0] "" Vector__XXX
 SG_ VCFRONT_a370_SOC m370 : 52|3@1+ (2.5,5) [0|0] "" Vector__XXX
 SG_ VCFRONT_a403_chargeTime m403 : 52|10@1+ (1,0) [0|0] "" Vector__XXX
 SG_ VCFRONT_a407_IBSTemperature m407 : 52|8@1+ (0.5,-30) [0|0] "" Vector__XXX
 SG_ VCFRONT_a446_evapLowPsCutout m446 : 52|1@1+ (1,0) [0|0] "" Vector__XXX
 SG_ VCFRONT_a474_TPS92520_COMPOV m474 : 52|1@1+ (1,0) [0|0] "" Vector__XXX
 SG_ VCFRONT_a475_TPS92520_COMPOV m475 : 52|1@1+ (1,0) [0|0] "" Vector__XXX
 SG_ VCFRONT_a477_sumCellVoltage m477 : 52|8@1+ (0.1,0) [0|0] "" Vector__XXX
 SG_ VCFRONT_a484_headlampAimingDebugReason m484 : 52|3@1+ (1,0) [0|0] "" Vector__XXX
 SG_ VCFRONT_a502_shortImpedance m502 : 52|10@1+ (1,0) [0|0] "" Vector__XXX
 SG_ VCFRONT_a511_PCSSignalsAreValid m511 : 52|1@1+ (1,0) [0|0] "" Vector__XXX
 SG_ VCFRONT_a512_vehiclePowerState m512 : 52|2@1+ (1,0) [0|0] "" Vector__XXX
 SG_ VCFRONT_a514_packSOC m514 : 52|8@1+ (0.4,0) [0|0] "" Vector__XXX
 SG_ VCFRONT_a515_packSOC m515 : 52|8@1+ (0.4,0) [0|0] "" Vector__XXX
 SG_ VCFRONT_a559_transportMode m559 : 52|1@1+ (1,0) [0|0] "" Vector__XXX
 SG_ VCFRONT_a600_version m600 : 52|4@1+ (1,0) [0|0] "" Vector__XXX
 SG_ VCFRONT_a611_heatGenTotal m611 : 52|6@1+ (500,0) [0|0] "" Vector__XXX
 SG_ VCFRONT_a623_failureLvBatteryPowerActiveDecel m623 : 52|1@1+ (1,0) [0|0] "" Vector__XXX
 SG_ VCFRONT_a626_IBSTemperature m626 : 52|8@1+ (0.5,-30) [0|0] "" Vector__XXX
 SG_ VCFRONT_a627_sumCellVoltage m627 : 52|8@1+ (0.1,0) [0|0] "" Vector__XXX
 SG_ VCFRONT_a178_isInSilentMode m178 : 53|1@1+ (1,0) [0|0] "" Vector__XXX
 SG_ VCFRONT_a188_wakeUpMsgID m188 : 53|11@1+ (1,0) [0|0] "" Vector__XXX
 SG_ VCFRONT_a191_LVBMSMIA m191 : 53|1@1+ (1,0) [0|0] "" Vector__XXX
 SG_ VCFRONT_a260_PCS_MIA m260 : 53|1@1+ (1,0) [0|0] "" Vector__XXX
 SG_ VCFRONT_a359_BMS_MIA m359 : 53|1@1+ (1,0) [0|0] "" Vector__XXX
 SG_ VCFRONT_a405_intervalCurrentVariance m405 : 53|6@1+ (0.1,0) [0|0] "" Vector__XXX
 SG_ VCFRONT_a406_IBSTemperature m406 : 53|6@1+ (1,-3) [0|0] "" Vector__XXX
 SG_ VCFRONT_a408_standbyChargeProfileTime m408 : 53|10@1+ (1,0) [0|0] "" Vector__XXX
 SG_ VCFRONT_a428_modCacImbalancePct m428 : 53|10@1+ (0.1,0) [0|0] "" Vector__XXX
 SG_ VCFRONT_a446_batteryOverTemp m446 : 53|1@1+ (1,0) [0|0] "" Vector__XXX
 SG_ VCFRONT_a474_TPS92520_HSILIM m474 : 53|1@1+ (1,0) [0|0] "" Vector__XXX
 SG_ VCFRONT_a475_TPS92520_HSILIM m475 : 53|1@1+ (1,0) [0|0] "" Vector__XXX
 SG_ VCFRONT_a511_factoryGated m511 : 53|1@1+ (1,0) [0|0] "" Vector__XXX
 SG_ VCFRONT_a559_notEnoughPowerForSupport m559 : 53|1@1+ (1,0) [0|0] "" Vector__XXX
 SG_ VCFRONT_a561_cell4Voltage m561 : 53|7@1+ (0.04,0) [0|0] "" Vector__XXX
 SG_ VCFRONT_a562_cell4Voltage m562 : 53|7@1+ (0.04,0) [0|0] "" Vector__XXX
 SG_ VCFRONT_a623_failureLvBatteryCapabilityLowAccuracy m623 : 53|1@1+ (1,0) [0|0] "" Vector__XXX
 SG_ VCFRONT_a669_minPackTemperature m669 : 53|6@1+ (2,-40) [0|0] "" Vector__XXX
 SG_ VCFRONT_a178_isPsAvailable m178 : 54|1@1+ (1,0) [0|0] "" Vector__XXX
 SG_ VCFRONT_a184_recircDoorPercent m184 : 54|6@1+ (2,0) [0|0] "" Vector__XXX
 SG_ VCFRONT_a191_PCS_MIA m191 : 54|1@1+ (1,0) [0|0] "" Vector__XXX
 SG_ VCFRONT_a197_serviceMode m197 : 54|1@1+ (1,0) [0|0] "" Vector__XXX
 SG_ VCFRONT_a260_HVBlockingMismatch m260 : 54|1@1+ (1,0) [0|0] "" Vector__XXX
 SG_ VCFRONT_a359_PCS_MIA m359 : 54|1@1+ (1,0) [0|0] "" Vector__XXX
 SG_ VCFRONT_a414_IBSAmpHours m414 : 54|8@1+ (0.01,-2.55) [0|0] "" Vector__XXX
 SG_ VCFRONT_a415_vehiclePowerState m415 : 54|2@1+ (1,0) [0|0] "" Vector__XXX
 SG_ VCFRONT_a416_brickId m416 : 54|8@1+ (1,1) [0|0] "" Vector__XXX
 SG_ VCFRONT_a417_brickId m417 : 54|8@1+ (1,1) [0|0] "" Vector__XXX
 SG_ VCFRONT_a418_brickId m418 : 54|8@1+ (1,1) [0|0] "" Vector__XXX
 SG_ VCFRONT_a419_brickId m419 : 54|8@1+ (1,1) [0|0] "" Vector__XXX
 SG_ VCFRONT_a423_brickId m423 : 54|8@1+ (1,1) [0|0] "" Vector__XXX
 SG_ VCFRONT_a424_brickId m424 : 54|8@1+ (1,1) [0|0] "" Vector__XXX
 SG_ VCFRONT_a446_hvacSystemFault m446 : 54|1@1+ (1,0) [0|0] "" Vector__XXX
 SG_ VCFRONT_a474_TPS92520_BSTUV m474 : 54|1@1+ (1,0) [0|0] "" Vector__XXX
 SG_ VCFRONT_a475_TPS92520_BSTUV m475 : 54|1@1+ (1,0) [0|0] "" Vector__XXX
 SG_ VCFRONT_a498_measuredVoltage m498 : 54|10@1+ (0.05,0) [0|0] "" Vector__XXX
 SG_ VCFRONT_a503_brickId m503 : 54|8@1+ (1,1) [0|0] "" Vector__XXX
 SG_ VCFRONT_a511_vehicleIsUpdating m511 : 54|1@1+ (1,0) [0|0] "" Vector__XXX
 SG_ VCFRONT_a559_crashDetected m559 : 54|1@1+ (1,0) [0|0] "" Vector__XXX
 SG_ VCFRONT_a606_battLPMAtExit m606 : 54|5@1+ (1,0) [0|0] "" Vector__XXX
 SG_ VCFRONT_a623_failureLvBatteryConfiguration m623 : 54|1@1+ (1,0) [0|0] "" Vector__XXX
 SG_ VCFRONT_a663_hcmlGroupsHighWaterMarkPercent_IC700 m663 : 54|5@1+ (3.225806451612903,0) [0|0] "" Vector__XXX
 SG_ VCFRONT_a664_hcmrGroupsHighWaterMarkPercent_IC700 m664 : 54|5@1+ (3.225806451612903,0) [0|0] "" Vector__XXX
 SG_ VCFRONT_a178_isPdAvailable m178 : 55|1@1+ (1,0) [0|0] "" Vector__XXX
 SG_ VCFRONT_a182_calibrationLostFault m182 : 55|1@1+ (1,0) [0|0] "" Vector__XXX
 SG_ VCFRONT_a183_calibrationLostFault m183 : 55|1@1+ (1,0) [0|0] "" Vector__XXX
 SG_ VCFRONT_a191_NotEnoughPowerForSupport m191 : 55|1@1+ (1,0) [0|0] "" Vector__XXX
 SG_ VCFRONT_a197_frunkOpen m197 : 55|1@1+ (1,0) [0|0] "" Vector__XXX
 SG_ VCFRONT_a253_firstChargeOTA m253 : 55|1@1+ (1,0) [0|0] "" Vector__XXX
 SG_ VCFRONT_a260_serviceMode m260 : 55|1@1+ (1,0) [0|0] "" Vector__XXX
 SG_ VCFRONT_a359_serviceMode m359 : 55|1@1+ (1,0) [0|0] "" Vector__XXX
 SG_ VCFRONT_a446_coolantSysLockedOut m446 : 55|1@1+ (1,0) [0|0] "" Vector__XXX
 SG_ VCFRONT_a474_BoostRailStatus m474 : 55|1@1+ (1,0) [0|0] "" Vector__XXX
 SG_ VCFRONT_a475_BoostRailStatus m475 : 55|1@1+ (1,0) [0|0] "" Vector__XXX
 SG_ VCFRONT_a511_serviceMode m511 : 55|1@1+ (1,0) [0|0] "" Vector__XXX
 SG_ VCFRONT_a559_BMS_MIA m559 : 55|1@1+ (1,0) [0|0] "" Vector__XXX
 SG_ VCFRONT_a623_failureLvBatteryHighImpedance m623 : 55|1@1+ (1,0) [0|0] "" Vector__XXX
 SG_ VCFRONT_a009_LCCInletCoolantAtExit m9 : 56|6@1- (1,12) [0|0] "" Vector__XXX
 SG_ VCFRONT_a022_TaskInitError4 m22 : 56|8@1+ (1,0) [0|0] "" Vector__XXX
 SG_ VCFRONT_a031_uds_bytes_5 m31 : 56|8@1+ (1,0) [0|0] "" Vector__XXX
 SG_ VCFRONT_a041_CPULoadNVMMTask m41 : 56|8@1+ (1,0) [0|0] "" Vector__XXX
 SG_ VCFRONT_a042_UsageNVMMTask m42 : 56|8@1+ (1,0) [0|0] "" Vector__XXX
 SG_ VCFRONT_a047_CsvRef m47 : 56|1@1+ (1,0) [0|0] "" Vector__XXX
 SG_ VCFRONT_a154_minVoltageAlignedDcrMilliOhms m154 : 56|8@1+ (1,0) [0|0] "" Vector__XXX
 SG_ VCFRONT_a155_minCurrentAlignedDcrMilliOhms m155 : 56|8@1+ (1,0) [0|0] "" Vector__XXX
 SG_ VCFRONT_a178_isAmbientAvailable m178 : 56|1@1+ (1,0) [0|0] "" Vector__XXX
 SG_ VCFRONT_a180_targetPCSVoltage m180 : 56|8@1+ (0.1,0) [0|0] "" Vector__XXX
 SG_ VCFRONT_a182_samplingHWError m182 : 56|1@1+ (1,0) [0|0] "" Vector__XXX
 SG_ VCFRONT_a183_samplingHWError m183 : 56|1@1+ (1,0) [0|0] "" Vector__XXX
 SG_ VCFRONT_a191_bmsState m191 : 56|4@1+ (1,0) [0|0] "" Vector__XXX
 SG_ VCFRONT_a192_HVFaultLoadShedActive m192 : 56|1@1+ (1,0) [0|0] "" Vector__XXX
 SG_ VCFRONT_a196_ECPAState m196 : 56|2@1+ (1,0) [0|0] "" Vector__XXX
 SG_ VCFRONT_a197_dcrMilliOhmsFiltered m197 : 56|8@1+ (1,0) [0|0] "" Vector__XXX
 SG_ VCFRONT_a242_vehiclePowerState m242 : 56|2@1+ (1,0) [0|0] "" Vector__XXX
 SG_ VCFRONT_a253_firstChargePOR m253 : 56|1@1+ (1,0) [0|0] "" Vector__XXX
 SG_ VCFRONT_a260_dcdcLVSupportStatus m260 : 56|2@1+ (1,0) [0|0] "" Vector__XXX
 SG_ VCFRONT_a269_vehiclePowerState m269 : 56|2@1+ (1,0) [0|0] "" Vector__XXX
 SG_ VCFRONT_a359_dcdcLVSupportStatus m359 : 56|2@1+ (1,0) [0|0] "" Vector__XXX
 SG_ VCFRONT_a363_minBleedChargeBrickId m363 : 56|5@1+ (1,1) [0|0] "" Vector__XXX
 SG_ VCFRONT_a379_testFailed m379 : 56|1@1+ (1,0) [0|0] "" Vector__XXX
 SG_ VCFRONT_a412_pulseCurrentVarianceShifted m412 : 56|6@1+ (0.25,0) [0|0] "" Vector__XXX
 SG_ VCFRONT_a415_HV_UP m415 : 56|1@1+ (1,0) [0|0] "" Vector__XXX
 SG_ VCFRONT_a421_hcmlReadBufferHighWaterMarkPercent m421 : 56|5@1+ (3.225806451612903,0) [0|0] "" Vector__XXX
 SG_ VCFRONT_a427_cacUpdateError m427 : 56|8@1+ (0.1,0) [0|0] "" Vector__XXX
 SG_ VCFRONT_a429_testType m429 : 56|1@1+ (1,0) [0|0] "" Vector__XXX
 SG_ VCFRONT_a446_refSysLockedOut m446 : 56|1@1+ (1,0) [0|0] "" Vector__XXX
 SG_ VCFRONT_a474_EEPROM_DataStatus m474 : 56|1@1+ (1,0) [0|0] "" Vector__XXX
 SG_ VCFRONT_a475_EEPROM_DataStatus m475 : 56|1@1+ (1,0) [0|0] "" Vector__XXX
 SG_ VCFRONT_a482_previousAimedPositionValid m482 : 56|1@1+ (1,0) [0|0] "" Vector__XXX
 SG_ VCFRONT_a484_leftHeadlampMigrationState m484 : 56|2@1+ (1,0) [0|0] "" Vector__XXX
 SG_ VCFRONT_a485_previousAimedPositionValid m485 : 56|1@1+ (1,0) [0|0] "" Vector__XXX
 SG_ VCFRONT_a493_avgBrickSoc m493 : 56|7@1+ (1,0) [0|0] "" Vector__XXX
 SG_ VCFRONT_a497_frunkOpen m497 : 56|1@1+ (1,0) [0|0] "" Vector__XXX
 SG_ VCFRONT_a511_frunkOpen m511 : 56|1@1+ (1,0) [0|0] "" Vector__XXX
 SG_ VCFRONT_a523_control3Byte3 m523 : 56|8@1+ (1,0) [0|0] "" Vector__XXX
 SG_ VCFRONT_a527_serviceMode m527 : 56|1@1+ (1,0) [0|0] "" Vector__XXX
 SG_ VCFRONT_a541_SOC m541 : 56|7@1+ (1,0) [0|0] "" Vector__XXX
 SG_ VCFRONT_a542_inFactoryMode m542 : 56|1@1+ (1,0) [0|0] "" Vector__XXX
 SG_ VCFRONT_a548_ampHourBucketFilled m548 : 56|1@1+ (1,0) [0|0] "" Vector__XXX
 SG_ VCFRONT_a559_PCS_MIA m559 : 56|1@1+ (1,0) [0|0] "" Vector__XXX
 SG_ VCFRONT_a585_inFactoryMode m585 : 56|1@1+ (1,0) [0|0] "" Vector__XXX
 SG_ VCFRONT_a623_failureLvBatteryExtendedOverVoltage m623 : 56|1@1+ (1,0) [0|0] "" Vector__XXX
 SG_ VCFRONT_a643_hcmrReadBufferHighWaterMarkPercent m643 : 56|5@1+ (3.225806451612903,0) [0|0] "" Vector__XXX
 SG_ VCFRONT_a646_fluidSuccessPercent m646 : 56|8@1+ (1,0) [0|0] "" Vector__XXX
 SG_ VCFRONT_a047_uds m47 : 57|1@1+ (1,0) [0|0] "" Vector__XXX
 SG_ VCFRONT_a162_recircExvFlow m162 : 57|7@1+ (1,0) [0|0] "" Vector__XXX
 SG_ VCFRONT_a178_hpMode m178 : 57|5@1+ (1,0) [0|0] "" Vector__XXX
 SG_ VCFRONT_a182_brickOverDischarged m182 : 57|1@1+ (1,0) [0|0] "" Vector__XXX
 SG_ VCFRONT_a183_brickOverDischarged m183 : 57|1@1+ (1,0) [0|0] "" Vector__XXX
 SG_ VCFRONT_a192_postCrashLoadShedActive m192 : 57|1@1+ (1,0) [0|0] "" Vector__XXX
 SG_ VCFRONT_a253_serviceMode m253 : 57|1@1+ (1,0) [0|0] "" Vector__XXX
 SG_ VCFRONT_a379_testCompleted m379 : 57|1@1+ (1,0) [0|0] "" Vector__XXX
 SG_ VCFRONT_a415_hvUpFirstTrigger m415 : 57|1@1+ (1,0) [0|0] "" Vector__XXX
 SG_ VCFRONT_a429_totalDuration m429 : 57|6@1+ (1,-1) [0|0] "" Vector__XXX
 SG_ VCFRONT_a446_chillerEXVNotReady m446 : 57|1@1+ (1,0) [0|0] "" Vector__XXX
 SG_ VCFRONT_a474_LMMVariant m474 : 57|2@1+ (1,0) [0|0] "" Vector__XXX
 SG_ VCFRONT_a475_LMMVariant m475 : 57|2@1+ (1,0) [0|0] "" Vector__XXX
 SG_ VCFRONT_a482_rangeValid m482 : 57|1@1+ (1,0) [0|0] "" Vector__XXX
 SG_ VCFRONT_a485_rangeValid m485 : 57|1@1+ (1,0) [0|0] "" Vector__XXX
 SG_ VCFRONT_a527_frunkOpen m527 : 57|1@1+ (1,0) [0|0] "" Vector__XXX
 SG_ VCFRONT_a542_inServiceMode m542 : 57|1@1+ (1,0) [0|0] "" Vector__XXX
 SG_ VCFRONT_a548_HVNotConfirmedUpTrigger m548 : 57|1@1+ (1,0) [0|0] "" Vector__XXX
 SG_ VCFRONT_a559_HVBlockingMismatch m559 : 57|1@1+ (1,0) [0|0] "" Vector__XXX
 SG_ VCFRONT_a585_inServiceMode m585 : 57|1@1+ (1,0) [0|0] "" Vector__XXX
 SG_ VCFRONT_a623_factoryMode m623 : 57|1@1+ (1,0) [0|0] "" Vector__XXX
 SG_ VCFRONT_a047_SingleCoreM4_M7_0 m47 : 58|1@1+ (1,0) [0|0] "" Vector__XXX
 SG_ VCFRONT_a182_impedanceGrowth m182 : 58|1@1+ (1,0) [0|0] "" Vector__XXX
 SG_ VCFRONT_a183_impedanceGrowth m183 : 58|1@1+ (1,0) [0|0] "" Vector__XXX
 SG_ VCFRONT_a253_frunkOpen m253 : 58|1@1+ (1,0) [0|0] "" Vector__XXX
 SG_ VCFRONT_a260_PCSAndVCREFuseStable m260 : 58|1@1+ (1,0) [0|0] "" Vector__XXX
 SG_ VCFRONT_a359_bmsState m359 : 58|4@1+ (1,0) [0|0] "" Vector__XXX
 SG_ VCFRONT_a379_maxCurrentReached m379 : 58|6@1+ (1,-63) [0|0] "" Vector__XXX
 SG_ VCFRONT_a415_hvUpAnyTrigger m415 : 58|1@1+ (1,0) [0|0] "" Vector__XXX
 SG_ VCFRONT_a446_CCLEXVNotReady m446 : 58|1@1+ (1,0) [0|0] "" Vector__XXX
 SG_ VCFRONT_a481_currentSenseFinished m481 : 58|1@1+ (1,0) [0|0] "" Vector__XXX
 SG_ VCFRONT_a484_rightHeadlampMigrationState m484 : 58|2@1+ (1,0) [0|0] "" Vector__XXX
 SG_ VCFRONT_a513_serviceMode m513 : 58|1@1+ (1,0) [0|0] "" Vector__XXX
 SG_ VCFRONT_a542_isCommissioned m542 : 58|1@1+ (1,0) [0|0] "" Vector__XXX
 SG_ VCFRONT_a548_PCSNotMeetingTargetTrigger m548 : 58|1@1+ (1,0) [0|0] "" Vector__XXX
 SG_ VCFRONT_a559_HV_UP m559 : 58|1@1+ (1,0) [0|0] "" Vector__XXX
 SG_ VCFRONT_a585_inTransportMode m585 : 58|1@1+ (1,0) [0|0] "" Vector__XXX
 SG_ VCFRONT_a611_radCoolantToAirUAEst m611 : 58|6@1+ (20,0) [0|0] "" Vector__XXX
 SG_ VCFRONT_a623_serviceMode m623 : 58|1@1+ (1,0) [0|0] "" Vector__XXX
 SG_ VCFRONT_a047_SingleCoreM7_1 m47 : 59|1@1+ (1,0) [0|0] "" Vector__XXX
 SG_ VCFRONT_a127_vcleftEFuseRemainingRetries m127 : 59|4@1+ (1,0) [0|0] "" Vector__XXX
 SG_ VCFRONT_a128_vcrightEFuseRemainingRetries m128 : 59|4@1+ (1,0) [0|0] "" Vector__XXX
 SG_ VCFRONT_a129_pcsEFuseRemainingRetries m129 : 59|4@1+ (1,0) [0|0] "" Vector__XXX
 SG_ VCFRONT_a134_vbatFusedEFuseRemainingRetries m134 : 59|4@1+ (1,0) [0|0] "" Vector__XXX
 SG_ VCFRONT_a182_batteryType m182 : 59|3@1+ (1,0) [0|0] "" Vector__XXX
 SG_ VCFRONT_a183_batteryType m183 : 59|3@1+ (1,0) [0|0] "" Vector__XXX
 SG_ VCFRONT_a260_bmsState m260 : 59|4@1+ (1,0) [0|0] "" Vector__XXX
 SG_ VCFRONT_a405_testCounter m405 : 59|2@1+ (1,0) [0|0] "" Vector__XXX
 SG_ VCFRONT_a406_testValid m406 : 59|1@1+ (1,0) [0|0] "" Vector__XXX
 SG_ VCFRONT_a415_pcsEFuseUnstable m415 : 59|1@1+ (1,0) [0|0] "" Vector__XXX
 SG_ VCFRONT_a446_CCREXVNotReady m446 : 59|1@1+ (1,0) [0|0] "" Vector__XXX
 SG_ VCFRONT_a474_headlampECURevision m474 : 59|4@1+ (1,0) [0|0] "" Vector__XXX
 SG_ VCFRONT_a475_headlampECURevision m475 : 59|4@1+ (1,0) [0|0] "" Vector__XXX
 SG_ VCFRONT_a481_currentSenseFailure m481 : 59|1@1+ (1,0) [0|0] "" Vector__XXX
 SG_ VCFRONT_a513_frunkOpen m513 : 59|1@1+ (1,0) [0|0] "" Vector__XXX
 SG_ VCFRONT_a518_serviceMode m518 : 59|1@1+ (1,0) [0|0] "" Vector__XXX
 SG_ VCFRONT_a548_PCSMIATrigger m548 : 59|1@1+ (1,0) [0|0] "" Vector__XXX
 SG_ VCFRONT_a559_pcsEFuseStable m559 : 59|1@1+ (1,0) [0|0] "" Vector__XXX
 SG_ VCFRONT_a585_uiMia m585 : 59|1@1+ (1,0) [0|0] "" Vector__XXX
 SG_ VCFRONT_a606_timeInMode m606 : 59|5@1+ (1,0) [0|0] "" Vector__XXX
 SG_ VCFRONT_a663_hcmlValidatedGroupsHighWaterMarkPercent_IC700 m663 : 59|5@1+ (3.225806451612903,0) [0|0] "" Vector__XXX
 SG_ VCFRONT_a664_hcmrValidatedGroupsHighWaterMarkPercent_IC700 m664 : 59|5@1+ (3.225806451612903,0) [0|0] "" Vector__XXX
 SG_ VCFRONT_a669_ambientTempFiltered m669 : 59|5@1+ (3,-40) [0|0] "" Vector__XXX
 SG_ VCFRONT_a047_SingleCoreFailed m47 : 60|1@1+ (1,0) [0|0] "" Vector__XXX
 SG_ VCFRONT_a184_systemAbnormal m184 : 60|1@1+ (1,0) [0|0] "" Vector__XXX
 SG_ VCFRONT_a258_lowCapacity m258 : 60|1@1+ (1,0) [0|0] "" Vector__XXX
 SG_ VCFRONT_a406_opportunisticTest m406 : 60|1@1+ (1,0) [0|0] "" Vector__XXX
 SG_ VCFRONT_a407_testCounter m407 : 60|2@1+ (1,0) [0|0] "" Vector__XXX
 SG_ VCFRONT_a415_vcrightEfuseUnstable m415 : 60|1@1+ (1,0) [0|0] "" Vector__XXX
 SG_ VCFRONT_a446_LCCEXVNotReady m446 : 60|1@1+ (1,0) [0|0] "" Vector__XXX
 SG_ VCFRONT_a477_deepDischargeFlag m477 : 60|1@1+ (1,0) [0|0] "" Vector__XXX
 SG_ VCFRONT_a513_vehiclePowerState m513 : 60|2@1+ (1,0) [0|0] "" Vector__XXX
 SG_ VCFRONT_a514_serviceMode m514 : 60|1@1+ (1,0) [0|0] "" Vector__XXX
 SG_ VCFRONT_a515_serviceMode m515 : 60|1@1+ (1,0) [0|0] "" Vector__XXX
 SG_ VCFRONT_a518_frunkOpen m518 : 60|1@1+ (1,0) [0|0] "" Vector__XXX
 SG_ VCFRONT_a548_PCSSaturatedTrigger m548 : 60|1@1+ (1,0) [0|0] "" Vector__XXX
 SG_ VCFRONT_a559_vcrightEFuseStable m559 : 60|1@1+ (1,0) [0|0] "" Vector__XXX
 SG_ VCFRONT_a561_factoryMode m561 : 60|1@1+ (1,0) [0|0] "" Vector__XXX
 SG_ VCFRONT_a562_factoryMode m562 : 60|1@1+ (1,0) [0|0] "" Vector__XXX
 SG_ VCFRONT_a585_frunkOpen m585 : 60|1@1+ (1,0) [0|0] "" Vector__XXX
 SG_ VCFRONT_a594_fusionSessionSampleCount m594 : 60|4@1+ (16,0) [0|0] "" Vector__XXX
 SG_ VCFRONT_a626_testCounter m626 : 60|2@1+ (1,0) [0|0] "" Vector__XXX
 SG_ VCFRONT_a627_deepDischargeFlag m627 : 60|1@1+ (1,0) [0|0] "" Vector__XXX
 SG_ VCFRONT_a047_IpcWatchdog m47 : 61|1@1+ (1,0) [0|0] "" Vector__XXX
 SG_ VCFRONT_a258_completed m258 : 61|1@1+ (1,0) [0|0] "" Vector__XXX
 SG_ VCFRONT_a363_setFromNvm m363 : 61|1@1+ (1,0) [0|0] "" Vector__XXX
 SG_ VCFRONT_a405_overchargeTrigger m405 : 61|1@1+ (1,0) [0|0] "" Vector__XXX
 SG_ VCFRONT_a406_disconnectedBatteryTestTrigger m406 : 61|1@1+ (1,0) [0|0] "" Vector__XXX
 SG_ VCFRONT_a415_vcleftEfuseUnstable m415 : 61|1@1+ (1,0) [0|0] "" Vector__XXX
 SG_ VCFRONT_a446_evapEXVNotReady m446 : 61|1@1+ (1,0) [0|0] "" Vector__XXX
 SG_ VCFRONT_a477_serviceMode m477 : 61|1@1+ (1,0) [0|0] "" Vector__XXX
 SG_ VCFRONT_a514_frunkOpen m514 : 61|1@1+ (1,0) [0|0] "" Vector__XXX
 SG_ VCFRONT_a515_frunkOpen m515 : 61|1@1+ (1,0) [0|0] "" Vector__XXX
 SG_ VCFRONT_a518_vehiclePowerState m518 : 61|2@1+ (1,0) [0|0] "" Vector__XXX
 SG_ VCFRONT_a548_backstopHit m548 : 61|1@1+ (1,0) [0|0] "" Vector__XXX
 SG_ VCFRONT_a559_contactorEFuseStable m559 : 61|1@1+ (1,0) [0|0] "" Vector__XXX
 SG_ VCFRONT_a561_serviceMode m561 : 61|1@1+ (1,0) [0|0] "" Vector__XXX
 SG_ VCFRONT_a562_serviceMode m562 : 61|1@1+ (1,0) [0|0] "" Vector__XXX
 SG_ VCFRONT_a585_leftRailVoltageLow m585 : 61|1@1+ (1,0) [0|0] "" Vector__XXX
 SG_ VCFRONT_a627_serviceMode m627 : 61|1@1+ (1,0) [0|0] "" Vector__XXX
 SG_ VCFRONT_a178_runDueToHpCommissioning m178 : 62|1@1+ (1,0) [0|0] "" Vector__XXX
 SG_ VCFRONT_a182_bleedFetTestFailure m182 : 62|1@1+ (1,0) [0|0] "" Vector__XXX
 SG_ VCFRONT_a183_bleedFetTestFailure m183 : 62|1@1+ (1,0) [0|0] "" Vector__XXX
 SG_ VCFRONT_a403_firstChargeOTA m403 : 62|1@1+ (1,0) [0|0] "" Vector__XXX
 SG_ VCFRONT_a405_voltDropOnHighCurrentTrigger m405 : 62|1@1+ (1,0) [0|0] "" Vector__XXX
 SG_ VCFRONT_a406_maxChargeTimeoutTrigger m406 : 62|1@1+ (1,0) [0|0] "" Vector__XXX
 SG_ VCFRONT_a407_testingExpended m407 : 62|1@1+ (1,0) [0|0] "" Vector__XXX
 SG_ VCFRONT_a412_serviceMode m412 : 62|1@1+ (1,0) [0|0] "" Vector__XXX
 SG_ VCFRONT_a414_vehiclePowerState m414 : 62|2@1+ (1,0) [0|0] "" Vector__XXX
 SG_ VCFRONT_a415_contactorEFuseUnstable m415 : 62|1@1+ (1,0) [0|0] "" Vector__XXX
 SG_ VCFRONT_a446_recircEXVNotReady m446 : 62|1@1+ (1,0) [0|0] "" Vector__XXX
 SG_ VCFRONT_a477_frunkOpen m477 : 62|1@1+ (1,0) [0|0] "" Vector__XXX
 SG_ VCFRONT_a514_vehiclePowerState m514 : 62|2@1+ (1,0) [0|0] "" Vector__XXX
 SG_ VCFRONT_a515_vehiclePowerState m515 : 62|2@1+ (1,0) [0|0] "" Vector__XXX
 SG_ VCFRONT_a559_hvcEFuseStable m559 : 62|1@1+ (1,0) [0|0] "" Vector__XXX
 SG_ VCFRONT_a561_frunkOpen m561 : 62|1@1+ (1,0) [0|0] "" Vector__XXX
 SG_ VCFRONT_a562_frunkOpen m562 : 62|1@1+ (1,0) [0|0] "" Vector__XXX
 SG_ VCFRONT_a585_rightRailVoltageLow m585 : 62|1@1+ (1,0) [0|0] "" Vector__XXX
 SG_ VCFRONT_a626_testingExpended m626 : 62|1@1+ (1,0) [0|0] "" Vector__XXX
 SG_ VCFRONT_a627_frunkOpen m627 : 62|1@1+ (1,0) [0|0] "" Vector__XXX
 SG_ VCFRONT_a058_faultReason m58 : 63|1@1+ (1,0) [0|0] "" Vector__XXX
 SG_ VCFRONT_a172_serviceMode m172 : 63|1@1+ (1,0) [0|0] "" Vector__XXX
 SG_ VCFRONT_a173_serviceMode m173 : 63|1@1+ (1,0) [0|0] "" Vector__XXX
 SG_ VCFRONT_a182_weakShort m182 : 63|1@1+ (1,0) [0|0] "" Vector__XXX
 SG_ VCFRONT_a183_weakShort m183 : 63|1@1+ (1,0) [0|0] "" Vector__XXX
 SG_ VCFRONT_a403_IBSTempShortOrOpen m403 : 63|1@1+ (1,0) [0|0] "" Vector__XXX
 SG_ VCFRONT_a405_voltageDipTrigger m405 : 63|1@1+ (1,0) [0|0] "" Vector__XXX
 SG_ VCFRONT_a406_voltageFloorReachedTrigger m406 : 63|1@1+ (1,0) [0|0] "" Vector__XXX
 SG_ VCFRONT_a407_opportunisticTest m407 : 63|1@1+ (1,0) [0|0] "" Vector__XXX
 SG_ VCFRONT_a408_IBSTempShortOrOpen m408 : 63|1@1+ (1,0) [0|0] "" Vector__XXX
 SG_ VCFRONT_a412_frunkOpen m412 : 63|1@1+ (1,0) [0|0] "" Vector__XXX
 SG_ VCFRONT_a415_hvcEFuseUnstable m415 : 63|1@1+ (1,0) [0|0] "" Vector__XXX
 SG_ VCFRONT_a446_checkA447Alert m446 : 63|1@1+ (1,0) [0|0] "" Vector__XXX
 SG_ VCFRONT_a559_frunkOpen m559 : 63|1@1+ (1,0) [0|0] "" Vector__XXX
 SG_ VCFRONT_a626_opportunisticTest m626 : 63|1@1+ (1,0) [0|0] "" Vector__XXX

BO_ 1334 FC_evseBilling2: 8 Vector__XXX
 SG_ FC_evseBilling2DataSelect M : 0|4@1+ (1,0) [0|0] "" Vector__XXX
 SG_ FC_evsePpuEnabled m0 : 4|1@1+ (1,0) [0|0] "" Vector__XXX
 SG_ FC_evseBillingEnergyHighRes m0 : 8|24@1+ (0.0001,0) [0|0] "" Vector__XXX

BO_ 1335 VCFRONT1_alertLog: 8 Vector__XXX
 SG_ VCFRONT1_alertID M : 0|10@1+ (1,0) [0|0] "" Vector__XXX
 SG_ VCFRONT1_alertState : 15|1@1+ (1,0) [0|0] "" Vector__XXX
 SG_ VCFRONT1_a001_InternalWatchdog m1 : 16|1@1+ (1,0) [0|0] "" Vector__XXX
 SG_ VCFRONT1_a002_CPUUndervoltage m2 : 16|1@1+ (1,0) [0|0] "" Vector__XXX
 SG_ VCFRONT1_a003_AssertID m3 : 16|16@1+ (1,0) [0|0] "" Vector__XXX
 SG_ VCFRONT1_a005_busID0 m5 : 16|4@1+ (1,0) [0|0] "" Vector__XXX
 SG_ VCFRONT1_a006_busID m6 : 16|4@1+ (1,0) [0|0] "" Vector__XXX
 SG_ VCFRONT1_a012_ClockError m12 : 16|1@1+ (1,0) [0|0] "" Vector__XXX
 SG_ VCFRONT1_a013_LogQueueFull m13 : 16|1@1+ (1,0) [0|0] "" Vector__XXX
 SG_ VCFRONT1_a015_NVMMMemOverflow m15 : 16|1@1+ (1,0) [0|0] "" Vector__XXX
 SG_ VCFRONT1_a016_NVMMRecordID m16 : 16|16@1+ (1,0) [0|0] "" Vector__XXX
 SG_ VCFRONT1_a017_NVMMLifetimeEraseCycles m17 : 16|32@1+ (1,0) [0|0] "" Vector__XXX
 SG_ VCFRONT1_a018_DEBUGEVT m18 : 16|1@1+ (1,0) [0|0] "" Vector__XXX
 SG_ VCFRONT1_a019_BFARVALID m19 : 16|1@1+ (1,0) [0|0] "" Vector__XXX
 SG_ VCFRONT1_a021_Task1msLate m21 : 16|1@1+ (1,0) [0|0] "" Vector__XXX
 SG_ VCFRONT1_a022_TaskInitErrorCount m22 : 16|8@1+ (1,0) [0|0] "" Vector__XXX
 SG_ VCFRONT1_a028_DivideByZero m28 : 16|1@1+ (1,0) [0|0] "" Vector__XXX
 SG_ VCFRONT1_a030_logId m30 : 16|4@1+ (1,0) [0|0] "" Vector__XXX
 SG_ VCFRONT1_a031_uds_bytes_0 m31 : 16|8@1+ (1,0) [0|0] "" Vector__XXX
 SG_ VCFRONT1_a036_ipsr m36 : 16|8@1+ (1,0) [0|0] "" Vector__XXX
 SG_ VCFRONT1_a037_MMFARVALID m37 : 16|1@1+ (1,0) [0|0] "" Vector__XXX
 SG_ VCFRONT1_a038_faultType m38 : 16|2@1+ (1,0) [0|0] "" Vector__XXX
 SG_ VCFRONT1_a039_faultType m39 : 16|2@1+ (1,0) [0|0] "" Vector__XXX
 SG_ VCFRONT1_a040_depth m40 : 16|4@1+ (1,0) [0|0] "" Vector__XXX
 SG_ VCFRONT1_a041_CPULoadTotal m41 : 16|8@1+ (1,0) [0|0] "" Vector__XXX
 SG_ VCFRONT1_a042_Usage1msTask m42 : 16|8@1+ (1,0) [0|0] "" Vector__XXX
 SG_ VCFRONT1_a043_CallTrace0 m43 : 16|24@1+ (1,0) [0|0] "" Vector__XXX
 SG_ VCFRONT1_a044_CallTrace0 m44 : 16|24@1+ (1,0) [0|0] "" Vector__XXX
 SG_ VCFRONT1_a045_CallTrace0 m45 : 16|24@1+ (1,0) [0|0] "" Vector__XXX
 SG_ VCFRONT1_a046_CallTrace0 m46 : 16|24@1+ (1,0) [0|0] "" Vector__XXX
 SG_ VCFRONT1_a058_voltageDrop m58 : 16|12@1+ (0.005443676098,0) [0|0] "" Vector__XXX
 SG_ VCFRONT1_a059_voltageDrop m59 : 16|12@1+ (0.005443676098,0) [0|0] "" Vector__XXX
 SG_ VCFRONT1_a060_lockoutDisabled m60 : 16|1@1+ (1,0) [0|0] "" Vector__XXX
 SG_ VCFRONT1_a063_switchChannel m63 : 16|8@1+ (1,0) [0|0] "" Vector__XXX
 SG_ VCFRONT1_a064_busBitField m64 : 16|8@1+ (1,0) [0|0] "" Vector__XXX
 SG_ VCFRONT1_a077_BATTIPC_battIpcData0 m77 : 16|1@1+ (1,0) [0|0] "" Vector__XXX
 SG_ VCFRONT1_a078_FRONTIPC_frontprivData0 m78 : 16|1@1+ (1,0) [0|0] "" Vector__XXX
 SG_ VCFRONT1_a079_FRONTIPC_frontprivData0 m79 : 16|1@1+ (1,0) [0|0] "" Vector__XXX
 SG_ VCFRONT1_a080_FRONTIPC_frontIpcData0 m80 : 16|1@1+ (1,0) [0|0] "" Vector__XXX
 SG_ VCFRONT1_a081_FRONTIPC_vehNm m81 : 16|1@1+ (1,0) [0|0] "" Vector__XXX
 SG_ VCFRONT1_a082_FRONTIPC_frontprivData0 m82 : 16|1@1+ (1,0) [0|0] "" Vector__XXX
 SG_ VCFRONT1_a086_FRONTIPC_vehNm m86 : 16|1@1+ (1,0) [0|0] "" Vector__XXX
 SG_ VCFRONT1_a090_FRONTIPC_chNm m90 : 16|1@1+ (1,0) [0|0] "" Vector__XXX
 SG_ VCFRONT1_a091_FRONTIPC_faultsAndExtras m91 : 16|1@1+ (1,0) [0|0] "" Vector__XXX
 SG_ VCFRONT1_a096_FRONTIPC_status m96 : 16|1@1+ (1,0) [0|0] "" Vector__XXX
 SG_ VCFRONT1_a098_FRONTIPC_temperature m98 : 16|1@1+ (1,0) [0|0] "" Vector__XXX
 SG_ VCFRONT1_a100_BATTIPC m100 : 16|1@1+ (1,0) [0|0] "" Vector__XXX
 SG_ VCFRONT1_a103_FRONTIPC_hvsNm m103 : 16|1@1+ (1,0) [0|0] "" Vector__XXX
 SG_ VCFRONT1_a104_FRONTIPC_chNm m104 : 16|1@1+ (1,0) [0|0] "" Vector__XXX
 SG_ VCFRONT1_a105_FRONTIPC_chNm m105 : 16|1@1+ (1,0) [0|0] "" Vector__XXX
 SG_ VCFRONT1_a106_BATTIPC_dcdcRailStatus m106 : 16|1@1+ (1,0) [0|0] "" Vector__XXX
 SG_ VCFRONT1_a107_FRONTIPC_vehNm m107 : 16|1@1+ (1,0) [0|0] "" Vector__XXX
 SG_ VCFRONT1_a108_FRONTIPC_status m108 : 16|1@1+ (1,0) [0|0] "" Vector__XXX
 SG_ VCFRONT1_a110_BATTIPC_carConfig m110 : 16|1@1+ (1,0) [0|0] "" Vector__XXX
 SG_ VCFRONT1_a111_FRONTIPC_vehNm m111 : 16|1@1+ (1,0) [0|0] "" Vector__XXX
 SG_ VCFRONT1_a112_FRONTIPC_vehNm m112 : 16|1@1+ (1,0) [0|0] "" Vector__XXX
 SG_ VCFRONT1_a113_FRONTIPC_ethNm m113 : 16|1@1+ (1,0) [0|0] "" Vector__XXX
 SG_ VCFRONT1_a114_BATTIPC_wheelRotation m114 : 16|1@1+ (1,0) [0|0] "" Vector__XXX
 SG_ VCFRONT1_a115_FRONTIPC_vehNm m115 : 16|1@1+ (1,0) [0|0] "" Vector__XXX
 SG_ VCFRONT1_a116_FRONTIPC_vehNm m116 : 16|1@1+ (1,0) [0|0] "" Vector__XXX
 SG_ VCFRONT1_a117_FRONTIPC_vehNm m117 : 16|1@1+ (1,0) [0|0] "" Vector__XXX
 SG_ VCFRONT1_a118_FRONTIPC_vehNm m118 : 16|1@1+ (1,0) [0|0] "" Vector__XXX
 SG_ VCFRONT1_a119_FRONTIPC_leftStalk m119 : 16|1@1+ (1,0) [0|0] "" Vector__XXX
 SG_ VCFRONT1_a120_BATTIPC_speed m120 : 16|1@1+ (1,0) [0|0] "" Vector__XXX
 SG_ VCFRONT1_a122_FRONTIPC_status m122 : 16|1@1+ (1,0) [0|0] "" Vector__XXX
 SG_ VCFRONT1_a124_FRONTIPC_status m124 : 16|1@1+ (1,0) [0|0] "" Vector__XXX
 SG_ VCFRONT1_a125_FRONTIPC_leftStalk m125 : 16|1@1+ (1,0) [0|0] "" Vector__XXX
 SG_ VCFRONT1_a126_FRONTIPC_sysStatus m126 : 16|1@1+ (1,0) [0|0] "" Vector__XXX
 SG_ VCFRONT1_a127_iBoosterEFuseCurrent m127 : 16|16@1+ (0.1,0) [0|0] "" Vector__XXX
 SG_ VCFRONT1_a128_vcrightEFuseCurrent m128 : 16|16@1+ (0.1,0) [0|0] "" Vector__XXX
 SG_ VCFRONT1_a129_pcsEFuseCurrent m129 : 16|16@1+ (0.1,0) [0|0] "" Vector__XXX
 SG_ VCFRONT1_a130_autopilot2EFuseCurrent m130 : 16|16@1+ (0.1,0) [0|0] "" Vector__XXX
 SG_ VCFRONT1_a131_FRONTIPC_power m131 : 16|1@1+ (1,0) [0|0] "" Vector__XXX
 SG_ VCFRONT1_a132_epas2EFuseCurrent m132 : 16|16@1+ (0.1,0) [0|0] "" Vector__XXX
 SG_ VCFRONT1_a133_BATTIPC_primaryActuator m133 : 16|1@1+ (1,0) [0|0] "" Vector__XXX
 SG_ VCFRONT1_a134_hvContactorsEFuseCurrent m134 : 16|16@1+ (0.1,0) [0|0] "" Vector__XXX
 SG_ VCFRONT1_a135_leftHeadlightEFuseCurrent m135 : 16|16@1+ (0.1,0) [0|0] "" Vector__XXX
 SG_ VCFRONT1_a144_FRONTIPC_status m144 : 16|1@1+ (1,0) [0|0] "" Vector__XXX
 SG_ VCFRONT1_a164_lockoutVoltage m164 : 16|16@1+ (0.1,0) [0|0] "" Vector__XXX
 SG_ VCFRONT1_a165_lockoutVoltage m165 : 16|16@1+ (0.1,0) [0|0] "" Vector__XXX
 SG_ VCFRONT1_a177_mcuAudioEFuseCurrent m177 : 16|10@1+ (0.1,0) [0|0] "" Vector__XXX
 SG_ VCFRONT1_a188_LVBridgeState m188 : 16|4@1+ (1,0) [0|0] "" Vector__XXX
 SG_ VCFRONT1_a191_vehiclePowerState m191 : 16|2@1+ (1,0) [0|0] "" Vector__XXX
 SG_ VCFRONT1_a204_vbusVoltage m204 : 16|10@1+ (0.025,0) [0|0] "" Vector__XXX
 SG_ VCFRONT1_a205_busVoltage m205 : 16|10@1+ (0.025,0) [0|0] "" Vector__XXX
 SG_ VCFRONT1_a214_channel m214 : 16|1@1+ (1,0) [0|0] "" Vector__XXX
 SG_ VCFRONT1_a216_inDrive m216 : 16|1@1+ (1,0) [0|0] "" Vector__XXX
 SG_ VCFRONT1_a220_DI_gear m220 : 16|3@1+ (1,0) [0|0] "" Vector__XXX
 SG_ VCFRONT1_a223_failedArmingSetup m223 : 16|1@1+ (1,0) [0|0] "" Vector__XXX
 SG_ VCFRONT1_a229_bridgeOpened m229 : 16|1@1+ (1,0) [0|0] "" Vector__XXX
 SG_ VCFRONT1_a249_hardwareProtectionsArmed m249 : 16|1@1+ (1,0) [0|0] "" Vector__XXX
 SG_ VCFRONT1_a250_pcsOvShutdownFaultPinActive m250 : 16|1@1+ (1,0) [0|0] "" Vector__XXX
 SG_ VCFRONT1_a251_rationalitySetupCheckResult m251 : 16|2@1+ (1,0) [0|0] "" Vector__XXX
 SG_ VCFRONT1_a252_stage m252 : 16|3@1+ (1,0) [0|0] "" Vector__XXX
 SG_ VCFRONT1_a253_pcsOvClampArmed m253 : 16|1@1+ (1,0) [0|0] "" Vector__XXX
 SG_ VCFRONT1_a262_eFuseVoltage m262 : 16|16@1+ (0.1,0) [0|0] "" Vector__XXX
 SG_ VCFRONT1_a263_eFuseVoltage m263 : 16|16@1+ (0.1,0) [0|0] "" Vector__XXX
 SG_ VCFRONT1_a264_eFuseVoltage m264 : 16|16@1+ (0.1,0) [0|0] "" Vector__XXX
 SG_ VCFRONT1_a266_eFuseVoltage m266 : 16|16@1+ (0.1,0) [0|0] "" Vector__XXX
 SG_ VCFRONT1_a414_failureReason m414 : 16|6@1+ (1,0) [0|0] "" Vector__XXX
 SG_ VCFRONT1_a415_upstreamEFuseStuckOff m415 : 16|1@1+ (1,0) [0|0] "" Vector__XXX
 SG_ VCFRONT1_a423_allBusesSleeping m423 : 16|1@1+ (1,0) [0|0] "" Vector__XXX
 SG_ VCFRONT1_a475_channel m475 : 16|3@1+ (1,0) [0|0] "" Vector__XXX
 SG_ VCFRONT1_a482_lvBridgeEFuseCurrent m482 : 16|16@1+ (0.1,0) [0|0] "" Vector__XXX
 SG_ VCFRONT1_a484_upstreamEFuseStuckOn m484 : 16|1@1+ (1,0) [0|0] "" Vector__XXX
 SG_ VCFRONT1_a485_upstreamEfuseUnattemptedOn m485 : 16|1@1+ (1,0) [0|0] "" Vector__XXX
 SG_ VCFRONT1_a486_bridgeFailedArmingSetup m486 : 16|1@1+ (1,0) [0|0] "" Vector__XXX
 SG_ VCFRONT1_a489_channel m489 : 16|3@1+ (1,0) [0|0] "" Vector__XXX
 SG_ VCFRONT1_a490_channel m490 : 16|3@1+ (1,0) [0|0] "" Vector__XXX
 SG_ VCFRONT1_a491_channel m491 : 16|3@1+ (1,0) [0|0] "" Vector__XXX
 SG_ VCFRONT1_a496_serviceMode m496 : 16|1@1+ (1,0) [0|0] "" Vector__XXX
 SG_ VCFRONT1_a509_channel m509 : 16|3@1+ (1,0) [0|0] "" Vector__XXX
 SG_ VCFRONT1_a574_frontDriveInverterCurrent m574 : 16|16@1+ (0.1,0) [0|0] "" Vector__XXX
 SG_ VCFRONT1_a578_vbusFusedLoadShedCurrent m578 : 16|16@1+ (0.1,0) [0|0] "" Vector__XXX
 SG_ VCFRONT1_a581_channel m581 : 16|3@1+ (1,0) [0|0] "" Vector__XXX
 SG_ VCFRONT1_a590_vcrightEFuseCurveType m590 : 16|1@1+ (1,0) [0|0] "" Vector__XXX
 SG_ VCFRONT1_a591_vcrightEFuseFastBlowType m591 : 16|1@1+ (1,0) [0|0] "" Vector__XXX
 SG_ VCFRONT1_a596_vcrightCutoffEFuseCurveType m596 : 16|1@1+ (1,0) [0|0] "" Vector__XXX
 SG_ VCFRONT1_a597_vcrightCutoffEFuseFastBlowType m597 : 16|1@1+ (1,0) [0|0] "" Vector__XXX
 SG_ VCFRONT1_a617_FRONTIPC_APP_VC_infoMessage m617 : 16|1@1+ (1,0) [0|0] "" Vector__XXX
 SG_ VCFRONT1_a002_PowerOnReset m2 : 17|1@1+ (1,0) [0|0] "" Vector__XXX
 SG_ VCFRONT1_a012_FlashError m12 : 17|1@1+ (1,0) [0|0] "" Vector__XXX
 SG_ VCFRONT1_a013_ClearQueueFull m13 : 17|1@1+ (1,0) [0|0] "" Vector__XXX
 SG_ VCFRONT1_a015_NVMMFilesystemError m15 : 17|1@1+ (1,0) [0|0] "" Vector__XXX
 SG_ VCFRONT1_a018_FORCED m18 : 17|1@1+ (1,0) [0|0] "" Vector__XXX
 SG_ VCFRONT1_a019_LazyFPStateError m19 : 17|1@1+ (1,0) [0|0] "" Vector__XXX
 SG_ VCFRONT1_a021_Task1msStarved m21 : 17|1@1+ (1,0) [0|0] "" Vector__XXX
 SG_ VCFRONT1_a028_UnalignedAccess m28 : 17|1@1+ (1,0) [0|0] "" Vector__XXX
 SG_ VCFRONT1_a037_LazyFPStateError m37 : 17|1@1+ (1,0) [0|0] "" Vector__XXX
 SG_ VCFRONT1_a060_resetUnlocked m60 : 17|1@1+ (1,0) [0|0] "" Vector__XXX
 SG_ VCFRONT1_a077_FRONTIPC_frontprivData0 m77 : 17|1@1+ (1,0) [0|0] "" Vector__XXX
 SG_ VCFRONT1_a078_BATTIPC_frontprivData0 m78 : 17|1@1+ (1,0) [0|0] "" Vector__XXX
 SG_ VCFRONT1_a079_BATTIPC_battIpcData0 m79 : 17|1@1+ (1,0) [0|0] "" Vector__XXX
 SG_ VCFRONT1_a081_FRONTIPC_frontprivData0 m81 : 17|1@1+ (1,0) [0|0] "" Vector__XXX
 SG_ VCFRONT1_a082_FRONTIPC_frontIpcData0 m82 : 17|1@1+ (1,0) [0|0] "" Vector__XXX
 SG_ VCFRONT1_a086_BATTIPC_vehNm m86 : 17|1@1+ (1,0) [0|0] "" Vector__XXX
 SG_ VCFRONT1_a090_FRONTIPC_state m90 : 17|1@1+ (1,0) [0|0] "" Vector__XXX
 SG_ VCFRONT1_a091_FRONTIPC_state m91 : 17|1@1+ (1,0) [0|0] "" Vector__XXX
 SG_ VCFRONT1_a098_FRONTIPC_thermalControl m98 : 17|1@1+ (1,0) [0|0] "" Vector__XXX
 SG_ VCFRONT1_a100_FRONTIPC m100 : 17|1@1+ (1,0) [0|0] "" Vector__XXX
 SG_ VCFRONT1_a103_FRONTIPC_status m103 : 17|1@1+ (1,0) [0|0] "" Vector__XXX
 SG_ VCFRONT1_a104_FRONTIPC_bodyControls m104 : 17|1@1+ (1,0) [0|0] "" Vector__XXX
 SG_ VCFRONT1_a106_BATTIPC_dcdcStatus m106 : 17|1@1+ (1,0) [0|0] "" Vector__XXX
 SG_ VCFRONT1_a107_FRONTIPC_status m107 : 17|1@1+ (1,0) [0|0] "" Vector__XXX
 SG_ VCFRONT1_a108_FRONTIPC_temperature m108 : 17|1@1+ (1,0) [0|0] "" Vector__XXX
 SG_ VCFRONT1_a110_BATTIPC_carState m110 : 17|1@1+ (1,0) [0|0] "" Vector__XXX
 SG_ VCFRONT1_a111_FRONTIPC_status m111 : 17|1@1+ (1,0) [0|0] "" Vector__XXX
 SG_ VCFRONT1_a112_FRONTIPC_status m112 : 17|1@1+ (1,0) [0|0] "" Vector__XXX
 SG_ VCFRONT1_a113_FRONTIPC_powerRationalityConfig m113 : 17|1@1+ (1,0) [0|0] "" Vector__XXX
 SG_ VCFRONT1_a114_FRONTIPC_wheelRotation m114 : 17|1@1+ (1,0) [0|0] "" Vector__XXX
 SG_ VCFRONT1_a115_BATTIPC_requests m115 : 17|1@1+ (1,0) [0|0] "" Vector__XXX
 SG_ VCFRONT1_a116_FRONTIPC_hvacRequest m116 : 17|1@1+ (1,0) [0|0] "" Vector__XXX
 SG_ VCFRONT1_a117_FRONTIPC_switchStatus m117 : 17|1@1+ (1,0) [0|0] "" Vector__XXX
 SG_ VCFRONT1_a118_BATTIPC_vehNm m118 : 17|1@1+ (1,0) [0|0] "" Vector__XXX
 SG_ VCFRONT1_a120_FRONTIPC_speed m120 : 17|1@1+ (1,0) [0|0] "" Vector__XXX
 SG_ VCFRONT1_a122_FRONTIPC_nonLocalizedOccupancy m122 : 17|1@1+ (1,0) [0|0] "" Vector__XXX
 SG_ VCFRONT1_a124_BATTIPC_status m124 : 17|1@1+ (1,0) [0|0] "" Vector__XXX
 SG_ VCFRONT1_a125_FRONTIPC_steerAngle m125 : 17|1@1+ (1,0) [0|0] "" Vector__XXX
 SG_ VCFRONT1_a126_BATTIPC_sysStatus m126 : 17|1@1+ (1,0) [0|0] "" Vector__XXX
 SG_ VCFRONT1_a131_BATTIPC_power m131 : 17|1@1+ (1,0) [0|0] "" Vector__XXX
 SG_ VCFRONT1_a133_FRONTIPC_secondaryActuator m133 : 17|1@1+ (1,0) [0|0] "" Vector__XXX
 SG_ VCFRONT1_a144_BATTIPC_status m144 : 17|1@1+ (1,0) [0|0] "" Vector__XXX
 SG_ VCFRONT1_a214_tripCurrent m214 : 17|10@1- (0.1,0) [0|0] "" Vector__XXX
 SG_ VCFRONT1_a216_hvState m216 : 17|3@1+ (1,0) [0|0] "" Vector__XXX
 SG_ VCFRONT1_a223_failedFaultInject m223 : 17|1@1+ (1,0) [0|0] "" Vector__XXX
 SG_ VCFRONT1_a229_pcsMIA m229 : 17|1@1+ (1,0) [0|0] "" Vector__XXX
 SG_ VCFRONT1_a249_pcsOvShutdownArmed m249 : 17|1@1+ (1,0) [0|0] "" Vector__XXX
 SG_ VCFRONT1_a250_pcsOvShutdownArmed m250 : 17|1@1+ (1,0) [0|0] "" Vector__XXX
 SG_ VCFRONT1_a253_pcsOvSelfTestEnabled m253 : 17|1@1+ (1,0) [0|0] "" Vector__XXX
 SG_ VCFRONT1_a423_vehBusAwake m423 : 17|1@1+ (1,0) [0|0] "" Vector__XXX
 SG_ VCFRONT1_a484_upstreamEFuseVoltage m484 : 17|6@1+ (1,0) [0|0] "" Vector__XXX
 SG_ VCFRONT1_a486_bridgeFailedSyncCheck m486 : 17|1@1+ (1,0) [0|0] "" Vector__XXX
 SG_ VCFRONT1_a496_frunkOpen m496 : 17|1@1+ (1,0) [0|0] "" Vector__XXX
 SG_ VCFRONT1_a590_vcrightCurveOffsetChannel m590 : 17|3@1+ (1,0) [0|0] "" Vector__XXX
 SG_ VCFRONT1_a591_vcrightCurrentThreshold m591 : 17|12@1+ (0.1,0) [0|0] "" Vector__XXX
 SG_ VCFRONT1_a596_vcrightCutoffCurveOffsetChannel m596 : 17|3@1+ (1,0) [0|0] "" Vector__XXX
 SG_ VCFRONT1_a597_vcrightCutoffCurrentThreshold m597 : 17|12@1+ (0.1,0) [0|0] "" Vector__XXX
 SG_ VCFRONT1_a617_FRONTIPC_VC_infoMessage m617 : 17|1@1+ (1,0) [0|0] "" Vector__XXX
 SG_ VCFRONT1_a012_SoftwareReset m12 : 18|1@1+ (1,0) [0|0] "" Vector__XXX
 SG_ VCFRONT1_a015_NVMMRecordIDError m15 : 18|1@1+ (1,0) [0|0] "" Vector__XXX
 SG_ VCFRONT1_a018_VECTTBL m18 : 18|1@1+ (1,0) [0|0] "" Vector__XXX
 SG_ VCFRONT1_a019_ImpreciseBusErr m19 : 18|1@1+ (1,0) [0|0] "" Vector__XXX
 SG_ VCFRONT1_a021_Task1msMissed m21 : 18|1@1+ (1,0) [0|0] "" Vector__XXX
 SG_ VCFRONT1_a028_NoCoprocessor m28 : 18|1@1+ (1,0) [0|0] "" Vector__XXX
 SG_ VCFRONT1_a037_InstrAccessViolation m37 : 18|1@1+ (1,0) [0|0] "" Vector__XXX
 SG_ VCFRONT1_a038_userRead m38 : 18|1@1+ (1,0) [0|0] "" Vector__XXX
 SG_ VCFRONT1_a078_BATTIPC_battIpcData0 m78 : 18|1@1+ (1,0) [0|0] "" Vector__XXX
 SG_ VCFRONT1_a079_BATTIPC_frontprivData0 m79 : 18|1@1+ (1,0) [0|0] "" Vector__XXX
 SG_ VCFRONT1_a081_FRONTIPC_frontIpcData0 m81 : 18|1@1+ (1,0) [0|0] "" Vector__XXX
 SG_ VCFRONT1_a082_FRONTIPC_frontIpcData1 m82 : 18|1@1+ (1,0) [0|0] "" Vector__XXX
 SG_ VCFRONT1_a086_BATTIPC_battIpcData0 m86 : 18|1@1+ (1,0) [0|0] "" Vector__XXX
 SG_ VCFRONT1_a090_FRONTIPC_status m90 : 18|1@1+ (1,0) [0|0] "" Vector__XXX
 SG_ VCFRONT1_a103_FRONTIPC_evseStatus m103 : 18|1@1+ (1,0) [0|0] "" Vector__XXX
 SG_ VCFRONT1_a104_FRONTIPC_evseStatus m104 : 18|1@1+ (1,0) [0|0] "" Vector__XXX
 SG_ VCFRONT1_a106_VEH_dcdcStatus m106 : 18|1@1+ (1,0) [0|0] "" Vector__XXX
 SG_ VCFRONT1_a107_BATTIPC_socStatus m107 : 18|1@1+ (1,0) [0|0] "" Vector__XXX
 SG_ VCFRONT1_a108_FRONTIPC_thermalControl m108 : 18|1@1+ (1,0) [0|0] "" Vector__XXX
 SG_ VCFRONT1_a110_BATTIPC_mismatchFault m110 : 18|1@1+ (1,0) [0|0] "" Vector__XXX
 SG_ VCFRONT1_a111_BATTIPC_status m111 : 18|1@1+ (1,0) [0|0] "" Vector__XXX
 SG_ VCFRONT1_a112_BATTIPC_status m112 : 18|1@1+ (1,0) [0|0] "" Vector__XXX
 SG_ VCFRONT1_a113_FRONTIPC_vehicleControl2 m113 : 18|1@1+ (1,0) [0|0] "" Vector__XXX
 SG_ VCFRONT1_a115_BATTIPC_authentication m115 : 18|1@1+ (1,0) [0|0] "" Vector__XXX
 SG_ VCFRONT1_a116_FRONTIPC_doorStatus m116 : 18|1@1+ (1,0) [0|0] "" Vector__XXX
 SG_ VCFRONT1_a117_FRONTIPC_doorStatus m117 : 18|1@1+ (1,0) [0|0] "" Vector__XXX
 SG_ VCFRONT1_a118_FRONTIPC_frontprivData0 m118 : 18|1@1+ (1,0) [0|0] "" Vector__XXX
 SG_ VCFRONT1_a120_FRONTIPC_systemStatus m120 : 18|1@1+ (1,0) [0|0] "" Vector__XXX
 SG_ VCFRONT1_a122_FRONTIPC_occupancy m122 : 18|1@1+ (1,0) [0|0] "" Vector__XXX
 SG_ VCFRONT1_a125_FRONTIPC_info m125 : 18|1@1+ (1,0) [0|0] "" Vector__XXX
 SG_ VCFRONT1_a126_FRONTIPC_status m126 : 18|1@1+ (1,0) [0|0] "" Vector__XXX
 SG_ VCFRONT1_a191_hvState m191 : 18|3@1+ (1,0) [0|0] "" Vector__XXX
 SG_ VCFRONT1_a223_overvoltageFaultActive m223 : 18|1@1+ (1,0) [0|0] "" Vector__XXX
 SG_ VCFRONT1_a229_pcsNotSupporting m229 : 18|1@1+ (1,0) [0|0] "" Vector__XXX
 SG_ VCFRONT1_a249_ovClampBusVoltage m249 : 18|10@1+ (0.025,0) [0|0] "" Vector__XXX
 SG_ VCFRONT1_a250_battDomainHealthy m250 : 18|1@1+ (1,0) [0|0] "" Vector__XXX
 SG_ VCFRONT1_a251_rationalitySetupFailureReason m251 : 18|3@1+ (1,0) [0|0] "" Vector__XXX
 SG_ VCFRONT1_a253_busVoltage m253 : 18|10@1+ (0.025,0) [0|0] "" Vector__XXX
 SG_ VCFRONT1_a423_frontPrivBusAwake m423 : 18|1@1+ (1,0) [0|0] "" Vector__XXX
 SG_ VCFRONT1_a486_localBridgeOutputOn m486 : 18|1@1+ (1,0) [0|0] "" Vector__XXX
 SG_ VCFRONT1_a496_NotEnoughPowerForSupport m496 : 18|1@1+ (1,0) [0|0] "" Vector__XXX
 SG_ VCFRONT1_a617_FRONTIPC_status m617 : 18|1@1+ (1,0) [0|0] "" Vector__XXX
 SG_ VCFRONT1_a012_CheckstopReset m12 : 19|1@1+ (1,0) [0|0] "" Vector__XXX
 SG_ VCFRONT1_a018_MMFARVALID m18 : 19|1@1+ (1,0) [0|0] "" Vector__XXX
 SG_ VCFRONT1_a019_PreciseBusErr m19 : 19|1@1+ (1,0) [0|0] "" Vector__XXX
 SG_ VCFRONT1_a021_Task10msLate m21 : 19|1@1+ (1,0) [0|0] "" Vector__XXX
 SG_ VCFRONT1_a028_InvalidPCLoad m28 : 19|1@1+ (1,0) [0|0] "" Vector__XXX
 SG_ VCFRONT1_a037_DataAccessViolation m37 : 19|1@1+ (1,0) [0|0] "" Vector__XXX
 SG_ VCFRONT1_a038_userWrite m38 : 19|1@1+ (1,0) [0|0] "" Vector__XXX
 SG_ VCFRONT1_a078_FRONTIPC_12VBatteryStatus m78 : 19|1@1+ (1,0) [0|0] "" Vector__XXX
 SG_ VCFRONT1_a079_FRONTIPC_frontprivData1 m79 : 19|1@1+ (1,0) [0|0] "" Vector__XXX
 SG_ VCFRONT1_a081_BATTIPC_frontprivData0 m81 : 19|1@1+ (1,0) [0|0] "" Vector__XXX
 SG_ VCFRONT1_a082_BATTIPC_frontprivData0 m82 : 19|1@1+ (1,0) [0|0] "" Vector__XXX
 SG_ VCFRONT1_a086_FRONTIPC_frontprivData0 m86 : 19|1@1+ (1,0) [0|0] "" Vector__XXX
 SG_ VCFRONT1_a090_BATTIPC_state m90 : 19|1@1+ (1,0) [0|0] "" Vector__XXX
 SG_ VCFRONT1_a104_FRONTIPC_thermalStatus m104 : 19|1@1+ (1,0) [0|0] "" Vector__XXX
 SG_ VCFRONT1_a106_VEH_thermalControl m106 : 19|1@1+ (1,0) [0|0] "" Vector__XXX
 SG_ VCFRONT1_a107_BATTIPC_status m107 : 19|1@1+ (1,0) [0|0] "" Vector__XXX
 SG_ VCFRONT1_a108_FRONTIPC_motorStatus m108 : 19|1@1+ (1,0) [0|0] "" Vector__XXX
 SG_ VCFRONT1_a110_BATTIPC_time m110 : 19|1@1+ (1,0) [0|0] "" Vector__XXX
 SG_ VCFRONT1_a113_BATTIPC_powerRationalityConfig m113 : 19|1@1+ (1,0) [0|0] "" Vector__XXX
 SG_ VCFRONT1_a115_FRONTIPC_authentication m115 : 19|1@1+ (1,0) [0|0] "" Vector__XXX
 SG_ VCFRONT1_a116_FRONTIPC_LVPowerState m116 : 19|1@1+ (1,0) [0|0] "" Vector__XXX
 SG_ VCFRONT1_a117_FRONTIPC_LVPowerState m117 : 19|1@1+ (1,0) [0|0] "" Vector__XXX
 SG_ VCFRONT1_a118_FRONTIPC_frontIpcData0 m118 : 19|1@1+ (1,0) [0|0] "" Vector__XXX
 SG_ VCFRONT1_a120_BATTIPC_systemStatus m120 : 19|1@1+ (1,0) [0|0] "" Vector__XXX
 SG_ VCFRONT1_a122_FRONTIPC_occupancy2 m122 : 19|1@1+ (1,0) [0|0] "" Vector__XXX
 SG_ VCFRONT1_a126_BATTIPC_status m126 : 19|1@1+ (1,0) [0|0] "" Vector__XXX
 SG_ VCFRONT1_a220_manualDrivingProhibited m220 : 19|1@1+ (1,0) [0|0] "" Vector__XXX
 SG_ VCFRONT1_a223_sharedBridgeShutdownActive m223 : 19|1@1+ (1,0) [0|0] "" Vector__XXX
 SG_ VCFRONT1_a250_busVoltage m250 : 19|10@1+ (0.025,0) [0|0] "" Vector__XXX
 SG_ VCFRONT1_a252_incorrectPinConfiguration m252 : 19|1@1+ (1,0) [0|0] "" Vector__XXX
 SG_ VCFRONT1_a423_chBusAwake m423 : 19|1@1+ (1,0) [0|0] "" Vector__XXX
 SG_ VCFRONT1_a475_reset m475 : 19|1@1+ (1,0) [0|0] "" Vector__XXX
 SG_ VCFRONT1_a486_localBridgeSyncArmed m486 : 19|1@1+ (1,0) [0|0] "" Vector__XXX
 SG_ VCFRONT1_a490_timeout m490 : 19|1@1+ (1,0) [0|0] "" Vector__XXX
 SG_ VCFRONT1_a491_lockedModeEnable m491 : 19|1@1+ (1,0) [0|0] "" Vector__XXX
 SG_ VCFRONT1_a496_bmsState m496 : 19|4@1+ (1,0) [0|0] "" Vector__XXX
 SG_ VCFRONT1_a509_state m509 : 19|3@1+ (1,0) [0|0] "" Vector__XXX
 SG_ VCFRONT1_a581_resistance m581 : 19|10@1+ (0.0005,0) [0|0] "" Vector__XXX
 SG_ VCFRONT1_a617_BATTIPC_status m617 : 19|1@1+ (1,0) [0|0] "" Vector__XXX
 SG_ VCFRONT1_a005_faults0 m5 : 20|12@1+ (1,0) [0|0] "" Vector__XXX
 SG_ VCFRONT1_a006_fault m6 : 20|4@1+ (1,0) [0|0] "" Vector__XXX
 SG_ VCFRONT1_a012_DebugReset m12 : 20|1@1+ (1,0) [0|0] "" Vector__XXX
 SG_ VCFRONT1_a018_BFARVALID m18 : 20|1@1+ (1,0) [0|0] "" Vector__XXX
 SG_ VCFRONT1_a019_InstrBusErr m19 : 20|1@1+ (1,0) [0|0] "" Vector__XXX
 SG_ VCFRONT1_a021_Task10msStarved m21 : 20|1@1+ (1,0) [0|0] "" Vector__XXX
 SG_ VCFRONT1_a028_InvalidState m28 : 20|1@1+ (1,0) [0|0] "" Vector__XXX
 SG_ VCFRONT1_a038_userExecute m38 : 20|1@1+ (1,0) [0|0] "" Vector__XXX
 SG_ VCFRONT1_a078_FRONTIPC_LVHealth m78 : 20|1@1+ (1,0) [0|0] "" Vector__XXX
 SG_ VCFRONT1_a079_BATTIPC_frontprivData2 m79 : 20|1@1+ (1,0) [0|0] "" Vector__XXX
 SG_ VCFRONT1_a081_BATTIPC_LVHealth m81 : 20|1@1+ (1,0) [0|0] "" Vector__XXX
 SG_ VCFRONT1_a090_BATTIPC_vbatVoltage m90 : 20|1@1+ (1,0) [0|0] "" Vector__XXX
 SG_ VCFRONT1_a104_FRONTIPC_status m104 : 20|1@1+ (1,0) [0|0] "" Vector__XXX
 SG_ VCFRONT1_a106_VEH_dcdcRailStatus m106 : 20|1@1+ (1,0) [0|0] "" Vector__XXX
 SG_ VCFRONT1_a107_BATTIPC_energyStatus m107 : 20|1@1+ (1,0) [0|0] "" Vector__XXX
 SG_ VCFRONT1_a110_BATTIPC_updateStatus m110 : 20|1@1+ (1,0) [0|0] "" Vector__XXX
 SG_ VCFRONT1_a113_BATTIPC_status m113 : 20|1@1+ (1,0) [0|0] "" Vector__XXX
 SG_ VCFRONT1_a115_FRONTIPC_requests m115 : 20|1@1+ (1,0) [0|0] "" Vector__XXX
 SG_ VCFRONT1_a116_FRONTIPC_thsStatus m116 : 20|1@1+ (1,0) [0|0] "" Vector__XXX
 SG_ VCFRONT1_a117_FRONTIPC_bmbMinMax m117 : 20|1@1+ (1,0) [0|0] "" Vector__XXX
 SG_ VCFRONT1_a118_FRONTIPC_LVPowerState m118 : 20|1@1+ (1,0) [0|0] "" Vector__XXX
 SG_ VCFRONT1_a120_FRONTIPC_systemPower m120 : 20|1@1+ (1,0) [0|0] "" Vector__XXX
 SG_ VCFRONT1_a188_bridgeManagerState m188 : 20|4@1+ (1,0) [0|0] "" Vector__XXX
 SG_ VCFRONT1_a216_vcrightFastBlowImminent m216 : 20|1@1+ (1,0) [0|0] "" Vector__XXX
 SG_ VCFRONT1_a220_vehicleSpeed m220 : 20|12@1+ (0.08,-40) [0|0] "" Vector__XXX
 SG_ VCFRONT1_a223_timedOut m223 : 20|1@1+ (1,0) [0|0] "" Vector__XXX
 SG_ VCFRONT1_a252_incorrectClampMonitor1Voltage m252 : 20|1@1+ (1,0) [0|0] "" Vector__XXX
 SG_ VCFRONT1_a423_hvsBusAwake m423 : 20|1@1+ (1,0) [0|0] "" Vector__XXX
 SG_ VCFRONT1_a475_spiError m475 : 20|1@1+ (1,0) [0|0] "" Vector__XXX
 SG_ VCFRONT1_a486_localBridgeDinState m486 : 20|1@1+ (1,0) [0|0] "" Vector__XXX
 SG_ VCFRONT1_a490_outputOn m490 : 20|1@1+ (1,0) [0|0] "" Vector__XXX
 SG_ VCFRONT1_a491_nvmDefCfgEn m491 : 20|1@1+ (1,0) [0|0] "" Vector__XXX
 SG_ VCFRONT1_a617_FRONTIPC_defogInfoMessage m617 : 20|1@1+ (1,0) [0|0] "" Vector__XXX
 SG_ VCFRONT1_a012_ExternalReset m12 : 21|1@1+ (1,0) [0|0] "" Vector__XXX
 SG_ VCFRONT1_a021_Task10msMissed m21 : 21|1@1+ (1,0) [0|0] "" Vector__XXX
 SG_ VCFRONT1_a028_UndefInstr m28 : 21|1@1+ (1,0) [0|0] "" Vector__XXX
 SG_ VCFRONT1_a038_privilegedRead m38 : 21|1@1+ (1,0) [0|0] "" Vector__XXX
 SG_ VCFRONT1_a078_FRONTIPC_LVSelfTests m78 : 21|1@1+ (1,0) [0|0] "" Vector__XXX
 SG_ VCFRONT1_a079_FRONTIPC_frontprivData2 m79 : 21|1@1+ (1,0) [0|0] "" Vector__XXX
 SG_ VCFRONT1_a081_BATTIPC_LVSelfTests m81 : 21|1@1+ (1,0) [0|0] "" Vector__XXX
 SG_ VCFRONT1_a090_FRONTIPC_vbatVoltage m90 : 21|1@1+ (1,0) [0|0] "" Vector__XXX
 SG_ VCFRONT1_a104_BATTIPC_bodyControls m104 : 21|1@1+ (1,0) [0|0] "" Vector__XXX
 SG_ VCFRONT1_a106_CH_dcdcRailStatus m106 : 21|1@1+ (1,0) [0|0] "" Vector__XXX
 SG_ VCFRONT1_a107_FRONTIPC_bmbMinMax m107 : 21|1@1+ (1,0) [0|0] "" Vector__XXX
 SG_ VCFRONT1_a110_FRONTIPC_vehNm m110 : 21|1@1+ (1,0) [0|0] "" Vector__XXX
 SG_ VCFRONT1_a113_BATTIPC_vehicleControl m113 : 21|1@1+ (1,0) [0|0] "" Vector__XXX
 SG_ VCFRONT1_a115_FRONTIPC_thsStatus m115 : 21|1@1+ (1,0) [0|0] "" Vector__XXX
 SG_ VCFRONT1_a116_FRONTIPC_status m116 : 21|1@1+ (1,0) [0|0] "" Vector__XXX
 SG_ VCFRONT1_a117_FRONTIPC_chargeInfo m117 : 21|1@1+ (1,0) [0|0] "" Vector__XXX
 SG_ VCFRONT1_a118_BATTIPC_LVHealth m118 : 21|1@1+ (1,0) [0|0] "" Vector__XXX
 SG_ VCFRONT1_a120_FRONTIPC_odometerStatus m120 : 21|1@1+ (1,0) [0|0] "" Vector__XXX
 SG_ VCFRONT1_a216_vcrightFastBlowDebounceImminent m216 : 21|1@1+ (1,0) [0|0] "" Vector__XXX
 SG_ VCFRONT1_a251_clampLowSideCheckResult m251 : 21|2@1+ (1,0) [0|0] "" Vector__XXX
 SG_ VCFRONT1_a252_incorrectClampMonitor2Voltage m252 : 21|1@1+ (1,0) [0|0] "" Vector__XXX
 SG_ VCFRONT1_a423_partyBusAwake m423 : 21|1@1+ (1,0) [0|0] "" Vector__XXX
 SG_ VCFRONT1_a475_autoOn m475 : 21|1@1+ (1,0) [0|0] "" Vector__XXX
 SG_ VCFRONT1_a486_remoteBridgeOutputOn m486 : 21|1@1+ (1,0) [0|0] "" Vector__XXX
 SG_ VCFRONT1_a491_fsMode m491 : 21|2@1+ (1,0) [0|0] "" Vector__XXX
 SG_ VCFRONT1_a021_Task100msLate m21 : 22|1@1+ (1,0) [0|0] "" Vector__XXX
 SG_ VCFRONT1_a038_privilegedWrite m38 : 22|1@1+ (1,0) [0|0] "" Vector__XXX
 SG_ VCFRONT1_a078_BATTIPC_12VBatteryStatus m78 : 22|1@1+ (1,0) [0|0] "" Vector__XXX
 SG_ VCFRONT1_a079_BATTIPC_systemStatus m79 : 22|1@1+ (1,0) [0|0] "" Vector__XXX
 SG_ VCFRONT1_a104_FRONTIPC_matrixHighBeamRequest m104 : 22|1@1+ (1,0) [0|0] "" Vector__XXX
 SG_ VCFRONT1_a106_CH_alertMatrix m106 : 22|1@1+ (1,0) [0|0] "" Vector__XXX
 SG_ VCFRONT1_a107_FRONTIPC_chargeInfo m107 : 22|1@1+ (1,0) [0|0] "" Vector__XXX
 SG_ VCFRONT1_a110_FRONTIPC_carConfig m110 : 22|1@1+ (1,0) [0|0] "" Vector__XXX
 SG_ VCFRONT1_a113_BATTIPC_vehicleControl2 m113 : 22|1@1+ (1,0) [0|0] "" Vector__XXX
 SG_ VCFRONT1_a115_FRONTIPC_ChildSeatStatus m115 : 22|1@1+ (1,0) [0|0] "" Vector__XXX
 SG_ VCFRONT1_a116_FRONTIPC_hvacStatus m116 : 22|1@1+ (1,0) [0|0] "" Vector__XXX
 SG_ VCFRONT1_a117_FRONTIPC_energyStatus m117 : 22|1@1+ (1,0) [0|0] "" Vector__XXX
 SG_ VCFRONT1_a118_BATTIPC_LVPowerState m118 : 22|1@1+ (1,0) [0|0] "" Vector__XXX
 SG_ VCFRONT1_a216_vcrightStaticImminent m216 : 22|1@1+ (1,0) [0|0] "" Vector__XXX
 SG_ VCFRONT1_a252_incorrectClampMonitor3Voltage m252 : 22|1@1+ (1,0) [0|0] "" Vector__XXX
 SG_ VCFRONT1_a414_loadUnattemptedOnFailure m414 : 22|1@1+ (1,0) [0|0] "" Vector__XXX
 SG_ VCFRONT1_a423_ethBusAwake m423 : 22|1@1+ (1,0) [0|0] "" Vector__XXX
 SG_ VCFRONT1_a475_diagnosticBit m475 : 22|1@1+ (1,0) [0|0] "" Vector__XXX
 SG_ VCFRONT1_a486_remoteBridgeOutputOnValid m486 : 22|1@1+ (1,0) [0|0] "" Vector__XXX
 SG_ VCFRONT1_a021_Task100msStarved m21 : 23|1@1+ (1,0) [0|0] "" Vector__XXX
 SG_ VCFRONT1_a038_privilegedExecute m38 : 23|1@1+ (1,0) [0|0] "" Vector__XXX
 SG_ VCFRONT1_a078_BATTIPC_pcsInterface m78 : 23|1@1+ (1,0) [0|0] "" Vector__XXX
 SG_ VCFRONT1_a079_FRONTIPC_systemStatus m79 : 23|1@1+ (1,0) [0|0] "" Vector__XXX
 SG_ VCFRONT1_a104_FRONTIPC_matrixBendAngleRequest m104 : 23|1@1+ (1,0) [0|0] "" Vector__XXX
 SG_ VCFRONT1_a106_FRONTIPC_thermalControl m106 : 23|1@1+ (1,0) [0|0] "" Vector__XXX
 SG_ VCFRONT1_a107_FRONTIPC_energyStatus m107 : 23|1@1+ (1,0) [0|0] "" Vector__XXX
 SG_ VCFRONT1_a110_FRONTIPC_carState m110 : 23|1@1+ (1,0) [0|0] "" Vector__XXX
 SG_ VCFRONT1_a113_BATTIPC_vehicleControl3 m113 : 23|1@1+ (1,0) [0|0] "" Vector__XXX
 SG_ VCFRONT1_a115_FRONTIPC_TPMSData m115 : 23|1@1+ (1,0) [0|0] "" Vector__XXX
 SG_ VCFRONT1_a116_FRONTIPC_restraintStatus m116 : 23|1@1+ (1,0) [0|0] "" Vector__XXX
 SG_ VCFRONT1_a117_FRONTIPC_packConfig m117 : 23|1@1+ (1,0) [0|0] "" Vector__XXX
 SG_ VCFRONT1_a118_BATTIPC_coolant m118 : 23|1@1+ (1,0) [0|0] "" Vector__XXX
 SG_ VCFRONT1_a216_vcrightDynamicImminent m216 : 23|1@1+ (1,0) [0|0] "" Vector__XXX
 SG_ VCFRONT1_a252_incorrectPcsEnableLineVoltage m252 : 23|1@1+ (1,0) [0|0] "" Vector__XXX
 SG_ VCFRONT1_a414_deviceStuckOnFailure m414 : 23|1@1+ (1,0) [0|0] "" Vector__XXX
 SG_ VCFRONT1_a423_sleepShutdownComplete m423 : 23|1@1+ (1,0) [0|0] "" Vector__XXX
 SG_ VCFRONT1_a475_deviceError m475 : 23|1@1+ (1,0) [0|0] "" Vector__XXX
 SG_ VCFRONT1_a486_remoteBridgeSyncArmed m486 : 23|1@1+ (1,0) [0|0] "" Vector__XXX
 SG_ VCFRONT1_a491_dinCtrlOpt m491 : 23|1@1+ (1,0) [0|0] "" Vector__XXX
 SG_ VCFRONT1_a006_mailboxID m6 : 24|8@1+ (1,0) [0|0] "" Vector__XXX
 SG_ VCFRONT1_a018_faultAddress m18 : 24|32@1+ (1,0) [0|0] "" Vector__XXX
 SG_ VCFRONT1_a019_faultAddress m19 : 24|32@1+ (1,0) [0|0] "" Vector__XXX
 SG_ VCFRONT1_a021_Task100msMissed m21 : 24|1@1+ (1,0) [0|0] "" Vector__XXX
 SG_ VCFRONT1_a022_TaskInitError0 m22 : 24|8@1+ (1,0) [0|0] "" Vector__XXX
 SG_ VCFRONT1_a031_uds_bytes_1 m31 : 24|8@1+ (1,0) [0|0] "" Vector__XXX
 SG_ VCFRONT1_a036_intIdx m36 : 24|10@1+ (1,0) [0|0] "" Vector__XXX
 SG_ VCFRONT1_a037_faultAddress m37 : 24|32@1+ (1,0) [0|0] "" Vector__XXX
 SG_ VCFRONT1_a038_nonSecure m38 : 24|1@1+ (1,0) [0|0] "" Vector__XXX
 SG_ VCFRONT1_a039_faultAddress m39 : 24|32@1+ (1,0) [0|0] "" Vector__XXX
 SG_ VCFRONT1_a040_programCounter m40 : 24|32@1+ (1,0) [0|0] "" Vector__XXX
 SG_ VCFRONT1_a041_CPULoad1msTask m41 : 24|8@1+ (1,0) [0|0] "" Vector__XXX
 SG_ VCFRONT1_a042_Usage10msTask m42 : 24|8@1+ (1,0) [0|0] "" Vector__XXX
 SG_ VCFRONT1_a063_switchType m63 : 24|8@1+ (1,0) [0|0] "" Vector__XXX
 SG_ VCFRONT1_a078_BATTIPC_LVSelfTests m78 : 24|1@1+ (1,0) [0|0] "" Vector__XXX
 SG_ VCFRONT1_a104_BATTIPC_matrixBendAngleRequest m104 : 24|1@1+ (1,0) [0|0] "" Vector__XXX
 SG_ VCFRONT1_a106_FRONTIPC_dcdcRailStatus m106 : 24|1@1+ (1,0) [0|0] "" Vector__XXX
 SG_ VCFRONT1_a107_FRONTIPC_packConfig m107 : 24|1@1+ (1,0) [0|0] "" Vector__XXX
 SG_ VCFRONT1_a110_FRONTIPC_updateStatus m110 : 24|1@1+ (1,0) [0|0] "" Vector__XXX
 SG_ VCFRONT1_a113_BATTIPC_vehicleModes m113 : 24|1@1+ (1,0) [0|0] "" Vector__XXX
 SG_ VCFRONT1_a116_FRONTIPC_switchStatus m116 : 24|1@1+ (1,0) [0|0] "" Vector__XXX
 SG_ VCFRONT1_a117_FRONTIPC_powerAvailable m117 : 24|1@1+ (1,0) [0|0] "" Vector__XXX
 SG_ VCFRONT1_a118_BATTIPC_lighting m118 : 24|1@1+ (1,0) [0|0] "" Vector__XXX
 SG_ VCFRONT1_a188_bridgeEFuseState m188 : 24|3@1+ (1,0) [0|0] "" Vector__XXX
 SG_ VCFRONT1_a191_busVoltage m191 : 24|8@1+ (0.08741903380905883,0) [0|0] "" Vector__XXX
 SG_ VCFRONT1_a251_clampLowSideFailureReason m251 : 24|3@1+ (1,0) [0|0] "" Vector__XXX
 SG_ VCFRONT1_a252_incorrectPcsTripState m252 : 24|1@1+ (1,0) [0|0] "" Vector__XXX
 SG_ VCFRONT1_a414_followerVCRightSelfTestFailure m414 : 24|1@1+ (1,0) [0|0] "" Vector__XXX
 SG_ VCFRONT1_a423_sleepRequest m423 : 24|1@1+ (1,0) [0|0] "" Vector__XXX
 SG_ VCFRONT1_a475_unexpectedLock m475 : 24|1@1+ (1,0) [0|0] "" Vector__XXX
 SG_ VCFRONT1_a484_vbusVoltage m484 : 24|6@1+ (1,0) [0|0] "" Vector__XXX
 SG_ VCFRONT1_a486_remoteBridgeSyncArmedValid m486 : 24|1@1+ (1,0) [0|0] "" Vector__XXX
 SG_ VCFRONT1_a489_VDSDiff m489 : 24|8@1+ (1,0) [0|0] "" Vector__XXX
 SG_ VCFRONT1_a490_VDSDiff m490 : 24|8@1+ (1,0) [0|0] "" Vector__XXX
 SG_ VCFRONT1_a491_dinCtrlEn m491 : 24|1@1+ (1,0) [0|0] "" Vector__XXX
 SG_ VCFRONT1_a509_expectedState m509 : 24|3@1+ (1,0) [0|0] "" Vector__XXX
 SG_ VCFRONT1_a590_vcrightATerm m590 : 24|16@1+ (50,0) [0|0] "" Vector__XXX
 SG_ VCFRONT1_a596_vcrightCutoffATerm m596 : 24|16@1+ (50,0) [0|0] "" Vector__XXX
 SG_ VCFRONT1_a021_Task1000msLate m21 : 25|1@1+ (1,0) [0|0] "" Vector__XXX
 SG_ VCFRONT1_a038_busMaster m38 : 25|4@1+ (1,0) [0|0] "" Vector__XXX
 SG_ VCFRONT1_a078_FRONTIPC_LVBMS_statusLow m78 : 25|1@1+ (1,0) [0|0] "" Vector__XXX
 SG_ VCFRONT1_a104_BATTIPC_matrixHighBeamRequest m104 : 25|1@1+ (1,0) [0|0] "" Vector__XXX
 SG_ VCFRONT1_a106_FRONTIPC_dcdcStatus m106 : 25|1@1+ (1,0) [0|0] "" Vector__XXX
 SG_ VCFRONT1_a107_FRONTIPC_powerAvailable m107 : 25|1@1+ (1,0) [0|0] "" Vector__XXX
 SG_ VCFRONT1_a110_FRONTIPC_time m110 : 25|1@1+ (1,0) [0|0] "" Vector__XXX
 SG_ VCFRONT1_a113_FRONTIPC_vehicleControl m113 : 25|1@1+ (1,0) [0|0] "" Vector__XXX
 SG_ VCFRONT1_a116_FRONTIPC_lightStatus m116 : 25|1@1+ (1,0) [0|0] "" Vector__XXX
 SG_ VCFRONT1_a117_FRONTIPC_socStatus m117 : 25|1@1+ (1,0) [0|0] "" Vector__XXX
 SG_ VCFRONT1_a118_BATTIPC_sensors m118 : 25|1@1+ (1,0) [0|0] "" Vector__XXX
 SG_ VCFRONT1_a252_incorrectPcsSupportStatus m252 : 25|1@1+ (1,0) [0|0] "" Vector__XXX
 SG_ VCFRONT1_a414_bridgeFailedToOpen m414 : 25|1@1+ (1,0) [0|0] "" Vector__XXX
 SG_ VCFRONT1_a423_readyToSleepFailed m423 : 25|1@1+ (1,0) [0|0] "" Vector__XXX
 SG_ VCFRONT1_a475_unexpectedFailSafe m475 : 25|1@1+ (1,0) [0|0] "" Vector__XXX
 SG_ VCFRONT1_a486_remoteBridgeDinState m486 : 25|1@1+ (1,0) [0|0] "" Vector__XXX
 SG_ VCFRONT1_a491_tNom m491 : 25|8@1+ (1,0) [0|0] "" Vector__XXX
 SG_ VCFRONT1_a021_Task1000msStarved m21 : 26|1@1+ (1,0) [0|0] "" Vector__XXX
 SG_ VCFRONT1_a078_FRONTIPC_LVBMS_statusHigh m78 : 26|1@1+ (1,0) [0|0] "" Vector__XXX
 SG_ VCFRONT1_a104_BATTIPC_status m104 : 26|1@1+ (1,0) [0|0] "" Vector__XXX
 SG_ VCFRONT1_a107_FRONTIPC_socStatus m107 : 26|1@1+ (1,0) [0|0] "" Vector__XXX
 SG_ VCFRONT1_a110_BATTIPC_canLogAvailability m110 : 26|1@1+ (1,0) [0|0] "" Vector__XXX
 SG_ VCFRONT1_a113_FRONTIPC_chargeRequest m113 : 26|1@1+ (1,0) [0|0] "" Vector__XXX
 SG_ VCFRONT1_a116_BATTIPC_hvacStatus m116 : 26|1@1+ (1,0) [0|0] "" Vector__XXX
 SG_ VCFRONT1_a117_FRONTIPC_thermalStatus m117 : 26|1@1+ (1,0) [0|0] "" Vector__XXX
 SG_ VCFRONT1_a118_BATTIPC_status m118 : 26|1@1+ (1,0) [0|0] "" Vector__XXX
 SG_ VCFRONT1_a204_BRailLocked m204 : 26|1@1+ (1,0) [0|0] "" Vector__XXX
 SG_ VCFRONT1_a205_BRailLocked m205 : 26|1@1+ (1,0) [0|0] "" Vector__XXX
 SG_ VCFRONT1_a252_incorrectPcsDcdcEnableFeedback m252 : 26|1@1+ (1,0) [0|0] "" Vector__XXX
 SG_ VCFRONT1_a414_uvLoadshedVsenseDigIn m414 : 26|1@1+ (1,0) [0|0] "" Vector__XXX
 SG_ VCFRONT1_a423_requestSleepFailed m423 : 26|1@1+ (1,0) [0|0] "" Vector__XXX
 SG_ VCFRONT1_a475_disableOutputFault m475 : 26|1@1+ (1,0) [0|0] "" Vector__XXX
 SG_ VCFRONT1_a486_remoteBridgeDinStateValid m486 : 26|1@1+ (1,0) [0|0] "" Vector__XXX
 SG_ VCFRONT1_a021_Task1000msMissed m21 : 27|1@1+ (1,0) [0|0] "" Vector__XXX
 SG_ VCFRONT1_a078_BATTIPC_LVBMS_statusLow m78 : 27|1@1+ (1,0) [0|0] "" Vector__XXX
 SG_ VCFRONT1_a104_FRONTIPC_bodyControls2 m104 : 27|1@1+ (1,0) [0|0] "" Vector__XXX
 SG_ VCFRONT1_a107_FRONTIPC_vehicleNotifications m107 : 27|1@1+ (1,0) [0|0] "" Vector__XXX
 SG_ VCFRONT1_a110_FRONTIPC_canLogAvailability m110 : 27|1@1+ (1,0) [0|0] "" Vector__XXX
 SG_ VCFRONT1_a113_FRONTIPC_vehicleModes m113 : 27|1@1+ (1,0) [0|0] "" Vector__XXX
 SG_ VCFRONT1_a116_BATTIPC_LVPowerState m116 : 27|1@1+ (1,0) [0|0] "" Vector__XXX
 SG_ VCFRONT1_a117_FRONTIPC_thermalStatus2 m117 : 27|1@1+ (1,0) [0|0] "" Vector__XXX
 SG_ VCFRONT1_a118_FRONTIPC_systemStatus m118 : 27|1@1+ (1,0) [0|0] "" Vector__XXX
 SG_ VCFRONT1_a188_frontPrivBusAwake m188 : 27|1@1+ (1,0) [0|0] "" Vector__XXX
 SG_ VCFRONT1_a204_uvLoadshedFaultInject m204 : 27|1@1+ (1,0) [0|0] "" Vector__XXX
 SG_ VCFRONT1_a205_ovLoadshedFaultInject m205 : 27|1@1+ (1,0) [0|0] "" Vector__XXX
 SG_ VCFRONT1_a214_clearCurrent m214 : 27|10@1- (0.1,0) [0|0] "" Vector__XXX
 SG_ VCFRONT1_a251_rationalityShutdownArmedCheckResult m251 : 27|2@1+ (1,0) [0|0] "" Vector__XXX
 SG_ VCFRONT1_a252_pcsOvShutdownFaultPinActive m252 : 27|1@1+ (1,0) [0|0] "" Vector__XXX
 SG_ VCFRONT1_a475_vsUndervoltage m475 : 27|1@1+ (1,0) [0|0] "" Vector__XXX
 SG_ VCFRONT1_a509_hardwareLockout m509 : 27|1@1+ (1,0) [0|0] "" Vector__XXX
 SG_ VCFRONT1_a058_current m58 : 28|11@1+ (0.1,0) [0|0] "" Vector__XXX
 SG_ VCFRONT1_a059_resistanceEstimate m59 : 28|12@1+ (0.00244,0) [0|0] "" Vector__XXX
 SG_ VCFRONT1_a104_BATTIPC_bodyControls2 m104 : 28|1@1+ (1,0) [0|0] "" Vector__XXX
 SG_ VCFRONT1_a107_FRONTIPC_thermalStatus m107 : 28|1@1+ (1,0) [0|0] "" Vector__XXX
 SG_ VCFRONT1_a110_FRONTIPC_mismatchFault m110 : 28|1@1+ (1,0) [0|0] "" Vector__XXX
 SG_ VCFRONT1_a113_FRONTIPC_driverProfileRecall2 m113 : 28|1@1+ (1,0) [0|0] "" Vector__XXX
 SG_ VCFRONT1_a116_BATTIPC_doorStatus m116 : 28|1@1+ (1,0) [0|0] "" Vector__XXX
 SG_ VCFRONT1_a117_FRONTIPC_lightStatus m117 : 28|1@1+ (1,0) [0|0] "" Vector__XXX
 SG_ VCFRONT1_a118_BATTIPC_systemStatus m118 : 28|1@1+ (1,0) [0|0] "" Vector__XXX
 SG_ VCFRONT1_a249_ovClampReferenceVoltage m249 : 28|7@1+ (0.025,0) [0|0] "" Vector__XXX
 SG_ VCFRONT1_a252_pcsOvShutdownArmed m252 : 28|1@1+ (1,0) [0|0] "" Vector__XXX
 SG_ VCFRONT1_a253_ovClampTvsDiodeVoltage1 m253 : 28|9@1+ (0.025,0) [0|0] "" Vector__XXX
 SG_ VCFRONT1_a475_hardShort m475 : 28|1@1+ (1,0) [0|0] "" Vector__XXX
 SG_ VCFRONT1_a104_BATTIPC_cameraCleaningControl m104 : 29|1@1+ (1,0) [0|0] "" Vector__XXX
 SG_ VCFRONT1_a107_FRONTIPC_thermalStatus2 m107 : 29|1@1+ (1,0) [0|0] "" Vector__XXX
 SG_ VCFRONT1_a110_BATTIPC_status m110 : 29|1@1+ (1,0) [0|0] "" Vector__XXX
 SG_ VCFRONT1_a113_FRONTIPC_debugECU m113 : 29|1@1+ (1,0) [0|0] "" Vector__XXX
 SG_ VCFRONT1_a116_BATTIPC_thsStatus m116 : 29|1@1+ (1,0) [0|0] "" Vector__XXX
 SG_ VCFRONT1_a117_FRONTIPC_pitchEstimation m117 : 29|1@1+ (1,0) [0|0] "" Vector__XXX
 SG_ VCFRONT1_a118_FRONTIPC_12VBatteryStatus m118 : 29|1@1+ (1,0) [0|0] "" Vector__XXX
 SG_ VCFRONT1_a250_dcdcEnableLineVoltage m250 : 29|9@1+ (0.05,0) [0|0] "" Vector__XXX
 SG_ VCFRONT1_a251_rationalityShutdownArmedFailureReason m251 : 29|3@1+ (1,0) [0|0] "" Vector__XXX
 SG_ VCFRONT1_a252_pcsSupporting m252 : 29|1@1+ (1,0) [0|0] "" Vector__XXX
 SG_ VCFRONT1_a475_prechargeFailure m475 : 29|1@1+ (1,0) [0|0] "" Vector__XXX
 SG_ VCFRONT1_a581_criticalResistance m581 : 29|10@1+ (0.0005,0) [0|0] "" Vector__XXX
 SG_ VCFRONT1_a104_BATTIPC_bodyControls3 m104 : 30|1@1+ (1,0) [0|0] "" Vector__XXX
 SG_ VCFRONT1_a110_BATTIPC_vehNm m110 : 30|1@1+ (1,0) [0|0] "" Vector__XXX
 SG_ VCFRONT1_a113_FRONTIPC_gpsTime m113 : 30|1@1+ (1,0) [0|0] "" Vector__XXX
 SG_ VCFRONT1_a116_FRONTIPC_windowStatus m116 : 30|1@1+ (1,0) [0|0] "" Vector__XXX
 SG_ VCFRONT1_a117_BATTIPC_pitchEstimation m117 : 30|1@1+ (1,0) [0|0] "" Vector__XXX
 SG_ VCFRONT1_a118_BATTIPC_12VBatteryStatus m118 : 30|1@1+ (1,0) [0|0] "" Vector__XXX
 SG_ VCFRONT1_a252_pcsDcdcEnableFeedback m252 : 30|1@1+ (1,0) [0|0] "" Vector__XXX
 SG_ VCFRONT1_a475_vdsMax m475 : 30|1@1+ (1,0) [0|0] "" Vector__XXX
 SG_ VCFRONT1_a113_FRONTIPC_hvacRequest m113 : 31|1@1+ (1,0) [0|0] "" Vector__XXX
 SG_ VCFRONT1_a116_BATTIPC_AP_hvacState10Hz m116 : 31|1@1+ (1,0) [0|0] "" Vector__XXX
 SG_ VCFRONT1_a117_BATTIPC_switchStatus m117 : 31|1@1+ (1,0) [0|0] "" Vector__XXX
 SG_ VCFRONT1_a118_BATTIPC_vehicleStatus m118 : 31|1@1+ (1,0) [0|0] "" Vector__XXX
 SG_ VCFRONT1_a252_pcsOvClampArmed m252 : 31|1@1+ (1,0) [0|0] "" Vector__XXX
 SG_ VCFRONT1_a475_bypassSaturation m475 : 31|1@1+ (1,0) [0|0] "" Vector__XXX
 SG_ VCFRONT1_a003_LineNumber m3 : 32|16@1+ (1,0) [0|0] "" Vector__XXX
 SG_ VCFRONT1_a005_busID1 m5 : 32|4@1+ (1,0) [0|0] "" Vector__XXX
 SG_ VCFRONT1_a006_messageID m6 : 32|29@1+ (1,0) [0|0] "" Vector__XXX
 SG_ VCFRONT1_a016_NVMMRecordNotFound m16 : 32|1@1+ (1,0) [0|0] "" Vector__XXX
 SG_ VCFRONT1_a022_TaskInitError1 m22 : 32|8@1+ (1,0) [0|0] "" Vector__XXX
 SG_ VCFRONT1_a031_uds_bytes_2 m31 : 32|8@1+ (1,0) [0|0] "" Vector__XXX
 SG_ VCFRONT1_a038_protectionContext m38 : 32|4@1+ (1,0) [0|0] "" Vector__XXX
 SG_ VCFRONT1_a041_CPULoad10msTask m41 : 32|8@1+ (1,0) [0|0] "" Vector__XXX
 SG_ VCFRONT1_a042_Usage100msTask m42 : 32|8@1+ (1,0) [0|0] "" Vector__XXX
 SG_ VCFRONT1_a063_ADCVoltage m63 : 32|8@1+ (0.025,0) [0|0] "" Vector__XXX
 SG_ VCFRONT1_a113_FRONTIPC_hvacDebugControl m113 : 32|1@1+ (1,0) [0|0] "" Vector__XXX
 SG_ VCFRONT1_a116_FRONTIPC_systemStatus m116 : 32|1@1+ (1,0) [0|0] "" Vector__XXX
 SG_ VCFRONT1_a117_BATTIPC_lightStatus m117 : 32|1@1+ (1,0) [0|0] "" Vector__XXX
 SG_ VCFRONT1_a118_BATTIPC_pcsInterface m118 : 32|1@1+ (1,0) [0|0] "" Vector__XXX
 SG_ VCFRONT1_a127_iBoosterEFuseVoltage m127 : 32|16@1+ (0.1,0) [0|0] "" Vector__XXX
 SG_ VCFRONT1_a128_vcrightEFuseVoltage m128 : 32|16@1+ (0.1,0) [0|0] "" Vector__XXX
 SG_ VCFRONT1_a129_pcsEFuseVoltage m129 : 32|16@1+ (0.1,0) [0|0] "" Vector__XXX
 SG_ VCFRONT1_a130_autopilot2EFuseVoltage m130 : 32|16@1+ (0.1,0) [0|0] "" Vector__XXX
 SG_ VCFRONT1_a132_epas2EFuseVoltage m132 : 32|16@1+ (0.1,0) [0|0] "" Vector__XXX
 SG_ VCFRONT1_a134_hvContactorsEFuseVoltage m134 : 32|16@1+ (0.1,0) [0|0] "" Vector__XXX
 SG_ VCFRONT1_a177_mcuAudioEFuseVoltage m177 : 32|16@1+ (0.1,0) [0|0] "" Vector__XXX
 SG_ VCFRONT1_a188_vehiclePowerState m188 : 32|5@1+ (1,0) [0|0] "" Vector__XXX
 SG_ VCFRONT1_a191_serviceMode m191 : 32|1@1+ (1,0) [0|0] "" Vector__XXX
 SG_ VCFRONT1_a204_pcsBridgeCurrent m204 : 32|16@1- (0.0625,0) [0|0] "" Vector__XXX
 SG_ VCFRONT1_a205_pcsBridgeCurrent m205 : 32|16@1- (0.0625,0) [0|0] "" Vector__XXX
 SG_ VCFRONT1_a220_lvHealthStatus m220 : 32|3@1+ (1,0) [0|0] "" Vector__XXX
 SG_ VCFRONT1_a251_clampHighSideCheckResult m251 : 32|2@1+ (1,0) [0|0] "" Vector__XXX
 SG_ VCFRONT1_a252_pcsOvSelfTestEnabled m252 : 32|1@1+ (1,0) [0|0] "" Vector__XXX
 SG_ VCFRONT1_a262_vbatProtVoltage m262 : 32|16@1+ (0.1,0) [0|0] "" Vector__XXX
 SG_ VCFRONT1_a263_vbatProtVoltage m263 : 32|16@1+ (0.1,0) [0|0] "" Vector__XXX
 SG_ VCFRONT1_a264_vbatProtVoltage m264 : 32|16@1+ (0.1,0) [0|0] "" Vector__XXX
 SG_ VCFRONT1_a266_vbatProtVoltage m266 : 32|16@1+ (0.1,0) [0|0] "" Vector__XXX
 SG_ VCFRONT1_a423_requestSleepFailedBitmask m423 : 32|16@1+ (1,0) [0|0] "" Vector__XXX
 SG_ VCFRONT1_a475_fuseLatch m475 : 32|1@1+ (1,0) [0|0] "" Vector__XXX
 SG_ VCFRONT1_a482_lvBridgeEFuseVoltage m482 : 32|16@1+ (0.1,0) [0|0] "" Vector__XXX
 SG_ VCFRONT1_a484_upstreamEFuseRatio m484 : 32|7@1+ (1,0) [0|0] "" Vector__XXX
 SG_ VCFRONT1_a489_stuckOnVDS m489 : 32|10@1+ (1,0) [0|0] "" Vector__XXX
 SG_ VCFRONT1_a490_VDSFinished m490 : 32|1@1+ (1,0) [0|0] "" Vector__XXX
 SG_ VCFRONT1_a509_unlocksRemaining m509 : 32|8@1+ (1,0) [0|0] "" Vector__XXX
 SG_ VCFRONT1_a574_frontDriveInverterRemainingRetries m574 : 32|8@1+ (1,0) [0|0] "" Vector__XXX
 SG_ VCFRONT1_a578_vbusFusedLoadShedVoltage m578 : 32|16@1+ (0.1,0) [0|0] "" Vector__XXX
 SG_ VCFRONT1_a591_vcrightTimingThresholdMs m591 : 32|16@1+ (1,0) [0|0] "" Vector__XXX
 SG_ VCFRONT1_a597_vcrightCutoffTimingThresholdMs m597 : 32|16@1+ (1,0) [0|0] "" Vector__XXX
 SG_ VCFRONT1_a016_NVMMCRCMismatch m16 : 33|1@1+ (1,0) [0|0] "" Vector__XXX
 SG_ VCFRONT1_a113_FRONTIPC_status m113 : 33|1@1+ (1,0) [0|0] "" Vector__XXX
 SG_ VCFRONT1_a116_BATTIPC_systemStatus m116 : 33|1@1+ (1,0) [0|0] "" Vector__XXX
 SG_ VCFRONT1_a117_BATTIPC_doorStatus m117 : 33|1@1+ (1,0) [0|0] "" Vector__XXX
 SG_ VCFRONT1_a118_FRONTIPC_LVBMS_statusLow m118 : 33|1@1+ (1,0) [0|0] "" Vector__XXX
 SG_ VCFRONT1_a191_frunkOpen m191 : 33|1@1+ (1,0) [0|0] "" Vector__XXX
 SG_ VCFRONT1_a252_busVoltage m252 : 33|10@1+ (0.025,0) [0|0] "" Vector__XXX
 SG_ VCFRONT1_a475_deviceOvertemperature m475 : 33|1@1+ (1,0) [0|0] "" Vector__XXX
 SG_ VCFRONT1_a490_VDSFailure m490 : 33|1@1+ (1,0) [0|0] "" Vector__XXX
 SG_ VCFRONT1_a491_ovcThr m491 : 33|5@1+ (1,0) [0|0] "" Vector__XXX
 SG_ VCFRONT1_a016_NVMMVersionMismatch m16 : 34|1@1+ (1,0) [0|0] "" Vector__XXX
 SG_ VCFRONT1_a113_FRONTIPC_status2 m113 : 34|1@1+ (1,0) [0|0] "" Vector__XXX
 SG_ VCFRONT1_a117_BATTIPC_status m117 : 34|1@1+ (1,0) [0|0] "" Vector__XXX
 SG_ VCFRONT1_a118_FRONTIPC_LVBMS_statusHigh m118 : 34|1@1+ (1,0) [0|0] "" Vector__XXX
 SG_ VCFRONT1_a191_exitDriveWarningTimerExpired m191 : 34|1@1+ (1,0) [0|0] "" Vector__XXX
 SG_ VCFRONT1_a251_clampHighSideFailureReason m251 : 34|3@1+ (1,0) [0|0] "" Vector__XXX
 SG_ VCFRONT1_a475_ntcOvertemperature m475 : 34|1@1+ (1,0) [0|0] "" Vector__XXX
 SG_ VCFRONT1_a490_stuckOnVDS m490 : 34|10@1+ (1,0) [0|0] "" Vector__XXX
 SG_ VCFRONT1_a016_NVMMRecordUpgraded m16 : 35|1@1+ (1,0) [0|0] "" Vector__XXX
 SG_ VCFRONT1_a113_FRONTIPC_trackModeSettings m113 : 35|1@1+ (1,0) [0|0] "" Vector__XXX
 SG_ VCFRONT1_a117_BATTIPC_LVPowerState m117 : 35|1@1+ (1,0) [0|0] "" Vector__XXX
 SG_ VCFRONT1_a118_BATTIPC_LVBMS_statusLow m118 : 35|1@1+ (1,0) [0|0] "" Vector__XXX
 SG_ VCFRONT1_a191_NotEnoughPowerForSupport m191 : 35|1@1+ (1,0) [0|0] "" Vector__XXX
 SG_ VCFRONT1_a220_factoryMode m220 : 35|1@1+ (1,0) [0|0] "" Vector__XXX
 SG_ VCFRONT1_a249_ovClampMonitorVoltage1 m249 : 35|9@1+ (0.05,0) [0|0] "" Vector__XXX
 SG_ VCFRONT1_a475_vgsLow m475 : 35|1@1+ (1,0) [0|0] "" Vector__XXX
 SG_ VCFRONT1_a005_faults1 m5 : 36|12@1+ (1,0) [0|0] "" Vector__XXX
 SG_ VCFRONT1_a016_NVMMMemOverflow m16 : 36|1@1+ (1,0) [0|0] "" Vector__XXX
 SG_ VCFRONT1_a038_violationType m38 : 36|3@1+ (1,0) [0|0] "" Vector__XXX
 SG_ VCFRONT1_a113_FRONTIPC_tripPlanning m113 : 36|1@1+ (1,0) [0|0] "" Vector__XXX
 SG_ VCFRONT1_a117_FRONTIPC_lightingSecondary m117 : 36|1@1+ (1,0) [0|0] "" Vector__XXX
 SG_ VCFRONT1_a191_bmsState m191 : 36|4@1+ (1,0) [0|0] "" Vector__XXX
 SG_ VCFRONT1_a220_serviceMode m220 : 36|1@1+ (1,0) [0|0] "" Vector__XXX
 SG_ VCFRONT1_a475_chargePumpLow m475 : 36|1@1+ (1,0) [0|0] "" Vector__XXX
 SG_ VCFRONT1_a016_NVMMWriteFailed m16 : 37|1@1+ (1,0) [0|0] "" Vector__XXX
 SG_ VCFRONT1_a113_FRONTIPC_vehicleControlThermal m113 : 37|1@1+ (1,0) [0|0] "" Vector__XXX
 SG_ VCFRONT1_a117_BATTIPC_lightingSecondary m117 : 37|1@1+ (1,0) [0|0] "" Vector__XXX
 SG_ VCFRONT1_a214_filteredCurrent m214 : 37|10@1- (0.1,0) [0|0] "" Vector__XXX
 SG_ VCFRONT1_a251_rationalityPcsShutdownCheckResult m251 : 37|2@1+ (1,0) [0|0] "" Vector__XXX
 SG_ VCFRONT1_a253_ovClampTvsDiodeVoltage2 m253 : 37|9@1+ (0.025,0) [0|0] "" Vector__XXX
 SG_ VCFRONT1_a475_watchdog m475 : 37|1@1+ (1,0) [0|0] "" Vector__XXX
 SG_ VCFRONT1_a113_FRONTIPC_tpmsRCPsetting m113 : 38|1@1+ (1,0) [0|0] "" Vector__XXX
 SG_ VCFRONT1_a117_FRONTIPC_windowStatus m117 : 38|1@1+ (1,0) [0|0] "" Vector__XXX
 SG_ VCFRONT1_a250_ovClampBusVoltage m250 : 38|10@1+ (0.025,0) [0|0] "" Vector__XXX
 SG_ VCFRONT1_a475_spiNotDone m475 : 38|1@1+ (1,0) [0|0] "" Vector__XXX
 SG_ VCFRONT1_a491_hshtThr m491 : 38|4@1+ (1,0) [0|0] "" Vector__XXX
 SG_ VCFRONT1_a058_prevREstimate m58 : 39|12@1+ (0.00061,0) [0|0] "" Vector__XXX
 SG_ VCFRONT1_a113_FRONTIPC_autopilotControl m113 : 39|1@1+ (1,0) [0|0] "" Vector__XXX
 SG_ VCFRONT1_a117_BATTIPC_systemStatus m117 : 39|1@1+ (1,0) [0|0] "" Vector__XXX
 SG_ VCFRONT1_a475_csUndervoltage m475 : 39|1@1+ (1,0) [0|0] "" Vector__XXX
 SG_ VCFRONT1_a022_TaskInitError2 m22 : 40|8@1+ (1,0) [0|0] "" Vector__XXX
 SG_ VCFRONT1_a031_uds_bytes_3 m31 : 40|8@1+ (1,0) [0|0] "" Vector__XXX
 SG_ VCFRONT1_a038_faultSource m38 : 40|7@1+ (1,0) [0|0] "" Vector__XXX
 SG_ VCFRONT1_a041_CPULoad100msTask m41 : 40|8@1+ (1,0) [0|0] "" Vector__XXX
 SG_ VCFRONT1_a042_Usage1000msTask m42 : 40|8@1+ (1,0) [0|0] "" Vector__XXX
 SG_ VCFRONT1_a043_CallTrace1 m43 : 40|24@1+ (1,0) [0|0] "" Vector__XXX
 SG_ VCFRONT1_a044_CallTrace1 m44 : 40|24@1+ (1,0) [0|0] "" Vector__XXX
 SG_ VCFRONT1_a045_CallTrace1 m45 : 40|24@1+ (1,0) [0|0] "" Vector__XXX
 SG_ VCFRONT1_a046_CallTrace1 m46 : 40|24@1+ (1,0) [0|0] "" Vector__XXX
 SG_ VCFRONT1_a059_current m59 : 40|12@1+ (0.05,0) [0|0] "" Vector__XXX
 SG_ VCFRONT1_a063_disconnected m63 : 40|1@1+ (1,0) [0|0] "" Vector__XXX
 SG_ VCFRONT1_a113_FRONTIPC_vehicleControl3 m113 : 40|1@1+ (1,0) [0|0] "" Vector__XXX
 SG_ VCFRONT1_a188_timeNotSleeping m188 : 40|6@1+ (1,0) [0|0] "" Vector__XXX
 SG_ VCFRONT1_a220_unhealthyReason m220 : 40|5@1+ (1,0) [0|0] "" Vector__XXX
 SG_ VCFRONT1_a251_rationalityPcsShutdownFailureReason m251 : 40|3@1+ (1,0) [0|0] "" Vector__XXX
 SG_ VCFRONT1_a475_configIncorrect m475 : 40|1@1+ (1,0) [0|0] "" Vector__XXX
 SG_ VCFRONT1_a581_QF m581 : 40|10@1+ (0.0005,0) [0|0] "" Vector__XXX
 SG_ VCFRONT1_a590_vcrightBTerm m590 : 40|8@1- (1,-78) [0|0] "" Vector__XXX
 SG_ VCFRONT1_a596_vcrightCutoffBTerm m596 : 40|8@1- (1,-78) [0|0] "" Vector__XXX
 SG_ VCFRONT1_a063_indeterminate m63 : 41|1@1+ (1,0) [0|0] "" Vector__XXX
 SG_ VCFRONT1_a113_FRONTIPC_driverAssistMapData m113 : 41|1@1+ (1,0) [0|0] "" Vector__XXX
 SG_ VCFRONT1_a475_bufferFull m475 : 41|1@1+ (1,0) [0|0] "" Vector__XXX
 SG_ VCFRONT1_a063_stuckActive m63 : 42|1@1+ (1,0) [0|0] "" Vector__XXX
 SG_ VCFRONT1_a113_BATTIPC_driverAssistMapData m113 : 42|1@1+ (1,0) [0|0] "" Vector__XXX
 SG_ VCFRONT1_a475_hitAlertRateLimit m475 : 42|1@1+ (1,0) [0|0] "" Vector__XXX
 SG_ VCFRONT1_a491_vdsThr m491 : 42|5@1+ (1,0) [0|0] "" Vector__XXX
 SG_ VCFRONT1_a063_faulted m63 : 43|1@1+ (1,0) [0|0] "" Vector__XXX
 SG_ VCFRONT1_a113_FRONTIPC_chassisControl m113 : 43|1@1+ (1,0) [0|0] "" Vector__XXX
 SG_ VCFRONT1_a251_testTimedOut m251 : 43|1@1+ (1,0) [0|0] "" Vector__XXX
 SG_ VCFRONT1_a252_dcdcEnableLineVoltage m252 : 43|10@1+ (0.025,0) [0|0] "" Vector__XXX
 SG_ VCFRONT1_a475_hwlo m475 : 43|1@1+ (1,0) [0|0] "" Vector__XXX
 SG_ VCFRONT1_a249_ovClampMonitorVoltage2 m249 : 44|9@1+ (0.05,0) [0|0] "" Vector__XXX
 SG_ VCFRONT1_a475_dinState m475 : 44|1@1+ (1,0) [0|0] "" Vector__XXX
 SG_ VCFRONT1_a490_stuckOnFinished m490 : 44|1@1+ (1,0) [0|0] "" Vector__XXX
 SG_ VCFRONT1_a475_enable m475 : 45|1@1+ (1,0) [0|0] "" Vector__XXX
 SG_ VCFRONT1_a490_stuckOnFailure m490 : 45|1@1+ (1,0) [0|0] "" Vector__XXX
 SG_ VCFRONT1_a188_CANAfterQuiet m188 : 46|1@1+ (1,0) [0|0] "" Vector__XXX
 SG_ VCFRONT1_a253_ovClampTvsDiodeVoltage3 m253 : 46|9@1+ (0.025,0) [0|0] "" Vector__XXX
 SG_ VCFRONT1_a490_hardShortThresholdReached m490 : 46|1@1+ (1,0) [0|0] "" Vector__XXX
 SG_ VCFRONT1_a490_softShortThresholdReached m490 : 47|1@1+ (1,0) [0|0] "" Vector__XXX
 SG_ VCFRONT1_a491_ntcThr m491 : 47|4@1+ (1,0) [0|0] "" Vector__XXX
 SG_ VCFRONT1_a003_Data m3 : 48|16@1+ (1,0) [0|0] "" Vector__XXX
 SG_ VCFRONT1_a022_TaskInitError3 m22 : 48|8@1+ (1,0) [0|0] "" Vector__XXX
 SG_ VCFRONT1_a031_uds_bytes_4 m31 : 48|8@1+ (1,0) [0|0] "" Vector__XXX
 SG_ VCFRONT1_a041_CPULoad1000msTask m41 : 48|8@1+ (1,0) [0|0] "" Vector__XXX
 SG_ VCFRONT1_a042_UsageUDSTask m42 : 48|8@1+ (1,0) [0|0] "" Vector__XXX
 SG_ VCFRONT1_a127_iBoosterEFuseTemp m127 : 48|11@1+ (0.125,-40) [0|0] "" Vector__XXX
 SG_ VCFRONT1_a128_vcrightEFuseTemp m128 : 48|11@1+ (0.125,-40) [0|0] "" Vector__XXX
 SG_ VCFRONT1_a129_pcsEFuseTemp m129 : 48|11@1+ (0.125,-40) [0|0] "" Vector__XXX
 SG_ VCFRONT1_a130_autopilot2EFuseTemp m130 : 48|11@1+ (0.125,-40) [0|0] "" Vector__XXX
 SG_ VCFRONT1_a132_epas2EFuseTemp m132 : 48|11@1+ (0.125,-40) [0|0] "" Vector__XXX
 SG_ VCFRONT1_a250_ovClampReferenceVoltage m250 : 48|7@1+ (0.025,0) [0|0] "" Vector__XXX
 SG_ VCFRONT1_a482_lvBridgeEFuseTemp m482 : 48|11@1+ (0.125,-40) [0|0] "" Vector__XXX
 SG_ VCFRONT1_a489_currentSenseVoltageDiff m489 : 48|8@1+ (1,0) [0|0] "" Vector__XXX
 SG_ VCFRONT1_a490_currentSenseVoltageDiff m490 : 48|8@1+ (1,0) [0|0] "" Vector__XXX
 SG_ VCFRONT1_a578_vbusFusedLoadShedRemainingRetries m578 : 48|8@1+ (1,0) [0|0] "" Vector__XXX
 SG_ VCFRONT1_a590_vcrightCTerm m590 : 48|16@1- (50,0) [0|0] "" Vector__XXX
 SG_ VCFRONT1_a591_vcrightMaxCount m591 : 48|5@1+ (1,0) [0|0] "" Vector__XXX
 SG_ VCFRONT1_a596_vcrightCutoffCTerm m596 : 48|16@1- (50,0) [0|0] "" Vector__XXX
 SG_ VCFRONT1_a597_vcrightCutoffMaxCount m597 : 48|5@1+ (1,0) [0|0] "" Vector__XXX
 SG_ VCFRONT1_a581_calibratedVoltageOffset m581 : 50|10@1- (0.002,0) [0|0] "" Vector__XXX
 SG_ VCFRONT1_a058_newREstimate m58 : 51|12@1+ (0.00061,0) [0|0] "" Vector__XXX
 SG_ VCFRONT1_a491_wdTime m491 : 51|2@1+ (1,0) [0|0] "" Vector__XXX
 SG_ VCFRONT1_a249_ovClampMonitorVoltage3 m249 : 53|9@1+ (0.05,0) [0|0] "" Vector__XXX
 SG_ VCFRONT1_a252_ovClampMonitorChannel m252 : 53|2@1+ (1,0) [0|0] "" Vector__XXX
 SG_ VCFRONT1_a491_uvThr m491 : 53|2@1+ (1,0) [0|0] "" Vector__XXX
 SG_ VCFRONT1_a250_ovClampMonitorVoltage1 m250 : 55|9@1+ (0.05,0) [0|0] "" Vector__XXX
 SG_ VCFRONT1_a252_ovClampMonitorVoltage m252 : 55|9@1+ (0.05,0) [0|0] "" Vector__XXX
 SG_ VCFRONT1_a491_ccmVoutThr m491 : 55|3@1+ (1,0) [0|0] "" Vector__XXX
 SG_ VCFRONT1_a022_TaskInitError4 m22 : 56|8@1+ (1,0) [0|0] "" Vector__XXX
 SG_ VCFRONT1_a031_uds_bytes_5 m31 : 56|8@1+ (1,0) [0|0] "" Vector__XXX
 SG_ VCFRONT1_a041_CPULoadNVMMTask m41 : 56|8@1+ (1,0) [0|0] "" Vector__XXX
 SG_ VCFRONT1_a042_UsageNVMMTask m42 : 56|8@1+ (1,0) [0|0] "" Vector__XXX
 SG_ VCFRONT1_a253_ambientTemperature m253 : 56|8@1+ (0.5,-40) [0|0] "" Vector__XXX
 SG_ VCFRONT1_a490_currentSenseFinished m490 : 56|1@1+ (1,0) [0|0] "" Vector__XXX
 SG_ VCFRONT1_a490_currentSenseFailure m490 : 57|1@1+ (1,0) [0|0] "" Vector__XXX
 SG_ VCFRONT1_a491_csUvRetryT m491 : 58|2@1+ (1,0) [0|0] "" Vector__XXX
 SG_ VCFRONT1_a128_vcrightEFuseRemainingRetries m128 : 59|4@1+ (1,0) [0|0] "" Vector__XXX
 SG_ VCFRONT1_a129_pcsEFuseRemainingRetries m129 : 59|4@1+ (1,0) [0|0] "" Vector__XXX
 SG_ VCFRONT1_a130_autopilot2EFuseRemainingRetries m130 : 59|4@1+ (1,0) [0|0] "" Vector__XXX
 SG_ VCFRONT1_a058_faultReason m58 : 63|1@1+ (1,0) [0|0] "" Vector__XXX

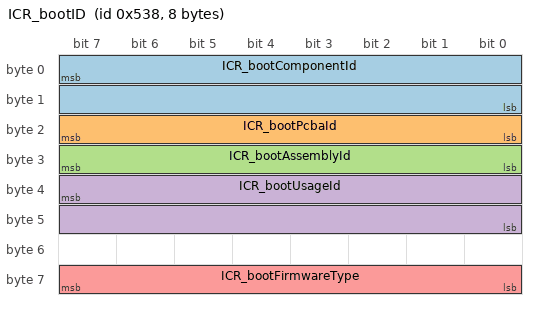
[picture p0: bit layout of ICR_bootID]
BO_ 1336 ICR_bootID: 8 Vector__XXX
 SG_ ICR_bootComponentId : 7|16@0+ (1,0) [0|0] "" Vector__XXX
 SG_ ICR_bootPcbaId : 23|8@0+ (1,0) [0|0] "" Vector__XXX
 SG_ ICR_bootAssemblyId : 31|8@0+ (1,0) [0|0] "" Vector__XXX
 SG_ ICR_bootUsageId : 39|16@0+ (1,0) [0|0] "" Vector__XXX
 SG_ ICR_bootFirmwareType : 63|8@0+ (1,0) [0|0] "" Vector__XXX
